VERSION "HNNBNNNYNNNNNNNNNNNNNNNNNNNNNNNNNNNNNNNNNN/4/%%%/4/'%**4NNN///"

NS_ :

BS_:

BU_: ecu_pri3_1 ecu_pri3_2 ecu_sec1_1 ecu_pri1_1 ecu_sec1_2 unused_8 unused_2 ecu_sec3_2 ecu_sec3_1 unused_1 unused_4 unused_9 unused_3 ecu_pri3_3 unused_6 unused_5 unused_7 measure

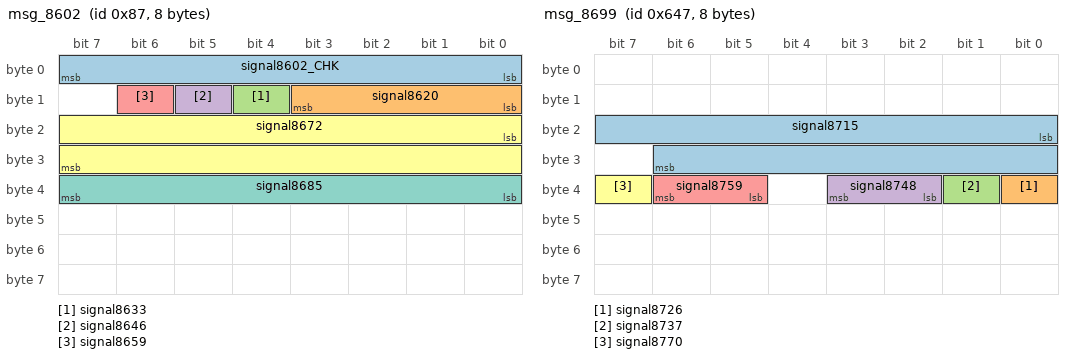
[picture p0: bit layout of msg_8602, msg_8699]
BO_ 135 msg_8602: 8 ecu_sec3_1
 SG_ signal8602_CHK : 0|8@1+ (1,0) [0|255] ""  ecu_sec1_2,unused_8,unused_2,measure
 SG_ signal8620 : 8|4@1+ (1,0) [0|15] ""  ecu_sec1_2,unused_8,unused_2,measure
 SG_ signal8633 : 12|1@1+ (1,0) [0|1] ""  ecu_sec1_2,unused_8,unused_2,measure
 SG_ signal8646 : 13|1@1+ (1,0) [0|1] ""  ecu_sec1_2,unused_8,unused_2,measure
 SG_ signal8659 : 14|1@1+ (1,0) [0|1] ""  ecu_sec1_2,unused_8,unused_2,measure
 SG_ signal8672 : 16|16@1+ (0.25,0) [0|16383] "1/min"  ecu_sec1_2,unused_8,unused_2,measure
 SG_ signal8685 : 32|8@1+ (0.4,0) [0|101.6] "%"  ecu_sec1_2,unused_8,unused_2,measure

BO_ 1607 msg_8699: 8 ecu_sec3_1
 SG_ signal8715 : 16|15@1- (1,0) [0|32766] ""  ecu_pri1_1,measure
 SG_ signal8726 : 32|1@1+ (1,0) [0|1] ""  ecu_pri1_1,measure
 SG_ signal8737 : 33|1@1+ (1,0) [0|1] ""  ecu_pri1_1,measure
 SG_ signal8748 : 34|2@1+ (1,0) [0|3] ""  ecu_pri1_1,measure
 SG_ signal8759 : 37|2@1+ (1,0) [0|3] ""  ecu_pri1_1,measure
 SG_ signal8770 : 39|1@1- (1,0) [0|1] ""  ecu_pri1_1,measure

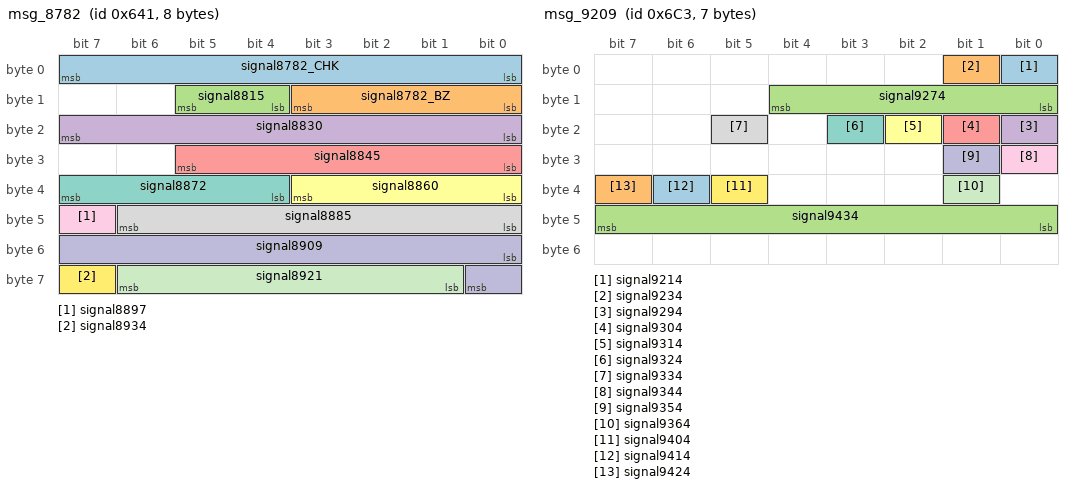
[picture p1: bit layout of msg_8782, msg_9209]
BO_ 1601 msg_8782: 8 ecu_sec3_1
 SG_ signal8782_CHK : 0|8@1+ (1,0) [0|255] ""  ecu_pri1_1,ecu_sec1_2,unused_8,unused_2,measure
 SG_ signal8782_BZ : 8|4@1+ (1,0) [0|15] ""  ecu_pri1_1,ecu_sec1_2,unused_8,unused_2,measure
 SG_ signal8815 : 12|2@1+ (1,0) [0|3] ""  ecu_pri3_2,ecu_pri1_1,ecu_sec1_2,unused_8,unused_2,measure
 SG_ signal8830 : 16|8@1+ (1,0) [0|255] ""  ecu_pri3_2,ecu_pri1_1,ecu_sec1_2,unused_8,unused_2,measure
 SG_ signal8845 : 24|6@1+ (1,0) [0|63] ""  ecu_pri3_2,ecu_pri1_1,ecu_sec1_2,unused_8,unused_2,measure
 SG_ signal8860 : 32|4@1+ (1,0) [0|15] ""  ecu_pri3_2,ecu_pri1_1,measure
 SG_ signal8872 : 36|4@1+ (1,0) [0|15] ""  ecu_pri3_2,ecu_pri1_1,unused_6,measure
 SG_ signal8885 : 40|7@1+ (0.1,0) [0|12.7] "l"  ecu_pri3_2,ecu_pri1_1,measure
 SG_ signal8897 : 47|1@1+ (1,0) [0|1] ""  ecu_pri3_2,ecu_pri1_1,measure
 SG_ signal8909 : 48|9@1+ (1,0) [0|511] "kW"  ecu_pri3_2,ecu_pri1_1,measure
 SG_ signal8921 : 57|6@1+ (1,0) [0|63] ""  ecu_pri1_1,ecu_sec1_2,unused_8,measure
 SG_ signal8934 : 63|1@1+ (1,0) [0|1] ""  ecu_pri1_1,measure

BO_ 1090 msg_8946: 1 unused_9
 SG_ signal8951 : 0|1@1+ (1,0) [0|1] ""  ecu_pri1_1,measure

BO_ 1753 msg_8963: 7 ecu_pri3_2
 SG_ signal9108 : 24|1@1+ (1,0) [0|1] ""  unused_7,measure
 SG_ signal9168 : 36|1@1+ (1,0) [0|1] ""  unused_7,measure

BO_ 1731 msg_9209: 7 ecu_sec1_1
 SG_ signal9214 : 0|1@1+ (1,0) [0|1] ""  ecu_pri3_2,ecu_sec1_1,ecu_pri1_1,ecu_sec1_2,unused_8,unused_2,ecu_sec3_1,unused_1,unused_4,unused_6,measure
 SG_ signal9234 : 1|1@1+ (1,0) [0|1] ""  unused_7,measure
 SG_ signal9274 : 8|5@1+ (1,0) [0|31] ""  unused_7,measure
 SG_ signal9294 : 16|1@1+ (1,0) [0|1] ""  unused_7,measure
 SG_ signal9304 : 17|1@1+ (1,0) [0|1] ""  unused_7,measure
 SG_ signal9314 : 18|1@1+ (1,0) [0|1] ""  unused_7,measure
 SG_ signal9324 : 19|1@1+ (1,0) [0|1] ""  unused_7,measure
 SG_ signal9334 : 21|1@1+ (1,0) [0|1] ""  unused_7,measure
 SG_ signal9344 : 24|1@1+ (1,0) [0|1] ""  unused_7,measure
 SG_ signal9354 : 25|1@1+ (1,0) [0|1] ""  unused_7,measure
 SG_ signal9364 : 33|1@1+ (1,0) [0|1] ""  unused_7,measure
 SG_ signal9404 : 37|1@1+ (1,0) [0|1] ""  unused_7,measure
 SG_ signal9414 : 38|1@1+ (1,0) [0|1] ""  unused_7,measure
 SG_ signal9424 : 39|1@1+ (1,0) [0|1] ""  unused_7,measure
 SG_ signal9434 : 40|8@1+ (1,0) [0|255] ""  unused_7,measure

BO_ 1728 msg_9445: 7 ecu_pri1_1
 SG_ signal9450 : 0|1@1+ (1,0) [0|1] ""  ecu_pri3_2,ecu_sec1_1,ecu_pri1_1,ecu_sec1_2,unused_8,unused_2,ecu_sec3_1,unused_1,unused_4,unused_6,measure
 SG_ signal9470 : 1|1@1+ (1,0) [0|1] ""  unused_7,measure
 SG_ signal9480 : 2|1@1+ (1,0) [0|1] ""  unused_7,measure
 SG_ signal9490 : 3|1@1+ (1,0) [0|1] ""  unused_7,measure
 SG_ signal9500 : 6|1@1+ (1,0) [0|1] ""  unused_7,measure
 SG_ signal9510 : 8|5@1+ (1,0) [0|31] ""  unused_7,measure
 SG_ signal9520 : 13|3@1+ (1,0) [0|7] ""  unused_7,measure
 SG_ signal9530 : 16|1@1+ (1,0) [0|1] ""  unused_7,measure
 SG_ signal9540 : 17|1@1+ (1,0) [0|1] ""  unused_7,measure
 SG_ signal9550 : 18|1@1+ (1,0) [0|1] ""  unused_7,measure
 SG_ signal9560 : 19|1@1+ (1,0) [0|1] ""  unused_7,measure
 SG_ signal9570 : 20|1@1+ (1,0) [0|1] ""  unused_7,measure
 SG_ signal9580 : 21|1@1+ (1,0) [0|1] ""  unused_7,measure
 SG_ signal9590 : 24|1@1+ (1,0) [0|1] ""  unused_7,measure
 SG_ signal9600 : 25|1@1+ (1,0) [0|1] ""  unused_7,measure
 SG_ signal9610 : 26|1@1+ (1,0) [0|1] ""  unused_7,measure
 SG_ signal9620 : 33|1@1+ (1,0) [0|1] ""  unused_7,measure
 SG_ signal9630 : 34|1@1+ (1,0) [0|1] ""  unused_7,measure
 SG_ signal9640 : 35|1@1+ (1,0) [0|1] ""  unused_7,measure
 SG_ signal9650 : 36|1@1+ (1,0) [0|1] ""  unused_7,measure
 SG_ signal9660 : 37|1@1+ (1,0) [0|1] ""  unused_7,measure
 SG_ signal9670 : 38|1@1+ (1,0) [0|1] ""  unused_7,measure
 SG_ signal9680 : 39|1@1+ (1,0) [0|1] ""  unused_7,measure
 SG_ signal9690 : 40|1@1+ (1,0) [0|1] ""  unused_7,measure
 SG_ signal9700 : 41|1@1+ (1,0) [0|1] ""  unused_7,measure
 SG_ signal9710 : 42|1@1+ (1,0) [0|1] ""  unused_7,measure
 SG_ signal9720 : 43|1@1+ (1,0) [0|1] ""  unused_7,measure
 SG_ signal9730 : 48|3@1+ (1,0) [0|7] ""  unused_7,measure

BO_ 1730 msg_9741: 7 ecu_sec1_2
 SG_ signal9746 : 0|1@1+ (1,0) [0|1] ""  ecu_pri3_2,ecu_sec1_1,ecu_pri1_1,ecu_sec1_2,unused_8,unused_2,ecu_sec3_1,unused_1,unused_4,unused_6,measure
 SG_ signal9766 : 1|1@1+ (1,0) [0|1] ""  unused_7,measure
 SG_ signal9776 : 2|1@1+ (1,0) [0|1] ""  unused_7,measure
 SG_ signal9786 : 3|1@1+ (1,0) [0|1] ""  unused_7,measure
 SG_ signal9796 : 6|1@1+ (1,0) [0|1] ""  unused_7,measure
 SG_ signal9806 : 8|5@1+ (1,0) [0|31] ""  unused_7,measure
 SG_ signal9816 : 13|3@1+ (1,0) [0|7] ""  unused_7,measure
 SG_ signal9826 : 16|1@1+ (1,0) [0|1] ""  unused_7,measure
 SG_ signal9836 : 17|1@1+ (1,0) [0|1] ""  unused_7,measure
 SG_ signal9846 : 18|1@1+ (1,0) [0|1] ""  unused_7,measure
 SG_ signal9856 : 24|1@1+ (1,0) [0|1] ""  unused_7,measure
 SG_ signal9866 : 25|1@1+ (1,0) [0|1] ""  unused_7,measure
 SG_ signal9876 : 26|1@1+ (1,0) [0|1] ""  unused_7,measure
 SG_ signal9886 : 27|1@1+ (1,0) [0|1] ""  unused_7,measure
 SG_ signal9896 : 28|1@1+ (1,0) [0|1] ""  unused_7,measure
 SG_ signal9906 : 29|1@1+ (1,0) [0|1] ""  unused_7,measure
 SG_ signal9916 : 33|1@1+ (1,0) [0|1] ""  unused_7,measure
 SG_ signal9926 : 34|1@1+ (1,0) [0|1] ""  unused_7,measure
 SG_ signal9936 : 35|1@1+ (1,0) [0|1] ""  unused_7,measure
 SG_ signal9946 : 36|1@1+ (1,0) [0|1] ""  unused_7,measure
 SG_ signal9956 : 37|1@1+ (1,0) [0|1] ""  unused_7,measure
 SG_ signal9966 : 38|1@1+ (1,0) [0|1] ""  unused_7,measure
 SG_ signal9976 : 39|1@1+ (1,0) [0|1] ""  unused_7,measure

BO_ 1729 msg_9987: 7 ecu_sec3_1
 SG_ signal9992 : 0|1@1+ (1,0) [0|1] ""  ecu_pri3_2,ecu_sec1_1,ecu_pri1_1,ecu_sec1_2,unused_8,unused_2,ecu_sec3_1,unused_1,unused_4,unused_6,measure
 SG_ signal10012 : 1|1@1+ (1,0) [0|1] ""  unused_7,measure
 SG_ signal10022 : 2|1@1+ (1,0) [0|1] ""  unused_7,measure
 SG_ signal10032 : 3|1@1+ (1,0) [0|1] ""  unused_7,measure
 SG_ signal10042 : 6|1@1+ (1,0) [0|1] ""  unused_7,measure
 SG_ signal10052 : 8|5@1+ (1,0) [0|31] ""  unused_7,measure
 SG_ signal10062 : 13|3@1+ (1,0) [0|7] ""  unused_7,measure
 SG_ signal10072 : 16|1@1+ (1,0) [0|1] ""  unused_7,measure
 SG_ signal10082 : 17|1@1+ (1,0) [0|1] ""  unused_7,measure
 SG_ signal10092 : 18|1@1+ (1,0) [0|1] ""  unused_7,measure
 SG_ signal10102 : 19|1@1+ (1,0) [0|1] ""  unused_7,measure
 SG_ signal10112 : 20|1@1+ (1,0) [0|1] ""  unused_7,measure
 SG_ signal10122 : 24|1@1+ (1,0) [0|1] ""  unused_7,measure
 SG_ signal10132 : 25|1@1+ (1,0) [0|1] ""  unused_7,measure
 SG_ signal10142 : 26|1@1+ (1,0) [0|1] ""  unused_7,measure
 SG_ signal10152 : 27|1@1+ (1,0) [0|1] ""  unused_7,measure
 SG_ signal10172 : 29|1@1+ (1,0) [0|1] ""  unused_7,measure
 SG_ signal10182 : 33|1@1+ (1,0) [0|1] ""  unused_7,measure
 SG_ signal10192 : 34|1@1+ (1,0) [0|1] ""  unused_7,measure
 SG_ signal10202 : 35|1@1+ (1,0) [0|1] ""  unused_7,measure
 SG_ signal10212 : 36|1@1+ (1,0) [0|1] ""  unused_7,measure
 SG_ signal10222 : 37|1@1+ (1,0) [0|1] ""  unused_7,measure
 SG_ signal10232 : 38|1@1+ (1,0) [0|1] ""  unused_7,measure
 SG_ signal10242 : 39|1@1+ (1,0) [0|1] ""  unused_7,measure

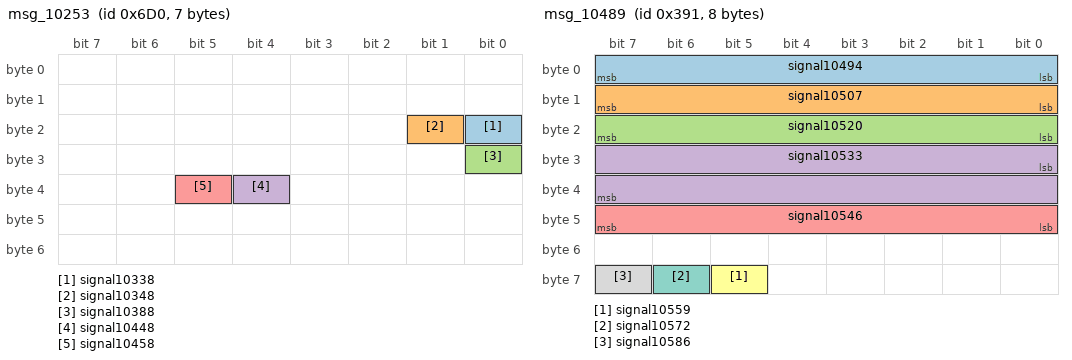
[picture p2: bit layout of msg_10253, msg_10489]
BO_ 1744 msg_10253: 7 unused_6
 SG_ signal10338 : 16|1@1+ (1,0) [0|1] ""  unused_7,measure
 SG_ signal10348 : 17|1@1+ (1,0) [0|1] ""  unused_7,measure
 SG_ signal10388 : 24|1@1+ (1,0) [0|1] ""  unused_7,measure
 SG_ signal10448 : 36|1@1+ (1,0) [0|1] ""  unused_7,measure
 SG_ signal10458 : 37|1@1+ (1,0) [0|1] ""  unused_7,measure

BO_ 913 msg_10489: 8 ecu_sec3_1
 SG_ signal10494 : 0|8@1+ (0.39215686275,0) [0|99.99825] "%"  ecu_sec1_2,unused_8,unused_2,measure
 SG_ signal10507 : 8|8@1+ (1,-40) [-40|215] "Celsius"  ecu_sec1_2,unused_8,unused_2,measure
 SG_ signal10520 : 16|8@1+ (0.39215686275,0) [0|99.99825] "%"  ecu_sec1_2,unused_8,unused_2,measure
 SG_ signal10533 : 24|16@1+ (0.39215686275,0) [0|25699.55025] "%"  ecu_sec1_2,unused_8,unused_2,measure
 SG_ signal10546 : 40|8@1+ (0.39215686275,0) [0|99.99825] "%"  ecu_sec1_2,unused_8,unused_2,measure
 SG_ signal10559 : 61|1@1+ (1,0) [0|1] ""  ecu_sec1_2,unused_8,unused_2,measure
 SG_ signal10572 : 62|1@1+ (1,0) [0|1] ""  ecu_pri1_1,ecu_sec1_2,unused_8,unused_2,measure
 SG_ signal10586 : 63|1@1+ (1,0) [0|1] ""  ecu_sec1_2,unused_8,unused_2,measure

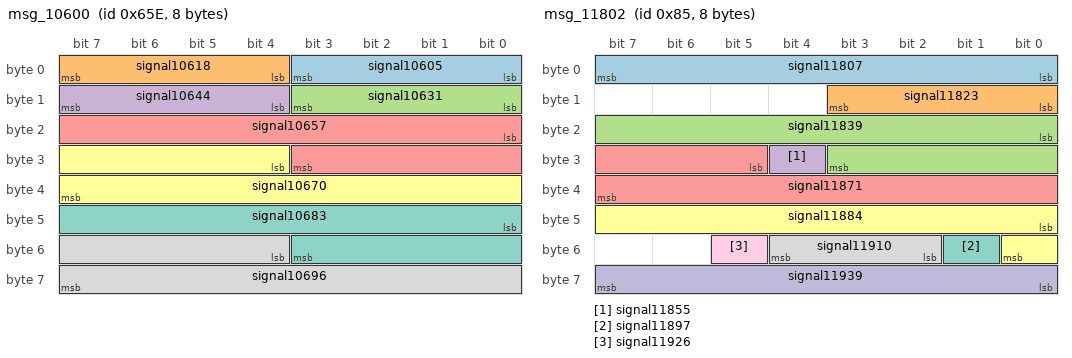
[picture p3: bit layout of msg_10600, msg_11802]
BO_ 1630 msg_10600: 8 ecu_pri1_1
 SG_ signal10605 : 0|4@1+ (1,0) [0|15] ""  ecu_sec3_1,unused_1,unused_4,measure
 SG_ signal10618 : 4|4@1+ (1,0) [0|15] ""  ecu_sec3_1,unused_1,unused_4,measure
 SG_ signal10631 : 8|4@1+ (1,0) [0|15] ""  ecu_sec3_1,unused_1,unused_4,measure
 SG_ signal10644 : 12|4@1+ (1,0) [0|15] ""  ecu_sec3_1,unused_1,unused_4,measure
 SG_ signal10657 : 16|12@1+ (0.5,0) [0|2047.5] "Ohm"  ecu_sec3_1,unused_1,unused_4,measure
 SG_ signal10670 : 28|12@1+ (0.5,0) [0|2047.5] "Ohm"  ecu_sec3_1,unused_1,unused_4,measure
 SG_ signal10683 : 40|12@1+ (0.5,0) [0|2047.5] "Ohm"  ecu_sec3_1,unused_1,unused_4,measure
 SG_ signal10696 : 52|12@1+ (0.5,0) [0|2047.5] "Ohm"  ecu_sec3_1,unused_1,unused_4,measure

BO_ 929 msg_10710: 8 ecu_pri1_1
 SG_ signal10715 : 0|6@1+ (1,0) [0|63] ""  ecu_sec1_2,unused_8,unused_2,measure
 SG_ signal10728 : 6|7@1+ (1,0) [0|127] ""  ecu_sec1_2,unused_8,unused_2,measure
 SG_ signal10741 : 13|5@1+ (1,0) [0|31] ""  ecu_sec1_2,unused_8,unused_2,measure
 SG_ signal10754 : 18|1@1+ (1,0) [0|1] ""  ecu_sec1_2,unused_8,unused_2,measure
 SG_ signal10767 : 19|3@1+ (1,0) [0|7] ""  ecu_sec1_2,unused_8,unused_2,measure
 SG_ signal10780 : 22|6@1+ (1,0) [0|63] ""  ecu_sec1_2,unused_8,unused_2,measure
 SG_ signal10793 : 28|6@1+ (1,0) [0|63] ""  ecu_sec1_2,unused_8,unused_2,measure
 SG_ signal10806 : 34|2@1+ (1,0) [0|3] ""  ecu_sec1_2,unused_8,unused_2,measure
 SG_ signal10819 : 36|7@1+ (1,0) [0|127] ""  ecu_sec1_2,unused_8,unused_2,measure
 SG_ signal10832 : 43|2@1+ (1,0) [0|3] ""  ecu_sec1_2,unused_8,unused_2,measure
 SG_ signal10845 : 45|8@1+ (1,0) [0|255] ""  ecu_sec1_2,unused_8,unused_2,measure
 SG_ signal10858 : 53|1@1+ (1,0) [0|1] ""  ecu_sec1_2,unused_8,unused_2,measure
 SG_ signal10871 : 54|5@1+ (1,0) [0|31] ""  ecu_sec1_2,unused_8,unused_2,measure
 SG_ signal10884 : 59|1@1+ (1,0) [0|1] ""  ecu_sec1_2,unused_8,unused_2,measure
 SG_ signal10897 : 60|1@1+ (1,0) [0|1] ""  ecu_sec1_2,unused_8,unused_2,measure
 SG_ signal10910 : 61|2@1+ (1,0) [0|3] ""  ecu_sec1_2,unused_8,unused_2,measure
 SG_ signal10923 : 63|1@1+ (1,0) [0|1] ""  ecu_sec1_2,unused_8,unused_2,measure

BO_ 930 msg_10937: 8 ecu_pri1_1
 SG_ signal10942 M : 0|2@1+ (1,0) [0|3] ""  ecu_sec1_2,unused_8,unused_2,measure
 SG_ signal10956 m0 : 2|6@1+ (1,0) [0|63] ""  ecu_sec1_2,unused_8,unused_2,measure
 SG_ signal10970 m1 : 2|6@1+ (1,0) [0|63] ""  ecu_sec1_2,unused_8,unused_2,measure
 SG_ signal10984 m2 : 2|6@1+ (1,0) [0|63] ""  ecu_sec1_2,unused_8,unused_2,measure
 SG_ signal10998 m3 : 2|6@1+ (1,0) [0|63] ""  ecu_sec1_2,unused_8,unused_2,measure
 SG_ signal11012 m0 : 8|8@1+ (1,0) [0|255] ""  ecu_sec1_2,unused_8,unused_2,measure
 SG_ signal11026 m1 : 8|7@1+ (1,0) [0|127] ""  ecu_sec1_2,unused_8,unused_2,measure
 SG_ signal11040 m2 : 8|5@1+ (1,0) [0|31] ""  ecu_sec1_2,unused_8,unused_2,measure
 SG_ signal11054 m3 : 8|2@1+ (1,0) [0|3] ""  ecu_sec1_2,unused_8,unused_2,measure
 SG_ signal11068 m3 : 10|10@1+ (1,0) [0|1023] ""  ecu_sec1_2,unused_8,unused_2,measure
 SG_ signal11110 m1 : 15|6@1+ (1,0) [0|63] ""  ecu_sec1_2,unused_8,unused_2,measure
 SG_ signal11138 m0 : 16|1@1+ (1,0) [0|1] ""  ecu_sec1_2,unused_8,unused_2,measure
 SG_ signal11152 m0 : 17|1@1+ (1,0) [0|1] ""  ecu_sec1_2,unused_8,unused_2,measure
 SG_ signal11180 m0 : 18|4@1+ (1,0) [0|15] ""  ecu_sec1_2,unused_8,unused_2,measure
 SG_ signal11208 m3 : 20|1@1+ (1,0) [0|1] ""  ecu_sec1_2,unused_8,unused_2,measure
 SG_ signal11222 m1 : 21|5@1+ (1,0) [0|31] ""  ecu_sec1_2,unused_8,unused_2,measure
 SG_ signal11236 m3 : 21|2@1+ (1,0) [0|3] ""  ecu_sec1_2,unused_8,unused_2,measure
 SG_ signal11250 m0 : 22|5@1+ (1,0) [0|31] ""  ecu_sec1_2,unused_8,unused_2,measure
 SG_ signal11278 m3 : 23|5@1+ (1,0) [0|31] ""  ecu_sec1_2,unused_8,unused_2,measure
 SG_ signal11292 m1 : 26|1@1+ (1,0) [0|1] ""  ecu_sec1_2,unused_8,unused_2,measure
 SG_ signal11306 m0 : 27|19@1+ (1,0) [0|524287] ""  ecu_sec1_2,unused_8,unused_2,measure
 SG_ signal11320 m1 : 27|2@1+ (1,0) [0|3] ""  ecu_sec1_2,unused_8,unused_2,measure
 SG_ signal11278_Typ m3 : 28|1@1+ (1,0) [0|1] ""  ecu_sec1_2,unused_8,unused_2,measure
 SG_ signal11362 m1 : 29|1@1+ (1,0) [0|1] ""  ecu_sec1_2,unused_8,unused_2,measure
 SG_ signal11376 m3 : 29|5@1+ (1,0) [0|31] ""  ecu_sec1_2,unused_8,unused_2,measure
 SG_ signal11390 m1 : 30|1@1+ (1,0) [0|1] ""  ecu_sec1_2,unused_8,unused_2,measure
 SG_ signal11404 m1 : 31|4@1+ (1,0) [0|15] ""  ecu_sec1_2,unused_8,unused_2,measure
 SG_ signal11418 m2 : 33|5@1+ (1,0) [0|31] ""  ecu_sec1_2,unused_8,unused_2,measure
 SG_ signal11432 m1 : 35|2@1+ (1,0) [0|3] ""  ecu_sec1_2,unused_8,unused_2,measure
 SG_ signal11446 m1 : 37|8@1+ (1,0) [0|255] ""  ecu_sec1_2,unused_8,unused_2,measure
 SG_ signal11460 m2 : 38|1@1+ (1,0) [0|1] ""  ecu_sec1_2,unused_8,unused_2,measure
 SG_ signal11516 m1 : 45|1@1+ (1,0) [0|1] ""  ecu_sec1_2,unused_8,unused_2,measure
 SG_ signal11530 m0 : 46|8@1+ (1,0) [0|255] ""  ecu_sec1_2,unused_8,unused_2,measure
 SG_ signal11544 m1 : 46|8@1+ (1,0) [0|255] ""  ecu_sec1_2,unused_8,unused_2,measure
 SG_ signal11586 m0 : 54|1@1+ (1,0) [0|1] ""  ecu_sec1_2,unused_8,unused_2,measure
 SG_ signal11544_Vorz m1 : 54|1@1+ (1,0) [0|1] ""  ecu_sec1_2,unused_8,unused_2,measure
 SG_ signal11614 m0 : 55|5@1+ (1,0) [0|31] ""  ecu_sec1_2,unused_8,unused_2,measure
 SG_ signal11628 m1 : 55|5@1+ (1,0) [0|31] ""  ecu_sec1_2,unused_8,unused_2,measure
 SG_ signal11642 m2 : 57|2@1+ (1,0) [0|3] ""  ecu_sec1_2,unused_8,unused_2,measure
 SG_ signal11656 m2 : 59|3@1+ (1,0) [0|7] ""  ecu_sec1_2,unused_8,unused_2,measure
 SG_ signal11614_Vorz m0 : 60|1@1+ (1,0) [0|1] ""  ecu_sec1_2,unused_8,unused_2,measure
 SG_ signal11684 m1 : 60|1@1+ (1,0) [0|1] ""  ecu_sec1_2,unused_8,unused_2,measure
 SG_ signal11698 m0 : 61|1@1+ (1,0) [0|1] ""  ecu_sec1_2,unused_8,unused_2,measure
 SG_ signal11712 m1 : 61|2@1+ (1,0) [0|3] ""  ecu_sec1_2,unused_8,unused_2,measure
 SG_ signal11726 m0 : 62|1@1+ (1,0) [0|1] ""  ecu_sec1_2,unused_8,unused_2,measure
 SG_ signal11740 m0 : 63|1@1+ (1,0) [0|1] ""  ecu_sec1_2,unused_8,unused_2,measure
 SG_ signal11754 m1 : 63|1@1+ (1,0) [0|1] ""  ecu_sec1_2,unused_8,unused_2,measure

BO_ 2033 msg_11769: 8 unused_7
 SG_ signal11769 : 0|64@1+ (1,0) [0|4294967295] ""  ecu_pri3_1,measure

BO_ 2041 msg_11786: 8 ecu_pri3_1
 SG_ signal11786 : 0|64@1+ (1,0) [0|1] ""  unused_7,measure

BO_ 133 msg_11802: 8 ecu_pri3_3
 SG_ signal11807 : 0|8@1+ (1,0) [0|255] ""  ecu_sec1_1,ecu_pri1_1,ecu_sec3_1,unused_1,unused_4,unused_3,measure
 SG_ signal11823 : 8|4@1+ (1,0) [0|15] ""  ecu_sec1_1,ecu_pri1_1,ecu_sec3_1,unused_1,unused_4,unused_3,measure
 SG_ signal11839 : 16|12@1+ (0.1,0) [0|409.3] "Degr"  ecu_sec1_1,ecu_pri1_1,ecu_sec3_1,unused_1,unused_4,unused_3,measure
 SG_ signal11855 : 28|1@1+ (1,0) [0|1] ""  ecu_sec1_1,ecu_pri1_1,ecu_sec3_1,unused_1,unused_4,unused_3,measure
 SG_ signal11871 : 29|11@1+ (0.1,0) [0|204.5] "Degr"  ecu_sec1_1,ecu_pri1_1,unused_3,measure
 SG_ signal11884 : 40|9@1+ (1,0) [0|510] ""  ecu_sec1_1,ecu_pri1_1,unused_3,measure
 SG_ signal11897 : 49|1@1+ (1,0) [0|1] ""  ecu_sec1_1,ecu_pri1_1,unused_3,measure
 SG_ signal11910 : 50|3@1+ (1,0) [0|7] ""  ecu_sec1_1,ecu_pri1_1,ecu_sec3_1,unused_1,unused_4,unused_3,measure
 SG_ signal11926 : 53|1@1+ (1,0) [0|1] ""  ecu_sec1_1,ecu_pri1_1,unused_3,measure
 SG_ signal11939 : 56|8@1+ (1,0) [0|255] ""  ecu_sec1_1,ecu_pri1_1,unused_3,measure

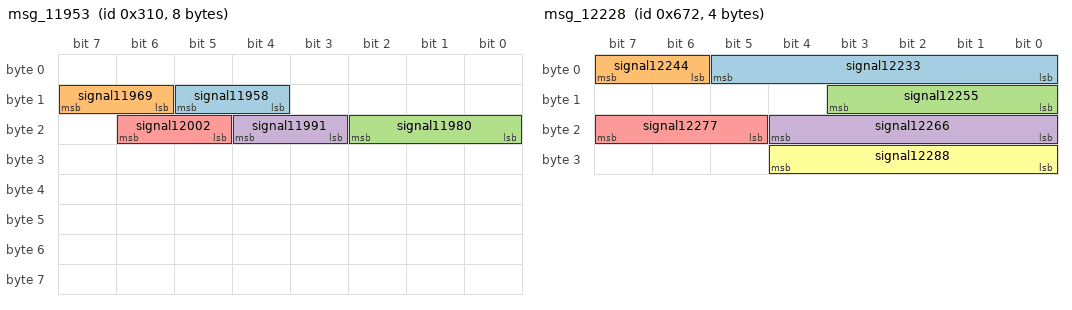
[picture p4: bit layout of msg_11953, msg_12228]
BO_ 784 msg_11953: 8 ecu_pri3_3
 SG_ signal11958 : 12|2@1+ (1,0) [0|3] ""  ecu_pri1_1,measure
 SG_ signal11969 : 14|2@1+ (1,0) [0|3] ""  ecu_pri1_1,measure
 SG_ signal11980 : 16|3@1+ (1,0) [0|7] ""  ecu_pri1_1,measure
 SG_ signal11991 : 19|2@1+ (1,0) [0|3] ""  ecu_pri1_1,measure
 SG_ signal12002 : 21|2@1+ (1,0) [0|3] ""  ecu_pri1_1,measure

BO_ 1313 msg_12014: 8 unused_6
 SG_ signal12019 : 0|1@1+ (1,0) [0|1] ""  ecu_pri1_1,measure
 SG_ signal12030 : 1|1@1+ (1,0) [0|1] ""  ecu_pri1_1,measure
 SG_ signal12041 : 2|1@1+ (1,0) [0|1] ""  ecu_pri1_1,measure
 SG_ signal12052 : 3|1@1+ (1,0) [0|1] ""  ecu_pri1_1,measure
 SG_ signal12063 : 4|1@1+ (1,0) [0|1] ""  ecu_pri1_1,measure
 SG_ signal12074 : 5|1@1+ (1,0) [0|1] ""  ecu_pri1_1,measure
 SG_ signal12085 : 6|1@1+ (1,0) [0|1] ""  ecu_pri1_1,ecu_sec3_1,unused_4,measure
 SG_ signal12098 : 8|6@1+ (1,0) [0|63] "min"  ecu_pri1_1,ecu_sec3_1,unused_4,measure
 SG_ signal12111 : 16|6@1+ (1,0) [0|63] ""  ecu_pri1_1,ecu_sec3_1,unused_4,measure
 SG_ signal12124 : 24|13@1+ (1,0) [0|8191] "ml"  ecu_pri1_1,measure
 SG_ signal12135 : 37|3@1+ (1,0) [0|7] ""  ecu_pri1_1,measure
 SG_ signal12146 : 40|8@1+ (1,0) [0|255] ""  ecu_pri1_1,measure
 SG_ signal12157 : 48|8@1+ (0.75,-40) [-40|142.25] "Celsius"  ecu_pri1_1,measure
 SG_ signal12168 : 59|1@1+ (1,0) [0|1] ""  ecu_pri1_1,ecu_sec3_1,unused_4,measure
 SG_ signal12181 : 60|1@1+ (1,0) [0|1] ""  ecu_pri1_1,measure
 SG_ signal12192 : 61|1@1+ (1,0) [0|1] ""  ecu_pri1_1,ecu_sec3_1,unused_4,measure
 SG_ signal12205 : 62|1@1+ (1,0) [0|1] ""  ecu_pri1_1,measure
 SG_ signal12216 : 63|1@1+ (1,0) [0|1] ""  ecu_pri1_1,measure

BO_ 1650 msg_12228: 4 unused_6
 SG_ signal12233 : 0|6@1+ (1,0) [0|63] ""  ecu_pri1_1,measure
 SG_ signal12244 : 6|2@1+ (1,0) [0|3] ""  ecu_pri1_1,measure
 SG_ signal12255 : 8|4@1+ (1,0) [0|15] ""  ecu_pri1_1,measure
 SG_ signal12266 : 16|5@1+ (1,0) [0|31] ""  ecu_pri1_1,measure
 SG_ signal12277 : 21|3@1+ (1,0) [0|7] ""  ecu_pri1_1,measure
 SG_ signal12288 : 24|5@1+ (1,0) [0|31] "Tag"  ecu_pri1_1,measure

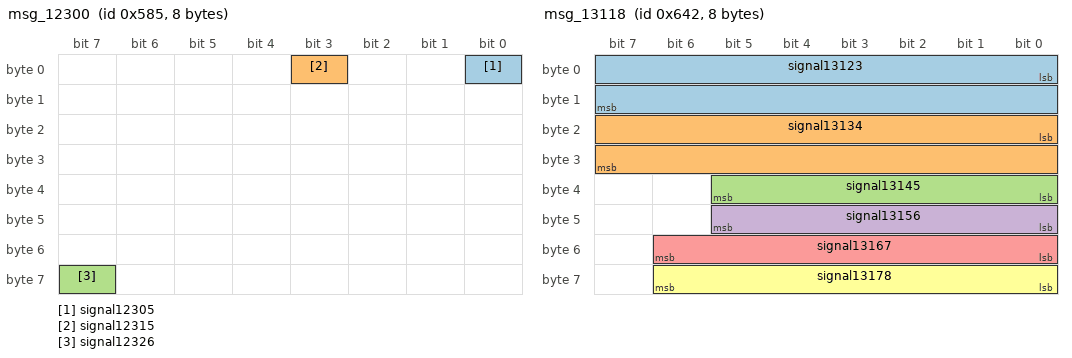
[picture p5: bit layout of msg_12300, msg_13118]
BO_ 1413 msg_12300: 8 ecu_pri1_1
 SG_ signal12305 : 0|1@1+ (1,0) [0|1] ""  unused_7,measure
 SG_ signal12315 : 3|1@1+ (1,0) [0|1] ""  unused_6,measure
 SG_ signal12326 : 63|1@1+ (1,0) [0|1] ""  unused_7,measure

BO_ 1209 msg_12337: 8 ecu_pri1_1
 SG_ signal12342 : 0|64@1+ (1,0) [0|1] ""  ecu_pri3_2,measure

BO_ 1215 msg_12371: 8 unused_6
 SG_ signal12376 : 0|64@1+ (1,0) [0|1] ""  ecu_pri1_1,measure

BO_ 1303 msg_12388: 8 unused_6
 SG_ signal12393 : 0|64@1+ (1,0) [0|1] ""  ecu_pri1_1,measure

BO_ 1214 msg_12405: 8 ecu_pri1_1
 SG_ signal12410 : 0|64@1+ (1,0) [0|1] ""  ecu_pri3_3,measure

BO_ 1231 msg_12422: 8 ecu_pri1_1
 SG_ signal12427 : 0|64@1+ (1,0) [0|1] ""  unused_6,measure

BO_ 768 msg_12456: 8 ecu_pri3_2
 SG_ signal12461 : 0|64@1+ (1,0) [0|1] ""  ecu_pri1_1,measure

BO_ 769 msg_12473: 8 ecu_pri3_2
 SG_ signal12478 : 0|64@1+ (1,0) [0|1] ""  ecu_pri1_1,measure

BO_ 770 msg_12490: 8 ecu_pri3_2
 SG_ signal12495 : 0|64@1+ (1,0) [0|1] ""  ecu_pri1_1,measure

BO_ 771 msg_12507: 8 ecu_pri3_2
 SG_ signal12512 : 0|64@1+ (1,0) [0|1] ""  ecu_pri1_1,measure

BO_ 772 msg_12524: 8 ecu_pri3_2
 SG_ signal12529 : 0|64@1+ (1,0) [0|1] ""  ecu_pri1_1,measure

BO_ 773 msg_12541: 8 ecu_pri3_2
 SG_ signal12546 : 0|64@1+ (1,0) [0|1] ""  ecu_pri1_1,measure

BO_ 774 msg_12558: 8 ecu_pri3_2
 SG_ signal12563 : 0|64@1+ (1,0) [0|1] ""  ecu_pri1_1,measure

BO_ 775 msg_12575: 8 ecu_pri3_2
 SG_ signal12580 : 0|64@1+ (1,0) [0|1] ""  ecu_pri1_1,measure

BO_ 537 msg_12592: 7 ecu_pri3_2
 SG_ signal12597 : 0|56@1+ (1,0) [0|1] ""  ecu_pri1_1,measure

BO_ 543 msg_12609: 7 ecu_pri1_1
 SG_ signal12614 : 0|56@1+ (1,0) [0|1] ""  unused_6,measure

BO_ 542 msg_12626: 7 ecu_pri3_3
 SG_ signal12631 : 0|56@1+ (1,0) [0|1] ""  ecu_pri1_1,measure

BO_ 559 msg_12643: 7 unused_6
 SG_ signal12643_Data : 0|56@1+ (1,0) [0|1] ""  ecu_pri1_1,measure

BO_ 512 msg_12660: 7 ecu_pri1_1
 SG_ signal12665 : 0|56@1+ (1,0) [0|1] ""  ecu_pri3_2,ecu_pri3_3,unused_6,measure

BO_ 1716 msg_12679: 8 ecu_pri1_1
 SG_ signal12684 M : 0|2@1+ (1,0) [0|3] ""  ecu_pri3_1,ecu_sec3_2,ecu_pri3_3,unused_6,measure
 SG_ signal12699 m0 : 8|8@1+ (1,0) [0|255] ""  ecu_pri3_1,unused_6,measure
 SG_ signal12712 m1 : 8|8@1+ (1,0) [0|255] ""  ecu_pri3_1,ecu_sec3_2,unused_6,measure
 SG_ signal128641 m2 : 8|8@1+ (1,0) [0|255] ""  ecu_pri3_1,ecu_sec3_2,unused_6,measure
 SG_ signal12740 m0 : 16|8@1+ (1,0) [0|255] ""  ecu_pri3_1,unused_6,measure
 SG_ signal12753 m1 : 16|8@1+ (1,0) [0|255] ""  ecu_pri3_1,ecu_sec3_2,unused_6,measure
 SG_ signal12767 m2 : 16|8@1+ (1,0) [0|255] ""  ecu_pri3_1,ecu_sec3_2,unused_6,measure
 SG_ signal12781 m0 : 24|8@1+ (1,0) [0|255] ""  ecu_pri3_1,unused_6,measure
 SG_ signal12794 m1 : 24|8@1+ (1,0) [0|255] ""  ecu_pri3_1,ecu_sec3_2,unused_6,measure
 SG_ signal128643 m2 : 24|8@1+ (1,0) [0|255] ""  ecu_pri3_1,ecu_sec3_2,unused_6,measure
 SG_ signal12822 m0 : 32|8@1+ (1,0) [0|255] ""  ecu_pri3_1,unused_6,measure
 SG_ signal12835 m1 : 32|8@1+ (1,0) [0|255] ""  ecu_pri3_1,ecu_sec3_2,unused_6,measure
 SG_ signal12849 m2 : 32|8@1+ (1,0) [0|255] ""  ecu_pri3_1,ecu_sec3_2,ecu_pri3_3,unused_6,measure
 SG_ signal12864 m0 : 40|8@1+ (1,0) [0|255] ""  ecu_pri3_1,ecu_sec3_2,unused_6,measure
 SG_ signal12878 m1 : 40|8@1+ (1,0) [0|255] ""  ecu_pri3_1,ecu_sec3_2,unused_6,measure
 SG_ signal128645 m2 : 40|8@1+ (1,0) [0|255] ""  ecu_pri3_1,ecu_sec3_2,ecu_pri3_3,unused_6,measure
 SG_ signal12907 m0 : 48|8@1+ (1,0) [0|255] ""  ecu_pri3_1,ecu_sec3_2,unused_6,measure
 SG_ signal12921 m1 : 48|8@1+ (1,0) [0|255] ""  ecu_pri3_1,ecu_sec3_2,unused_6,measure
 SG_ signal128646 m2 : 48|8@1+ (1,0) [0|255] ""  ecu_pri3_1,ecu_sec3_2,ecu_pri3_3,unused_6,measure
 SG_ signal12950 m0 : 56|8@1+ (1,0) [0|255] ""  ecu_pri3_1,ecu_sec3_2,unused_6,measure
 SG_ signal128640 m1 : 56|8@1+ (1,0) [0|255] ""  ecu_pri3_1,ecu_sec3_2,unused_6,measure
 SG_ signal128647 m2 : 56|8@1+ (1,0) [0|255] ""  ecu_pri3_1,ecu_sec3_2,ecu_pri3_3,unused_6,measure

BO_ 912 msg_12994: 4 ecu_sec1_2
 SG_ signal12999 M : 0|1@1+ (1,0) [0|1] ""  ecu_pri1_1,measure
 SG_ signal13011 m0 : 1|4@1+ (1,0) [0|15] ""  ecu_pri1_1,measure
 SG_ signal13023 m0 : 8|4@1+ (1,0) [0|15] ""  ecu_pri1_1,measure
 SG_ signal13035 m1 : 8|4@1+ (1,0) [0|15] ""  ecu_pri1_1,measure
 SG_ signal13047 m0 : 12|4@1+ (1,0) [0|15] ""  ecu_pri1_1,measure
 SG_ signal13059 m1 : 12|4@1+ (1,0) [0|15] ""  ecu_pri1_1,measure
 SG_ signal13071 : 16|1@1+ (1,0) [0|1] ""  ecu_pri1_1,measure
 SG_ signal13082 m0 : 17|1@1+ (1,0) [0|1] ""  ecu_pri1_1,measure
 SG_ signal13094 m1 : 18|1@1+ (1,0) [0|1] ""  ecu_pri1_1,measure
 SG_ signal13106 : 21|3@1+ (1,0) [0|7] ""  ecu_pri1_1,measure

BO_ 1602 msg_13118: 8 ecu_sec3_1
 SG_ signal13123 : 0|16@1+ (2E-008,0) [0|0] ""  ecu_pri1_1,measure
 SG_ signal13134 : 16|16@1+ (2E-008,0) [0|0] ""  ecu_pri1_1,measure
 SG_ signal13145 : 32|6@1+ (1,0) [0|63] "month"  ecu_pri1_1,measure
 SG_ signal13156 : 40|6@1+ (1,0) [0|63] "month"  ecu_pri1_1,measure
 SG_ signal13167 : 48|7@1+ (1000,0) [0|127000] "km"  ecu_pri1_1,measure
 SG_ signal13178 : 56|7@1+ (1000,0) [0|127000] "km"  ecu_pri1_1,measure

BO_TX_BU_ 135 : ecu_sec3_1,unused_1,unused_4;
BO_TX_BU_ 1601 : ecu_sec3_1,unused_1,unused_4;
BO_TX_BU_ 1730 : ecu_sec1_2,unused_8,unused_2;
BO_TX_BU_ 1729 : ecu_sec3_1,unused_1,unused_4;
BO_TX_BU_ 913 : ecu_sec3_1,unused_1,unused_4;
BO_TX_BU_ 768 : ecu_pri3_2,ecu_pri3_3,unused_6;
BO_TX_BU_ 769 : ecu_pri3_2,ecu_pri3_3,unused_6;
BO_TX_BU_ 770 : ecu_pri3_2,ecu_pri3_3,unused_6;
BO_TX_BU_ 771 : ecu_pri3_2,ecu_pri3_3,unused_6;
BO_TX_BU_ 772 : ecu_pri3_2,ecu_pri3_3,unused_6;
BO_TX_BU_ 773 : ecu_pri3_2,ecu_pri3_3,unused_6;
BO_TX_BU_ 774 : ecu_pri3_2,ecu_pri3_3,unused_6;
BO_TX_BU_ 775 : ecu_pri3_2,ecu_pri3_3,unused_6;
BO_TX_BU_ 912 : ecu_sec1_2,unused_8,unused_2,ecu_sec3_1,unused_1,unused_4;
BO_TX_BU_ 1602 : ecu_sec3_1,unused_1,unused_4;
BA_DEF_ BO_  "GenMsgAutoGenDsp" ENUM  "No","Yes";
BA_DEF_ BO_  "GenMsgAutoGenSnd" ENUM  "No","Yes";
BA_DEF_ BO_  "GenMsgCycleTime" INT 0 65535;
BA_DEF_ BO_  "GenMsgCycleTimeFast" INT 0 65535;
BA_DEF_ BO_  "GenMsgDelayTime" INT 0 100000;
BA_DEF_ BO_  "GenMsgILSupport" ENUM  "No","Yes";
BA_DEF_ BO_  "GenMsgNrOfRepetition" INT 0 100;
BA_DEF_ BO_  "GenMsgSendType" ENUM  "cyclicX","spontanX","cyclicIfActiveX","spontanWithDelay","cyclicAndSpontanX","cyclicAndSpontanWithDelay","spontanWithRepetition","cyclicIfActiveAndSpontanWD","cyclicIfActiveFast","cyclicWithRepeatOnDemand";
BA_DEF_ BO_  "GenMsgStartDelayTime" INT 0 100000;
BA_DEF_ BO_  "NmMessage" ENUM  "No","Yes";
BA_DEF_ BO_  "NmhMessage" ENUM  "No","Yes";
BA_DEF_ BO_  "NWM-Botschaft" ENUM  "No","Yes";
BA_DEF_ BO_  "signal24915" HEX 0 255;
BA_DEF_ BO_  "signal24909" ENUM  "No","Yes";
BA_DEF_ BO_  "signal24903" ENUM  "No","Yes";
BA_DEF_ BO_  "signal24897" ENUM  "No","Yes";
BA_DEF_ BO_  "Timeoutzeit" INT 0 1000000;
BA_DEF_ BO_  "signal24891" ENUM  "No","Yes";
BA_DEF_ SG_  "GenSigAltSetting" STRING ;
BA_DEF_ SG_  "GenSigAssignSetting" STRING ;
BA_DEF_ SG_  "GenSigAutoGenDsp" ENUM  "No","Yes";
BA_DEF_ SG_  "GenSigAutoGenSnd" ENUM  "No","Yes";
BA_DEF_ SG_  "GenSigConditionalSend" STRING ;
BA_DEF_ SG_  "GenSigEnvVarType" ENUM  "int","float","undef";
BA_DEF_ SG_  "GenSigEVName" STRING ;
BA_DEF_ SG_  "GenSigInactiveValue" INT -2147483648 2147483647;
BA_DEF_ SG_  "GenSigPostIfSetting" STRING ;
BA_DEF_ SG_  "GenSigPostSetting" STRING ;
BA_DEF_ SG_  "GenSigPreIfSetting" STRING ;
BA_DEF_ SG_  "GenSigPreSetting" STRING ;
BA_DEF_ SG_  "GenSigSendType" ENUM  "Cyclic","OnWrite","OnWriteWithRepetition","OnChange","OnChangeWithRepetition","IfActive","IfActiveWithRepetition","NoSigSendType";
BA_DEF_ SG_  "GenSigStartValue" INT -2147483648 2147483647;
BA_DEF_ SG_  "NWM-WakeupAllowed" ENUM  "No","Yes";
BA_DEF_ SG_  "NMH-WakeupAllowed" ENUM  "No","Yes";
BA_DEF_ SG_  "GenSigTimeoutMsg_ecu12594" HEX 0 2047;
BA_DEF_ SG_  "GenSigTimeoutMsg_ecu13120" HEX 0 2047;
BA_DEF_ SG_  "signal133356" HEX 0 2047;
BA_DEF_ SG_  "signal136198" HEX 0 2047;
BA_DEF_ SG_  "signal131977" HEX 0 2047;
BA_DEF_ SG_  "signal131970" HEX 0 2047;
BA_DEF_ SG_  "GenSigTimeoutMsg_ecu11765" HEX 0 2047;
BA_DEF_ SG_  "GenSigTimeoutMsg_ecu13186" HEX 0 2047;
BA_DEF_ SG_  "GenSigTimeoutMsg_ecu12990" HEX 0 2047;
BA_DEF_ SG_  "GenSigTimeoutMsg_ecu8948" HEX 0 2047;
BA_DEF_ SG_  "signal142820" HEX 0 2047;
BA_DEF_ SG_  "signal142834" HEX 0 2047;
BA_DEF_ SG_  "signal142827" HEX 0 2047;
BA_DEF_ SG_  "GenSigTimeoutMsg_ecu5385" HEX 0 2047;
BA_DEF_ SG_  "GenSigTimeoutMsg_ecu9211" HEX 0 2047;
BA_DEF_ SG_  "GenSigTimeoutMsg_ecu11949" HEX 0 2047;
BA_DEF_DEF_  "GenMsgAutoGenDsp" "Yes";
BA_DEF_DEF_  "GenMsgAutoGenSnd" "Yes";
BA_DEF_DEF_  "GenMsgCycleTime" 0;
BA_DEF_DEF_  "GenMsgCycleTimeFast" 0;
BA_DEF_DEF_  "GenMsgDelayTime" 0;
BA_DEF_DEF_  "GenMsgILSupport" "";
BA_DEF_DEF_  "GenMsgNrOfRepetition" 0;
BA_DEF_DEF_  "GenMsgSendType" "cyclicX";
BA_DEF_DEF_  "GenMsgStartDelayTime" 0;
BA_DEF_DEF_  "NmMessage" "No";
BA_DEF_DEF_  "NmhMessage" "No";
BA_DEF_DEF_  "NWM-Botschaft" "No";
BA_DEF_DEF_  "signal24915" 0;
BA_DEF_DEF_  "signal24909" "No";
BA_DEF_DEF_  "signal24903" "No";
BA_DEF_DEF_  "signal24897" "No";
BA_DEF_DEF_  "Timeoutzeit" 0;
BA_DEF_DEF_  "signal24891" "";
BA_DEF_DEF_  "GenSigAltSetting" "";
BA_DEF_DEF_  "GenSigAssignSetting" "";
BA_DEF_DEF_  "GenSigAutoGenDsp" "";
BA_DEF_DEF_  "GenSigAutoGenSnd" "";
BA_DEF_DEF_  "GenSigConditionalSend" "";
BA_DEF_DEF_  "GenSigEnvVarType" "undef";
BA_DEF_DEF_  "GenSigEVName" "";
BA_DEF_DEF_  "GenSigInactiveValue" 0;
BA_DEF_DEF_  "GenSigPostIfSetting" "";
BA_DEF_DEF_  "GenSigPostSetting" "";
BA_DEF_DEF_  "GenSigPreIfSetting" "";
BA_DEF_DEF_  "GenSigPreSetting" "";
BA_DEF_DEF_  "GenSigSendType" "Cyclic";
BA_DEF_DEF_  "GenSigStartValue" 0;
BA_DEF_DEF_  "NWM-WakeupAllowed" "";
BA_DEF_DEF_  "NMH-WakeupAllowed" "";
BA_DEF_DEF_  "GenSigTimeoutMsg_ecu12594" 0;
BA_DEF_DEF_  "GenSigTimeoutMsg_ecu13120" 0;
BA_DEF_DEF_  "signal133356" 0;
BA_DEF_DEF_  "signal136198" 0;
BA_DEF_DEF_  "signal131977" 0;
BA_DEF_DEF_  "signal131970" 0;
BA_DEF_DEF_  "GenSigTimeoutMsg_ecu11765" 0;
BA_DEF_DEF_  "GenSigTimeoutMsg_ecu13186" 0;
BA_DEF_DEF_  "GenSigTimeoutMsg_ecu12990" 0;
BA_DEF_DEF_  "GenSigTimeoutMsg_ecu8948" 0;
BA_DEF_DEF_  "signal142820" 0;
BA_DEF_DEF_  "signal142834" 0;
BA_DEF_DEF_  "signal142827" 0;
BA_DEF_DEF_  "GenSigTimeoutMsg_ecu5385" 0;
BA_DEF_DEF_  "GenSigTimeoutMsg_ecu9211" 0;
BA_DEF_DEF_  "GenSigTimeoutMsg_ecu11949" 0;
BA_ "signal24891" BO_ 135 1;
BA_ "GenMsgILSupport" BO_ 135 1;
BA_ "GenMsgCycleTime" BO_ 135 10;
BA_ "signal24891" BO_ 1607 1;
BA_ "GenMsgILSupport" BO_ 1607 1;
BA_ "GenMsgCycleTime" BO_ 1607 500;
BA_ "signal24891" BO_ 1601 1;
BA_ "GenMsgILSupport" BO_ 1601 1;
BA_ "GenMsgCycleTime" BO_ 1601 1000;
BA_ "signal24891" BO_ 1090 1;
BA_ "GenMsgILSupport" BO_ 1090 1;
BA_ "GenMsgCycleTime" BO_ 1090 100;
BA_ "signal24891" BO_ 1753 1;
BA_ "NmhMessage" BO_ 1753 1;
BA_ "GenMsgILSupport" BO_ 1753 0;
BA_ "GenMsgCycleTime" BO_ 1753 100;
BA_ "signal24891" BO_ 1731 1;
BA_ "NmhMessage" BO_ 1731 1;
BA_ "GenMsgILSupport" BO_ 1731 0;
BA_ "GenMsgCycleTime" BO_ 1731 100;
BA_ "signal24891" BO_ 1728 1;
BA_ "NmhMessage" BO_ 1728 1;
BA_ "GenMsgILSupport" BO_ 1728 0;
BA_ "GenMsgCycleTime" BO_ 1728 100;
BA_ "signal24891" BO_ 1730 1;
BA_ "NmhMessage" BO_ 1730 1;
BA_ "GenMsgILSupport" BO_ 1730 0;
BA_ "GenMsgCycleTime" BO_ 1730 100;
BA_ "signal24891" BO_ 1729 1;
BA_ "NmhMessage" BO_ 1729 1;
BA_ "GenMsgILSupport" BO_ 1729 0;
BA_ "GenMsgCycleTime" BO_ 1729 100;
BA_ "signal24891" BO_ 1744 1;
BA_ "NmhMessage" BO_ 1744 1;
BA_ "GenMsgILSupport" BO_ 1744 0;
BA_ "GenMsgCycleTime" BO_ 1744 100;
BA_ "signal24891" BO_ 913 1;
BA_ "GenMsgILSupport" BO_ 913 1;
BA_ "GenMsgCycleTime" BO_ 913 100;
BA_ "signal24891" BO_ 1630 1;
BA_ "GenMsgILSupport" BO_ 1630 1;
BA_ "GenMsgCycleTime" BO_ 1630 500;
BA_ "signal24891" BO_ 929 1;
BA_ "GenMsgSendType" BO_ 929 5;
BA_ "GenMsgILSupport" BO_ 929 1;
BA_ "GenMsgDelayTime" BO_ 929 100;
BA_ "GenMsgCycleTime" BO_ 929 150;
BA_ "signal24891" BO_ 930 1;
BA_ "GenMsgSendType" BO_ 930 5;
BA_ "GenMsgILSupport" BO_ 930 1;
BA_ "GenMsgDelayTime" BO_ 930 100;
BA_ "GenMsgCycleTime" BO_ 930 150;
BA_ "signal24891" BO_ 2033 1;
BA_ "GenMsgSendType" BO_ 2033 1;
BA_ "GenMsgILSupport" BO_ 2033 0;
BA_ "GenMsgAutoGenSnd" BO_ 2033 0;
BA_ "GenMsgAutoGenDsp" BO_ 2033 0;
BA_ "signal24891" BO_ 2041 1;
BA_ "GenMsgSendType" BO_ 2041 1;
BA_ "GenMsgILSupport" BO_ 2041 0;
BA_ "GenMsgAutoGenSnd" BO_ 2041 0;
BA_ "GenMsgAutoGenDsp" BO_ 2041 0;
BA_ "signal24891" BO_ 133 0;
BA_ "Timeoutzeit" BO_ 133 500;
BA_ "GenMsgILSupport" BO_ 133 1;
BA_ "GenMsgCycleTime" BO_ 133 10;
BA_ "signal24891" BO_ 784 0;
BA_ "GenMsgILSupport" BO_ 784 1;
BA_ "GenMsgCycleTime" BO_ 784 50;
BA_ "signal24891" BO_ 1313 1;
BA_ "GenMsgILSupport" BO_ 1313 1;
BA_ "GenMsgDelayTime" BO_ 1313 50;
BA_ "GenMsgCycleTime" BO_ 1313 200;
BA_ "signal24891" BO_ 1650 1;
BA_ "GenMsgILSupport" BO_ 1650 1;
BA_ "GenMsgCycleTime" BO_ 1650 500;
BA_ "signal24891" BO_ 1413 1;
BA_ "GenMsgSendType" BO_ 1413 5;
BA_ "GenMsgILSupport" BO_ 1413 1;
BA_ "GenMsgCycleTime" BO_ 1413 1000;
BA_ "signal24891" BO_ 1209 1;
BA_ "signal24909" BO_ 1209 1;
BA_ "GenMsgSendType" BO_ 1209 1;
BA_ "GenMsgILSupport" BO_ 1209 0;
BA_ "GenMsgCycleTime" BO_ 1209 1;
BA_ "GenMsgAutoGenSnd" BO_ 1209 0;
BA_ "GenMsgAutoGenDsp" BO_ 1209 0;
BA_ "signal24891" BO_ 1215 1;
BA_ "signal24909" BO_ 1215 1;
BA_ "GenMsgSendType" BO_ 1215 1;
BA_ "GenMsgILSupport" BO_ 1215 0;
BA_ "GenMsgCycleTime" BO_ 1215 1;
BA_ "GenMsgAutoGenSnd" BO_ 1215 0;
BA_ "GenMsgAutoGenDsp" BO_ 1215 0;
BA_ "signal24891" BO_ 1303 1;
BA_ "signal24909" BO_ 1303 1;
BA_ "GenMsgSendType" BO_ 1303 1;
BA_ "GenMsgILSupport" BO_ 1303 0;
BA_ "GenMsgCycleTime" BO_ 1303 1;
BA_ "GenMsgAutoGenSnd" BO_ 1303 0;
BA_ "GenMsgAutoGenDsp" BO_ 1303 0;
BA_ "signal24891" BO_ 1214 1;
BA_ "signal24909" BO_ 1214 1;
BA_ "GenMsgSendType" BO_ 1214 1;
BA_ "GenMsgILSupport" BO_ 1214 0;
BA_ "GenMsgCycleTime" BO_ 1214 1;
BA_ "GenMsgAutoGenSnd" BO_ 1214 0;
BA_ "GenMsgAutoGenDsp" BO_ 1214 0;
BA_ "signal24891" BO_ 1231 1;
BA_ "signal24909" BO_ 1231 1;
BA_ "GenMsgSendType" BO_ 1231 1;
BA_ "GenMsgILSupport" BO_ 1231 0;
BA_ "GenMsgCycleTime" BO_ 1231 1;
BA_ "GenMsgAutoGenSnd" BO_ 1231 0;
BA_ "GenMsgAutoGenDsp" BO_ 1231 0;
BA_ "signal24891" BO_ 768 1;
BA_ "signal24909" BO_ 768 1;
BA_ "GenMsgSendType" BO_ 768 1;
BA_ "GenMsgILSupport" BO_ 768 0;
BA_ "GenMsgCycleTime" BO_ 768 1;
BA_ "GenMsgAutoGenSnd" BO_ 768 0;
BA_ "GenMsgAutoGenDsp" BO_ 768 0;
BA_ "signal24891" BO_ 769 1;
BA_ "signal24909" BO_ 769 1;
BA_ "GenMsgSendType" BO_ 769 1;
BA_ "GenMsgILSupport" BO_ 769 0;
BA_ "GenMsgCycleTime" BO_ 769 1;
BA_ "GenMsgAutoGenSnd" BO_ 769 0;
BA_ "GenMsgAutoGenDsp" BO_ 769 0;
BA_ "signal24891" BO_ 770 1;
BA_ "signal24909" BO_ 770 1;
BA_ "GenMsgSendType" BO_ 770 1;
BA_ "GenMsgILSupport" BO_ 770 0;
BA_ "GenMsgCycleTime" BO_ 770 1;
BA_ "GenMsgAutoGenSnd" BO_ 770 0;
BA_ "GenMsgAutoGenDsp" BO_ 770 0;
BA_ "signal24891" BO_ 771 1;
BA_ "signal24909" BO_ 771 1;
BA_ "GenMsgSendType" BO_ 771 1;
BA_ "GenMsgILSupport" BO_ 771 0;
BA_ "GenMsgCycleTime" BO_ 771 1;
BA_ "GenMsgAutoGenSnd" BO_ 771 0;
BA_ "GenMsgAutoGenDsp" BO_ 771 0;
BA_ "signal24891" BO_ 772 1;
BA_ "signal24909" BO_ 772 1;
BA_ "GenMsgSendType" BO_ 772 1;
BA_ "GenMsgILSupport" BO_ 772 0;
BA_ "GenMsgCycleTime" BO_ 772 1;
BA_ "GenMsgAutoGenSnd" BO_ 772 0;
BA_ "GenMsgAutoGenDsp" BO_ 772 0;
BA_ "signal24891" BO_ 773 1;
BA_ "signal24909" BO_ 773 1;
BA_ "GenMsgSendType" BO_ 773 1;
BA_ "GenMsgILSupport" BO_ 773 0;
BA_ "GenMsgCycleTime" BO_ 773 1;
BA_ "GenMsgAutoGenSnd" BO_ 773 0;
BA_ "GenMsgAutoGenDsp" BO_ 773 0;
BA_ "signal24891" BO_ 774 1;
BA_ "signal24909" BO_ 774 1;
BA_ "GenMsgSendType" BO_ 774 1;
BA_ "GenMsgILSupport" BO_ 774 0;
BA_ "GenMsgCycleTime" BO_ 774 1;
BA_ "GenMsgAutoGenSnd" BO_ 774 0;
BA_ "GenMsgAutoGenDsp" BO_ 774 0;
BA_ "signal24891" BO_ 775 1;
BA_ "signal24909" BO_ 775 1;
BA_ "GenMsgSendType" BO_ 775 1;
BA_ "GenMsgILSupport" BO_ 775 0;
BA_ "GenMsgCycleTime" BO_ 775 1;
BA_ "GenMsgAutoGenSnd" BO_ 775 0;
BA_ "GenMsgAutoGenDsp" BO_ 775 0;
BA_ "signal24891" BO_ 537 1;
BA_ "signal24903" BO_ 537 1;
BA_ "GenMsgSendType" BO_ 537 1;
BA_ "GenMsgILSupport" BO_ 537 0;
BA_ "GenMsgAutoGenSnd" BO_ 537 0;
BA_ "GenMsgAutoGenDsp" BO_ 537 0;
BA_ "signal24891" BO_ 543 1;
BA_ "signal24903" BO_ 543 1;
BA_ "GenMsgSendType" BO_ 543 1;
BA_ "GenMsgILSupport" BO_ 543 0;
BA_ "GenMsgAutoGenSnd" BO_ 543 0;
BA_ "GenMsgAutoGenDsp" BO_ 543 0;
BA_ "signal24891" BO_ 542 1;
BA_ "signal24903" BO_ 542 1;
BA_ "GenMsgSendType" BO_ 542 1;
BA_ "GenMsgILSupport" BO_ 542 0;
BA_ "GenMsgAutoGenSnd" BO_ 542 0;
BA_ "GenMsgAutoGenDsp" BO_ 542 0;
BA_ "signal24891" BO_ 559 1;
BA_ "signal24903" BO_ 559 1;
BA_ "GenMsgSendType" BO_ 559 1;
BA_ "GenMsgILSupport" BO_ 559 0;
BA_ "GenMsgAutoGenSnd" BO_ 559 0;
BA_ "GenMsgAutoGenDsp" BO_ 559 0;
BA_ "signal24891" BO_ 512 1;
BA_ "signal24903" BO_ 512 1;
BA_ "GenMsgSendType" BO_ 512 1;
BA_ "GenMsgILSupport" BO_ 512 0;
BA_ "GenMsgAutoGenSnd" BO_ 512 0;
BA_ "GenMsgAutoGenDsp" BO_ 512 0;
BA_ "signal24891" BO_ 1716 1;
BA_ "GenMsgILSupport" BO_ 1716 1;
BA_ "GenMsgCycleTime" BO_ 1716 1000;
BA_ "signal24891" BO_ 912 1;
BA_ "GenMsgSendType" BO_ 912 5;
BA_ "GenMsgILSupport" BO_ 912 1;
BA_ "GenMsgDelayTime" BO_ 912 10;
BA_ "GenMsgCycleTime" BO_ 912 100;
BA_ "signal24891" BO_ 1602 1;
BA_ "GenMsgSendType" BO_ 1602 5;
BA_ "GenMsgILSupport" BO_ 1602 1;
BA_ "GenMsgCycleTime" BO_ 1602 2000;
BA_ "GenSigTimeoutMsg_ecu11765" SG_ 135 signal8602_CHK 135;
BA_ "signal131970" SG_ 135 signal8602_CHK 135;
BA_ "signal131977" SG_ 135 signal8602_CHK 135;
BA_ "NMH-WakeupAllowed" SG_ 135 signal8602_CHK 0;
BA_ "NWM-WakeupAllowed" SG_ 135 signal8602_CHK 0;
BA_ "GenSigSendType" SG_ 135 signal8602_CHK 7;
BA_ "GenSigEnvVarType" SG_ 135 signal8602_CHK 0;
BA_ "GenSigAutoGenSnd" SG_ 135 signal8602_CHK 1;
BA_ "GenSigAutoGenDsp" SG_ 135 signal8602_CHK 1;
BA_ "GenSigTimeoutMsg_ecu11765" SG_ 135 signal8620 135;
BA_ "signal131970" SG_ 135 signal8620 135;
BA_ "signal131977" SG_ 135 signal8620 135;
BA_ "NMH-WakeupAllowed" SG_ 135 signal8620 0;
BA_ "NWM-WakeupAllowed" SG_ 135 signal8620 0;
BA_ "GenSigSendType" SG_ 135 signal8620 7;
BA_ "GenSigEnvVarType" SG_ 135 signal8620 0;
BA_ "GenSigAutoGenSnd" SG_ 135 signal8620 1;
BA_ "GenSigAutoGenDsp" SG_ 135 signal8620 1;
BA_ "GenSigTimeoutMsg_ecu11765" SG_ 135 signal8633 135;
BA_ "signal131970" SG_ 135 signal8633 135;
BA_ "signal131977" SG_ 135 signal8633 135;
BA_ "NMH-WakeupAllowed" SG_ 135 signal8633 0;
BA_ "NWM-WakeupAllowed" SG_ 135 signal8633 0;
BA_ "GenSigStartValue" SG_ 135 signal8633 1;
BA_ "GenSigSendType" SG_ 135 signal8633 7;
BA_ "GenSigEnvVarType" SG_ 135 signal8633 0;
BA_ "GenSigAutoGenSnd" SG_ 135 signal8633 1;
BA_ "GenSigAutoGenDsp" SG_ 135 signal8633 1;
BA_ "GenSigTimeoutMsg_ecu11765" SG_ 135 signal8646 135;
BA_ "signal131970" SG_ 135 signal8646 135;
BA_ "signal131977" SG_ 135 signal8646 135;
BA_ "NMH-WakeupAllowed" SG_ 135 signal8646 0;
BA_ "NWM-WakeupAllowed" SG_ 135 signal8646 0;
BA_ "GenSigStartValue" SG_ 135 signal8646 1;
BA_ "GenSigSendType" SG_ 135 signal8646 7;
BA_ "GenSigEnvVarType" SG_ 135 signal8646 0;
BA_ "GenSigAutoGenSnd" SG_ 135 signal8646 1;
BA_ "GenSigAutoGenDsp" SG_ 135 signal8646 1;
BA_ "GenSigTimeoutMsg_ecu11765" SG_ 135 signal8659 135;
BA_ "signal131970" SG_ 135 signal8659 135;
BA_ "signal131977" SG_ 135 signal8659 135;
BA_ "NMH-WakeupAllowed" SG_ 135 signal8659 0;
BA_ "NWM-WakeupAllowed" SG_ 135 signal8659 0;
BA_ "GenSigSendType" SG_ 135 signal8659 7;
BA_ "GenSigEnvVarType" SG_ 135 signal8659 0;
BA_ "GenSigAutoGenSnd" SG_ 135 signal8659 1;
BA_ "GenSigAutoGenDsp" SG_ 135 signal8659 1;
BA_ "GenSigTimeoutMsg_ecu11765" SG_ 135 signal8672 135;
BA_ "signal131970" SG_ 135 signal8672 135;
BA_ "signal131977" SG_ 135 signal8672 135;
BA_ "NMH-WakeupAllowed" SG_ 135 signal8672 0;
BA_ "NWM-WakeupAllowed" SG_ 135 signal8672 0;
BA_ "GenSigSendType" SG_ 135 signal8672 7;
BA_ "GenSigEnvVarType" SG_ 135 signal8672 1;
BA_ "GenSigAutoGenSnd" SG_ 135 signal8672 1;
BA_ "GenSigAutoGenDsp" SG_ 135 signal8672 1;
BA_ "GenSigTimeoutMsg_ecu11765" SG_ 135 signal8685 135;
BA_ "signal131970" SG_ 135 signal8685 135;
BA_ "signal131977" SG_ 135 signal8685 135;
BA_ "NMH-WakeupAllowed" SG_ 135 signal8685 0;
BA_ "NWM-WakeupAllowed" SG_ 135 signal8685 0;
BA_ "GenSigSendType" SG_ 135 signal8685 7;
BA_ "GenSigEnvVarType" SG_ 135 signal8685 1;
BA_ "GenSigAutoGenSnd" SG_ 135 signal8685 1;
BA_ "GenSigAutoGenDsp" SG_ 135 signal8685 1;
BA_ "GenSigTimeoutMsg_ecu13186" SG_ 1607 signal8715 1607;
BA_ "NMH-WakeupAllowed" SG_ 1607 signal8715 0;
BA_ "NWM-WakeupAllowed" SG_ 1607 signal8715 0;
BA_ "GenSigStartValue" SG_ 1607 signal8715 32767;
BA_ "GenSigSendType" SG_ 1607 signal8715 7;
BA_ "GenSigEVName" SG_ 1607 signal8715 "@signame";
BA_ "GenSigAutoGenSnd" SG_ 1607 signal8715 1;
BA_ "GenSigAutoGenDsp" SG_ 1607 signal8715 1;
BA_ "GenSigTimeoutMsg_ecu13186" SG_ 1607 signal8726 1607;
BA_ "NMH-WakeupAllowed" SG_ 1607 signal8726 0;
BA_ "NWM-WakeupAllowed" SG_ 1607 signal8726 0;
BA_ "GenSigSendType" SG_ 1607 signal8726 7;
BA_ "GenSigEVName" SG_ 1607 signal8726 "@signame";
BA_ "GenSigAutoGenSnd" SG_ 1607 signal8726 1;
BA_ "GenSigAutoGenDsp" SG_ 1607 signal8726 1;
BA_ "GenSigTimeoutMsg_ecu13186" SG_ 1607 signal8737 1607;
BA_ "NMH-WakeupAllowed" SG_ 1607 signal8737 0;
BA_ "NWM-WakeupAllowed" SG_ 1607 signal8737 0;
BA_ "GenSigSendType" SG_ 1607 signal8737 7;
BA_ "GenSigEVName" SG_ 1607 signal8737 "@signame";
BA_ "GenSigAutoGenSnd" SG_ 1607 signal8737 1;
BA_ "GenSigAutoGenDsp" SG_ 1607 signal8737 1;
BA_ "GenSigTimeoutMsg_ecu13186" SG_ 1607 signal8748 1607;
BA_ "NMH-WakeupAllowed" SG_ 1607 signal8748 0;
BA_ "NWM-WakeupAllowed" SG_ 1607 signal8748 0;
BA_ "GenSigSendType" SG_ 1607 signal8748 7;
BA_ "GenSigEVName" SG_ 1607 signal8748 "@signame";
BA_ "GenSigAutoGenSnd" SG_ 1607 signal8748 1;
BA_ "GenSigAutoGenDsp" SG_ 1607 signal8748 1;
BA_ "GenSigTimeoutMsg_ecu13186" SG_ 1607 signal8759 1607;
BA_ "NMH-WakeupAllowed" SG_ 1607 signal8759 0;
BA_ "NWM-WakeupAllowed" SG_ 1607 signal8759 0;
BA_ "GenSigSendType" SG_ 1607 signal8759 7;
BA_ "GenSigEVName" SG_ 1607 signal8759 "@signame";
BA_ "GenSigAutoGenSnd" SG_ 1607 signal8759 1;
BA_ "GenSigAutoGenDsp" SG_ 1607 signal8759 1;
BA_ "GenSigTimeoutMsg_ecu13186" SG_ 1607 signal8770 1607;
BA_ "NMH-WakeupAllowed" SG_ 1607 signal8770 0;
BA_ "NWM-WakeupAllowed" SG_ 1607 signal8770 0;
BA_ "GenSigSendType" SG_ 1607 signal8770 7;
BA_ "GenSigEVName" SG_ 1607 signal8770 "@signame";
BA_ "GenSigAutoGenSnd" SG_ 1607 signal8770 1;
BA_ "GenSigAutoGenDsp" SG_ 1607 signal8770 1;
BA_ "GenSigTimeoutMsg_ecu11765" SG_ 1601 signal8782_CHK 1601;
BA_ "signal131970" SG_ 1601 signal8782_CHK 1601;
BA_ "signal131977" SG_ 1601 signal8782_CHK 1601;
BA_ "GenSigTimeoutMsg_ecu13186" SG_ 1601 signal8782_CHK 1601;
BA_ "NMH-WakeupAllowed" SG_ 1601 signal8782_CHK 0;
BA_ "NWM-WakeupAllowed" SG_ 1601 signal8782_CHK 0;
BA_ "GenSigSendType" SG_ 1601 signal8782_CHK 7;
BA_ "GenSigEnvVarType" SG_ 1601 signal8782_CHK 0;
BA_ "GenSigAutoGenSnd" SG_ 1601 signal8782_CHK 1;
BA_ "GenSigAutoGenDsp" SG_ 1601 signal8782_CHK 1;
BA_ "GenSigTimeoutMsg_ecu11765" SG_ 1601 signal8782_BZ 1601;
BA_ "signal131970" SG_ 1601 signal8782_BZ 1601;
BA_ "signal131977" SG_ 1601 signal8782_BZ 1601;
BA_ "GenSigTimeoutMsg_ecu13186" SG_ 1601 signal8782_BZ 1601;
BA_ "NMH-WakeupAllowed" SG_ 1601 signal8782_BZ 0;
BA_ "NWM-WakeupAllowed" SG_ 1601 signal8782_BZ 0;
BA_ "GenSigSendType" SG_ 1601 signal8782_BZ 7;
BA_ "GenSigEnvVarType" SG_ 1601 signal8782_BZ 0;
BA_ "GenSigAutoGenSnd" SG_ 1601 signal8782_BZ 1;
BA_ "GenSigAutoGenDsp" SG_ 1601 signal8782_BZ 1;
BA_ "GenSigTimeoutMsg_ecu11765" SG_ 1601 signal8815 1601;
BA_ "signal131970" SG_ 1601 signal8815 1601;
BA_ "signal131977" SG_ 1601 signal8815 1601;
BA_ "GenSigTimeoutMsg_ecu13186" SG_ 1601 signal8815 1601;
BA_ "GenSigTimeoutMsg_ecu12594" SG_ 1601 signal8815 1601;
BA_ "NMH-WakeupAllowed" SG_ 1601 signal8815 0;
BA_ "NWM-WakeupAllowed" SG_ 1601 signal8815 0;
BA_ "GenSigSendType" SG_ 1601 signal8815 7;
BA_ "GenSigEnvVarType" SG_ 1601 signal8815 0;
BA_ "GenSigAutoGenSnd" SG_ 1601 signal8815 1;
BA_ "GenSigAutoGenDsp" SG_ 1601 signal8815 1;
BA_ "GenSigTimeoutMsg_ecu11765" SG_ 1601 signal8830 1601;
BA_ "signal131970" SG_ 1601 signal8830 1601;
BA_ "signal131977" SG_ 1601 signal8830 1601;
BA_ "GenSigTimeoutMsg_ecu13186" SG_ 1601 signal8830 1601;
BA_ "GenSigTimeoutMsg_ecu12594" SG_ 1601 signal8830 1601;
BA_ "NMH-WakeupAllowed" SG_ 1601 signal8830 0;
BA_ "NWM-WakeupAllowed" SG_ 1601 signal8830 0;
BA_ "GenSigSendType" SG_ 1601 signal8830 7;
BA_ "GenSigEnvVarType" SG_ 1601 signal8830 0;
BA_ "GenSigAutoGenSnd" SG_ 1601 signal8830 1;
BA_ "GenSigAutoGenDsp" SG_ 1601 signal8830 1;
BA_ "GenSigTimeoutMsg_ecu11765" SG_ 1601 signal8845 1601;
BA_ "signal131970" SG_ 1601 signal8845 1601;
BA_ "signal131977" SG_ 1601 signal8845 1601;
BA_ "GenSigTimeoutMsg_ecu13186" SG_ 1601 signal8845 1601;
BA_ "GenSigTimeoutMsg_ecu12594" SG_ 1601 signal8845 1601;
BA_ "NMH-WakeupAllowed" SG_ 1601 signal8845 0;
BA_ "NWM-WakeupAllowed" SG_ 1601 signal8845 0;
BA_ "GenSigSendType" SG_ 1601 signal8845 7;
BA_ "GenSigEnvVarType" SG_ 1601 signal8845 0;
BA_ "GenSigAutoGenSnd" SG_ 1601 signal8845 1;
BA_ "GenSigAutoGenDsp" SG_ 1601 signal8845 1;
BA_ "GenSigTimeoutMsg_ecu13186" SG_ 1601 signal8860 1601;
BA_ "GenSigTimeoutMsg_ecu12594" SG_ 1601 signal8860 1601;
BA_ "NMH-WakeupAllowed" SG_ 1601 signal8860 0;
BA_ "NWM-WakeupAllowed" SG_ 1601 signal8860 0;
BA_ "GenSigSendType" SG_ 1601 signal8860 7;
BA_ "GenSigEnvVarType" SG_ 1601 signal8860 0;
BA_ "GenSigAutoGenSnd" SG_ 1601 signal8860 1;
BA_ "GenSigAutoGenDsp" SG_ 1601 signal8860 1;
BA_ "GenSigTimeoutMsg_ecu12990" SG_ 1601 signal8872 1601;
BA_ "GenSigTimeoutMsg_ecu13186" SG_ 1601 signal8872 1601;
BA_ "GenSigTimeoutMsg_ecu12594" SG_ 1601 signal8872 1601;
BA_ "NMH-WakeupAllowed" SG_ 1601 signal8872 0;
BA_ "NWM-WakeupAllowed" SG_ 1601 signal8872 0;
BA_ "GenSigSendType" SG_ 1601 signal8872 7;
BA_ "GenSigEnvVarType" SG_ 1601 signal8872 0;
BA_ "GenSigAutoGenSnd" SG_ 1601 signal8872 1;
BA_ "GenSigAutoGenDsp" SG_ 1601 signal8872 1;
BA_ "GenSigTimeoutMsg_ecu13186" SG_ 1601 signal8885 1601;
BA_ "GenSigTimeoutMsg_ecu12594" SG_ 1601 signal8885 1601;
BA_ "NMH-WakeupAllowed" SG_ 1601 signal8885 0;
BA_ "NWM-WakeupAllowed" SG_ 1601 signal8885 0;
BA_ "GenSigSendType" SG_ 1601 signal8885 7;
BA_ "GenSigEnvVarType" SG_ 1601 signal8885 1;
BA_ "GenSigAutoGenSnd" SG_ 1601 signal8885 1;
BA_ "GenSigAutoGenDsp" SG_ 1601 signal8885 1;
BA_ "GenSigTimeoutMsg_ecu13186" SG_ 1601 signal8897 1601;
BA_ "GenSigTimeoutMsg_ecu12594" SG_ 1601 signal8897 1601;
BA_ "NMH-WakeupAllowed" SG_ 1601 signal8897 0;
BA_ "NWM-WakeupAllowed" SG_ 1601 signal8897 0;
BA_ "GenSigSendType" SG_ 1601 signal8897 7;
BA_ "GenSigEnvVarType" SG_ 1601 signal8897 0;
BA_ "GenSigAutoGenSnd" SG_ 1601 signal8897 1;
BA_ "GenSigAutoGenDsp" SG_ 1601 signal8897 1;
BA_ "GenSigTimeoutMsg_ecu13186" SG_ 1601 signal8909 1601;
BA_ "GenSigTimeoutMsg_ecu12594" SG_ 1601 signal8909 1601;
BA_ "NMH-WakeupAllowed" SG_ 1601 signal8909 0;
BA_ "NWM-WakeupAllowed" SG_ 1601 signal8909 0;
BA_ "GenSigSendType" SG_ 1601 signal8909 7;
BA_ "GenSigEnvVarType" SG_ 1601 signal8909 0;
BA_ "GenSigAutoGenSnd" SG_ 1601 signal8909 1;
BA_ "GenSigAutoGenDsp" SG_ 1601 signal8909 1;
BA_ "signal131970" SG_ 1601 signal8921 1601;
BA_ "signal131977" SG_ 1601 signal8921 1601;
BA_ "GenSigTimeoutMsg_ecu13186" SG_ 1601 signal8921 1601;
BA_ "NMH-WakeupAllowed" SG_ 1601 signal8921 0;
BA_ "NWM-WakeupAllowed" SG_ 1601 signal8921 0;
BA_ "GenSigSendType" SG_ 1601 signal8921 7;
BA_ "GenSigEnvVarType" SG_ 1601 signal8921 0;
BA_ "GenSigAutoGenSnd" SG_ 1601 signal8921 1;
BA_ "GenSigAutoGenDsp" SG_ 1601 signal8921 1;
BA_ "GenSigTimeoutMsg_ecu13186" SG_ 1601 signal8934 1601;
BA_ "NMH-WakeupAllowed" SG_ 1601 signal8934 0;
BA_ "NWM-WakeupAllowed" SG_ 1601 signal8934 0;
BA_ "GenSigSendType" SG_ 1601 signal8934 7;
BA_ "GenSigEnvVarType" SG_ 1601 signal8934 0;
BA_ "GenSigAutoGenSnd" SG_ 1601 signal8934 1;
BA_ "GenSigAutoGenDsp" SG_ 1601 signal8934 1;
BA_ "GenSigTimeoutMsg_ecu13186" SG_ 1090 signal8951 1090;
BA_ "NMH-WakeupAllowed" SG_ 1090 signal8951 0;
BA_ "NWM-WakeupAllowed" SG_ 1090 signal8951 0;
BA_ "GenSigSendType" SG_ 1090 signal8951 7;
BA_ "GenSigEnvVarType" SG_ 1090 signal8951 0;
BA_ "GenSigAutoGenSnd" SG_ 1090 signal8951 1;
BA_ "GenSigAutoGenDsp" SG_ 1090 signal8951 1;
BA_ "NMH-WakeupAllowed" SG_ 1753 signal9108 0;
BA_ "NWM-WakeupAllowed" SG_ 1753 signal9108 0;
BA_ "GenSigSendType" SG_ 1753 signal9108 7;
BA_ "GenSigEnvVarType" SG_ 1753 signal9108 0;
BA_ "GenSigAutoGenSnd" SG_ 1753 signal9108 0;
BA_ "GenSigAutoGenDsp" SG_ 1753 signal9108 0;
BA_ "NMH-WakeupAllowed" SG_ 1753 signal9168 0;
BA_ "NWM-WakeupAllowed" SG_ 1753 signal9168 0;
BA_ "GenSigSendType" SG_ 1753 signal9168 7;
BA_ "GenSigEnvVarType" SG_ 1753 signal9168 0;
BA_ "GenSigAutoGenSnd" SG_ 1753 signal9168 0;
BA_ "GenSigAutoGenDsp" SG_ 1753 signal9168 0;
BA_ "GenSigTimeoutMsg_ecu12990" SG_ 1731 signal9214 1731;
BA_ "signal136198" SG_ 1731 signal9214 1731;
BA_ "signal133356" SG_ 1731 signal9214 1731;
BA_ "GenSigTimeoutMsg_ecu13120" SG_ 1731 signal9214 1731;
BA_ "GenSigTimeoutMsg_ecu11765" SG_ 1731 signal9214 1731;
BA_ "signal131970" SG_ 1731 signal9214 1731;
BA_ "signal131977" SG_ 1731 signal9214 1731;
BA_ "GenSigTimeoutMsg_ecu13186" SG_ 1731 signal9214 1731;
BA_ "GenSigTimeoutMsg_ecu9211" SG_ 1731 signal9214 1731;
BA_ "GenSigTimeoutMsg_ecu12594" SG_ 1731 signal9214 1731;
BA_ "NMH-WakeupAllowed" SG_ 1731 signal9214 0;
BA_ "NWM-WakeupAllowed" SG_ 1731 signal9214 0;
BA_ "GenSigStartValue" SG_ 1731 signal9214 1;
BA_ "GenSigSendType" SG_ 1731 signal9214 7;
BA_ "GenSigEnvVarType" SG_ 1731 signal9214 0;
BA_ "GenSigAutoGenSnd" SG_ 1731 signal9214 0;
BA_ "GenSigAutoGenDsp" SG_ 1731 signal9214 0;
BA_ "NMH-WakeupAllowed" SG_ 1731 signal9234 0;
BA_ "NWM-WakeupAllowed" SG_ 1731 signal9234 0;
BA_ "GenSigSendType" SG_ 1731 signal9234 7;
BA_ "GenSigEnvVarType" SG_ 1731 signal9234 0;
BA_ "GenSigAutoGenSnd" SG_ 1731 signal9234 0;
BA_ "GenSigAutoGenDsp" SG_ 1731 signal9234 0;
BA_ "NMH-WakeupAllowed" SG_ 1731 signal9274 0;
BA_ "NWM-WakeupAllowed" SG_ 1731 signal9274 1;
BA_ "GenSigSendType" SG_ 1731 signal9274 7;
BA_ "GenSigEnvVarType" SG_ 1731 signal9274 0;
BA_ "GenSigAutoGenSnd" SG_ 1731 signal9274 0;
BA_ "GenSigAutoGenDsp" SG_ 1731 signal9274 0;
BA_ "NMH-WakeupAllowed" SG_ 1731 signal9294 0;
BA_ "NWM-WakeupAllowed" SG_ 1731 signal9294 0;
BA_ "GenSigSendType" SG_ 1731 signal9294 7;
BA_ "GenSigEnvVarType" SG_ 1731 signal9294 0;
BA_ "GenSigAutoGenSnd" SG_ 1731 signal9294 0;
BA_ "GenSigAutoGenDsp" SG_ 1731 signal9294 0;
BA_ "NMH-WakeupAllowed" SG_ 1731 signal9304 0;
BA_ "NWM-WakeupAllowed" SG_ 1731 signal9304 0;
BA_ "GenSigSendType" SG_ 1731 signal9304 7;
BA_ "GenSigEnvVarType" SG_ 1731 signal9304 0;
BA_ "GenSigAutoGenSnd" SG_ 1731 signal9304 0;
BA_ "GenSigAutoGenDsp" SG_ 1731 signal9304 0;
BA_ "NMH-WakeupAllowed" SG_ 1731 signal9314 0;
BA_ "NWM-WakeupAllowed" SG_ 1731 signal9314 0;
BA_ "GenSigSendType" SG_ 1731 signal9314 7;
BA_ "GenSigEnvVarType" SG_ 1731 signal9314 0;
BA_ "GenSigAutoGenSnd" SG_ 1731 signal9314 0;
BA_ "GenSigAutoGenDsp" SG_ 1731 signal9314 0;
BA_ "NMH-WakeupAllowed" SG_ 1731 signal9324 0;
BA_ "NWM-WakeupAllowed" SG_ 1731 signal9324 0;
BA_ "GenSigStartValue" SG_ 1731 signal9324 1;
BA_ "GenSigSendType" SG_ 1731 signal9324 7;
BA_ "GenSigEnvVarType" SG_ 1731 signal9324 0;
BA_ "GenSigAutoGenSnd" SG_ 1731 signal9324 0;
BA_ "GenSigAutoGenDsp" SG_ 1731 signal9324 0;
BA_ "NMH-WakeupAllowed" SG_ 1731 signal9334 0;
BA_ "NWM-WakeupAllowed" SG_ 1731 signal9334 0;
BA_ "GenSigSendType" SG_ 1731 signal9334 7;
BA_ "GenSigEnvVarType" SG_ 1731 signal9334 0;
BA_ "GenSigAutoGenSnd" SG_ 1731 signal9334 0;
BA_ "GenSigAutoGenDsp" SG_ 1731 signal9334 0;
BA_ "NMH-WakeupAllowed" SG_ 1731 signal9344 0;
BA_ "NWM-WakeupAllowed" SG_ 1731 signal9344 0;
BA_ "GenSigSendType" SG_ 1731 signal9344 7;
BA_ "GenSigEnvVarType" SG_ 1731 signal9344 0;
BA_ "GenSigAutoGenSnd" SG_ 1731 signal9344 0;
BA_ "GenSigAutoGenDsp" SG_ 1731 signal9344 0;
BA_ "NMH-WakeupAllowed" SG_ 1731 signal9354 0;
BA_ "NWM-WakeupAllowed" SG_ 1731 signal9354 0;
BA_ "GenSigSendType" SG_ 1731 signal9354 7;
BA_ "GenSigEnvVarType" SG_ 1731 signal9354 0;
BA_ "GenSigAutoGenSnd" SG_ 1731 signal9354 0;
BA_ "GenSigAutoGenDsp" SG_ 1731 signal9354 0;
BA_ "NMH-WakeupAllowed" SG_ 1731 signal9364 0;
BA_ "NWM-WakeupAllowed" SG_ 1731 signal9364 0;
BA_ "GenSigSendType" SG_ 1731 signal9364 7;
BA_ "GenSigEnvVarType" SG_ 1731 signal9364 0;
BA_ "GenSigAutoGenSnd" SG_ 1731 signal9364 0;
BA_ "GenSigAutoGenDsp" SG_ 1731 signal9364 0;
BA_ "NMH-WakeupAllowed" SG_ 1731 signal9404 0;
BA_ "NWM-WakeupAllowed" SG_ 1731 signal9404 0;
BA_ "GenSigSendType" SG_ 1731 signal9404 7;
BA_ "GenSigEnvVarType" SG_ 1731 signal9404 0;
BA_ "GenSigAutoGenSnd" SG_ 1731 signal9404 0;
BA_ "GenSigAutoGenDsp" SG_ 1731 signal9404 0;
BA_ "NMH-WakeupAllowed" SG_ 1731 signal9414 0;
BA_ "NWM-WakeupAllowed" SG_ 1731 signal9414 0;
BA_ "GenSigSendType" SG_ 1731 signal9414 7;
BA_ "GenSigEnvVarType" SG_ 1731 signal9414 0;
BA_ "GenSigAutoGenSnd" SG_ 1731 signal9414 0;
BA_ "GenSigAutoGenDsp" SG_ 1731 signal9414 0;
BA_ "NMH-WakeupAllowed" SG_ 1731 signal9424 0;
BA_ "NWM-WakeupAllowed" SG_ 1731 signal9424 0;
BA_ "GenSigSendType" SG_ 1731 signal9424 7;
BA_ "GenSigEnvVarType" SG_ 1731 signal9424 0;
BA_ "GenSigAutoGenSnd" SG_ 1731 signal9424 0;
BA_ "GenSigAutoGenDsp" SG_ 1731 signal9424 0;
BA_ "NMH-WakeupAllowed" SG_ 1731 signal9434 0;
BA_ "NWM-WakeupAllowed" SG_ 1731 signal9434 0;
BA_ "GenSigSendType" SG_ 1731 signal9434 7;
BA_ "GenSigEnvVarType" SG_ 1731 signal9434 0;
BA_ "GenSigAutoGenSnd" SG_ 1731 signal9434 0;
BA_ "GenSigAutoGenDsp" SG_ 1731 signal9434 0;
BA_ "GenSigTimeoutMsg_ecu12990" SG_ 1728 signal9450 1728;
BA_ "signal136198" SG_ 1728 signal9450 1728;
BA_ "signal133356" SG_ 1728 signal9450 1728;
BA_ "GenSigTimeoutMsg_ecu13120" SG_ 1728 signal9450 1728;
BA_ "GenSigTimeoutMsg_ecu11765" SG_ 1728 signal9450 1728;
BA_ "signal131970" SG_ 1728 signal9450 1728;
BA_ "signal131977" SG_ 1728 signal9450 1728;
BA_ "GenSigTimeoutMsg_ecu13186" SG_ 1728 signal9450 1728;
BA_ "GenSigTimeoutMsg_ecu9211" SG_ 1728 signal9450 1728;
BA_ "GenSigTimeoutMsg_ecu12594" SG_ 1728 signal9450 1728;
BA_ "NMH-WakeupAllowed" SG_ 1728 signal9450 0;
BA_ "NWM-WakeupAllowed" SG_ 1728 signal9450 0;
BA_ "GenSigStartValue" SG_ 1728 signal9450 1;
BA_ "GenSigSendType" SG_ 1728 signal9450 7;
BA_ "GenSigEnvVarType" SG_ 1728 signal9450 0;
BA_ "GenSigAutoGenSnd" SG_ 1728 signal9450 0;
BA_ "GenSigAutoGenDsp" SG_ 1728 signal9450 0;
BA_ "NMH-WakeupAllowed" SG_ 1728 signal9470 0;
BA_ "NWM-WakeupAllowed" SG_ 1728 signal9470 0;
BA_ "GenSigSendType" SG_ 1728 signal9470 7;
BA_ "GenSigEnvVarType" SG_ 1728 signal9470 0;
BA_ "GenSigAutoGenSnd" SG_ 1728 signal9470 0;
BA_ "GenSigAutoGenDsp" SG_ 1728 signal9470 0;
BA_ "NMH-WakeupAllowed" SG_ 1728 signal9480 0;
BA_ "NWM-WakeupAllowed" SG_ 1728 signal9480 0;
BA_ "GenSigSendType" SG_ 1728 signal9480 7;
BA_ "GenSigEnvVarType" SG_ 1728 signal9480 0;
BA_ "GenSigAutoGenSnd" SG_ 1728 signal9480 0;
BA_ "GenSigAutoGenDsp" SG_ 1728 signal9480 0;
BA_ "NMH-WakeupAllowed" SG_ 1728 signal9490 0;
BA_ "NWM-WakeupAllowed" SG_ 1728 signal9490 0;
BA_ "GenSigSendType" SG_ 1728 signal9490 7;
BA_ "GenSigEnvVarType" SG_ 1728 signal9490 0;
BA_ "GenSigAutoGenSnd" SG_ 1728 signal9490 0;
BA_ "GenSigAutoGenDsp" SG_ 1728 signal9490 0;
BA_ "NMH-WakeupAllowed" SG_ 1728 signal9500 0;
BA_ "NWM-WakeupAllowed" SG_ 1728 signal9500 0;
BA_ "GenSigSendType" SG_ 1728 signal9500 7;
BA_ "GenSigEnvVarType" SG_ 1728 signal9500 0;
BA_ "GenSigAutoGenSnd" SG_ 1728 signal9500 0;
BA_ "GenSigAutoGenDsp" SG_ 1728 signal9500 0;
BA_ "NMH-WakeupAllowed" SG_ 1728 signal9510 0;
BA_ "NWM-WakeupAllowed" SG_ 1728 signal9510 1;
BA_ "GenSigSendType" SG_ 1728 signal9510 7;
BA_ "GenSigEnvVarType" SG_ 1728 signal9510 0;
BA_ "GenSigAutoGenSnd" SG_ 1728 signal9510 0;
BA_ "GenSigAutoGenDsp" SG_ 1728 signal9510 0;
BA_ "NMH-WakeupAllowed" SG_ 1728 signal9520 0;
BA_ "NWM-WakeupAllowed" SG_ 1728 signal9520 1;
BA_ "GenSigSendType" SG_ 1728 signal9520 7;
BA_ "GenSigEnvVarType" SG_ 1728 signal9520 0;
BA_ "GenSigAutoGenSnd" SG_ 1728 signal9520 0;
BA_ "GenSigAutoGenDsp" SG_ 1728 signal9520 0;
BA_ "NMH-WakeupAllowed" SG_ 1728 signal9530 0;
BA_ "NWM-WakeupAllowed" SG_ 1728 signal9530 0;
BA_ "GenSigSendType" SG_ 1728 signal9530 7;
BA_ "GenSigEnvVarType" SG_ 1728 signal9530 0;
BA_ "GenSigAutoGenSnd" SG_ 1728 signal9530 0;
BA_ "GenSigAutoGenDsp" SG_ 1728 signal9530 0;
BA_ "NMH-WakeupAllowed" SG_ 1728 signal9540 0;
BA_ "NWM-WakeupAllowed" SG_ 1728 signal9540 0;
BA_ "GenSigSendType" SG_ 1728 signal9540 7;
BA_ "GenSigEnvVarType" SG_ 1728 signal9540 0;
BA_ "GenSigAutoGenSnd" SG_ 1728 signal9540 0;
BA_ "GenSigAutoGenDsp" SG_ 1728 signal9540 0;
BA_ "NMH-WakeupAllowed" SG_ 1728 signal9550 0;
BA_ "NWM-WakeupAllowed" SG_ 1728 signal9550 0;
BA_ "GenSigSendType" SG_ 1728 signal9550 7;
BA_ "GenSigEnvVarType" SG_ 1728 signal9550 0;
BA_ "GenSigAutoGenSnd" SG_ 1728 signal9550 0;
BA_ "GenSigAutoGenDsp" SG_ 1728 signal9550 0;
BA_ "NMH-WakeupAllowed" SG_ 1728 signal9560 0;
BA_ "NWM-WakeupAllowed" SG_ 1728 signal9560 0;
BA_ "GenSigSendType" SG_ 1728 signal9560 7;
BA_ "GenSigEnvVarType" SG_ 1728 signal9560 0;
BA_ "GenSigAutoGenSnd" SG_ 1728 signal9560 0;
BA_ "GenSigAutoGenDsp" SG_ 1728 signal9560 0;
BA_ "NMH-WakeupAllowed" SG_ 1728 signal9570 0;
BA_ "NWM-WakeupAllowed" SG_ 1728 signal9570 0;
BA_ "GenSigSendType" SG_ 1728 signal9570 7;
BA_ "GenSigEnvVarType" SG_ 1728 signal9570 0;
BA_ "GenSigAutoGenSnd" SG_ 1728 signal9570 0;
BA_ "GenSigAutoGenDsp" SG_ 1728 signal9570 0;
BA_ "NMH-WakeupAllowed" SG_ 1728 signal9580 0;
BA_ "NWM-WakeupAllowed" SG_ 1728 signal9580 0;
BA_ "GenSigSendType" SG_ 1728 signal9580 7;
BA_ "GenSigEnvVarType" SG_ 1728 signal9580 0;
BA_ "GenSigAutoGenSnd" SG_ 1728 signal9580 0;
BA_ "GenSigAutoGenDsp" SG_ 1728 signal9580 0;
BA_ "NMH-WakeupAllowed" SG_ 1728 signal9590 0;
BA_ "NWM-WakeupAllowed" SG_ 1728 signal9590 0;
BA_ "GenSigSendType" SG_ 1728 signal9590 7;
BA_ "GenSigEnvVarType" SG_ 1728 signal9590 0;
BA_ "GenSigAutoGenSnd" SG_ 1728 signal9590 0;
BA_ "GenSigAutoGenDsp" SG_ 1728 signal9590 0;
BA_ "NMH-WakeupAllowed" SG_ 1728 signal9600 0;
BA_ "NWM-WakeupAllowed" SG_ 1728 signal9600 0;
BA_ "GenSigSendType" SG_ 1728 signal9600 7;
BA_ "GenSigEnvVarType" SG_ 1728 signal9600 0;
BA_ "GenSigAutoGenSnd" SG_ 1728 signal9600 0;
BA_ "GenSigAutoGenDsp" SG_ 1728 signal9600 0;
BA_ "NMH-WakeupAllowed" SG_ 1728 signal9610 0;
BA_ "NWM-WakeupAllowed" SG_ 1728 signal9610 0;
BA_ "GenSigSendType" SG_ 1728 signal9610 7;
BA_ "GenSigEnvVarType" SG_ 1728 signal9610 0;
BA_ "GenSigAutoGenSnd" SG_ 1728 signal9610 0;
BA_ "GenSigAutoGenDsp" SG_ 1728 signal9610 0;
BA_ "NMH-WakeupAllowed" SG_ 1728 signal9620 0;
BA_ "NWM-WakeupAllowed" SG_ 1728 signal9620 0;
BA_ "GenSigSendType" SG_ 1728 signal9620 7;
BA_ "GenSigEnvVarType" SG_ 1728 signal9620 0;
BA_ "GenSigAutoGenSnd" SG_ 1728 signal9620 0;
BA_ "GenSigAutoGenDsp" SG_ 1728 signal9620 0;
BA_ "NMH-WakeupAllowed" SG_ 1728 signal9630 0;
BA_ "NWM-WakeupAllowed" SG_ 1728 signal9630 0;
BA_ "GenSigSendType" SG_ 1728 signal9630 7;
BA_ "GenSigEnvVarType" SG_ 1728 signal9630 0;
BA_ "GenSigAutoGenSnd" SG_ 1728 signal9630 0;
BA_ "GenSigAutoGenDsp" SG_ 1728 signal9630 0;
BA_ "NMH-WakeupAllowed" SG_ 1728 signal9640 0;
BA_ "NWM-WakeupAllowed" SG_ 1728 signal9640 0;
BA_ "GenSigSendType" SG_ 1728 signal9640 7;
BA_ "GenSigEnvVarType" SG_ 1728 signal9640 0;
BA_ "GenSigAutoGenSnd" SG_ 1728 signal9640 0;
BA_ "GenSigAutoGenDsp" SG_ 1728 signal9640 0;
BA_ "NMH-WakeupAllowed" SG_ 1728 signal9650 0;
BA_ "NWM-WakeupAllowed" SG_ 1728 signal9650 0;
BA_ "GenSigSendType" SG_ 1728 signal9650 7;
BA_ "GenSigEnvVarType" SG_ 1728 signal9650 0;
BA_ "GenSigAutoGenSnd" SG_ 1728 signal9650 0;
BA_ "GenSigAutoGenDsp" SG_ 1728 signal9650 0;
BA_ "NMH-WakeupAllowed" SG_ 1728 signal9660 0;
BA_ "NWM-WakeupAllowed" SG_ 1728 signal9660 0;
BA_ "GenSigSendType" SG_ 1728 signal9660 7;
BA_ "GenSigEnvVarType" SG_ 1728 signal9660 0;
BA_ "GenSigAutoGenSnd" SG_ 1728 signal9660 0;
BA_ "GenSigAutoGenDsp" SG_ 1728 signal9660 0;
BA_ "NMH-WakeupAllowed" SG_ 1728 signal9670 0;
BA_ "NWM-WakeupAllowed" SG_ 1728 signal9670 0;
BA_ "GenSigSendType" SG_ 1728 signal9670 7;
BA_ "GenSigEnvVarType" SG_ 1728 signal9670 0;
BA_ "GenSigAutoGenSnd" SG_ 1728 signal9670 0;
BA_ "GenSigAutoGenDsp" SG_ 1728 signal9670 0;
BA_ "NMH-WakeupAllowed" SG_ 1728 signal9680 0;
BA_ "NWM-WakeupAllowed" SG_ 1728 signal9680 0;
BA_ "GenSigSendType" SG_ 1728 signal9680 7;
BA_ "GenSigEnvVarType" SG_ 1728 signal9680 0;
BA_ "GenSigAutoGenSnd" SG_ 1728 signal9680 0;
BA_ "GenSigAutoGenDsp" SG_ 1728 signal9680 0;
BA_ "NMH-WakeupAllowed" SG_ 1728 signal9690 0;
BA_ "NWM-WakeupAllowed" SG_ 1728 signal9690 0;
BA_ "GenSigSendType" SG_ 1728 signal9690 7;
BA_ "GenSigEnvVarType" SG_ 1728 signal9690 0;
BA_ "GenSigAutoGenSnd" SG_ 1728 signal9690 0;
BA_ "GenSigAutoGenDsp" SG_ 1728 signal9690 0;
BA_ "NMH-WakeupAllowed" SG_ 1728 signal9700 0;
BA_ "NWM-WakeupAllowed" SG_ 1728 signal9700 0;
BA_ "GenSigSendType" SG_ 1728 signal9700 7;
BA_ "GenSigEnvVarType" SG_ 1728 signal9700 0;
BA_ "GenSigAutoGenSnd" SG_ 1728 signal9700 0;
BA_ "GenSigAutoGenDsp" SG_ 1728 signal9700 0;
BA_ "NMH-WakeupAllowed" SG_ 1728 signal9710 0;
BA_ "NWM-WakeupAllowed" SG_ 1728 signal9710 0;
BA_ "GenSigSendType" SG_ 1728 signal9710 7;
BA_ "GenSigEnvVarType" SG_ 1728 signal9710 0;
BA_ "GenSigAutoGenSnd" SG_ 1728 signal9710 0;
BA_ "GenSigAutoGenDsp" SG_ 1728 signal9710 0;
BA_ "NMH-WakeupAllowed" SG_ 1728 signal9720 0;
BA_ "NWM-WakeupAllowed" SG_ 1728 signal9720 0;
BA_ "GenSigSendType" SG_ 1728 signal9720 7;
BA_ "GenSigEnvVarType" SG_ 1728 signal9720 0;
BA_ "GenSigAutoGenSnd" SG_ 1728 signal9720 0;
BA_ "GenSigAutoGenDsp" SG_ 1728 signal9720 0;
BA_ "NMH-WakeupAllowed" SG_ 1728 signal9730 0;
BA_ "NWM-WakeupAllowed" SG_ 1728 signal9730 0;
BA_ "GenSigSendType" SG_ 1728 signal9730 7;
BA_ "GenSigEnvVarType" SG_ 1728 signal9730 0;
BA_ "GenSigAutoGenSnd" SG_ 1728 signal9730 0;
BA_ "GenSigAutoGenDsp" SG_ 1728 signal9730 0;
BA_ "GenSigTimeoutMsg_ecu12990" SG_ 1730 signal9746 1730;
BA_ "signal136198" SG_ 1730 signal9746 1730;
BA_ "signal133356" SG_ 1730 signal9746 1730;
BA_ "GenSigTimeoutMsg_ecu13120" SG_ 1730 signal9746 1730;
BA_ "GenSigTimeoutMsg_ecu11765" SG_ 1730 signal9746 1730;
BA_ "signal131970" SG_ 1730 signal9746 1730;
BA_ "signal131977" SG_ 1730 signal9746 1730;
BA_ "GenSigTimeoutMsg_ecu13186" SG_ 1730 signal9746 1730;
BA_ "GenSigTimeoutMsg_ecu9211" SG_ 1730 signal9746 1730;
BA_ "GenSigTimeoutMsg_ecu12594" SG_ 1730 signal9746 1730;
BA_ "NMH-WakeupAllowed" SG_ 1730 signal9746 0;
BA_ "NWM-WakeupAllowed" SG_ 1730 signal9746 0;
BA_ "GenSigStartValue" SG_ 1730 signal9746 1;
BA_ "GenSigSendType" SG_ 1730 signal9746 7;
BA_ "GenSigEnvVarType" SG_ 1730 signal9746 0;
BA_ "GenSigAutoGenSnd" SG_ 1730 signal9746 0;
BA_ "GenSigAutoGenDsp" SG_ 1730 signal9746 0;
BA_ "NMH-WakeupAllowed" SG_ 1730 signal9766 0;
BA_ "NWM-WakeupAllowed" SG_ 1730 signal9766 0;
BA_ "GenSigSendType" SG_ 1730 signal9766 7;
BA_ "GenSigEnvVarType" SG_ 1730 signal9766 0;
BA_ "GenSigAutoGenSnd" SG_ 1730 signal9766 0;
BA_ "GenSigAutoGenDsp" SG_ 1730 signal9766 0;
BA_ "NMH-WakeupAllowed" SG_ 1730 signal9776 0;
BA_ "NWM-WakeupAllowed" SG_ 1730 signal9776 0;
BA_ "GenSigSendType" SG_ 1730 signal9776 7;
BA_ "GenSigEnvVarType" SG_ 1730 signal9776 0;
BA_ "GenSigAutoGenSnd" SG_ 1730 signal9776 0;
BA_ "GenSigAutoGenDsp" SG_ 1730 signal9776 0;
BA_ "NMH-WakeupAllowed" SG_ 1730 signal9786 0;
BA_ "NWM-WakeupAllowed" SG_ 1730 signal9786 0;
BA_ "GenSigSendType" SG_ 1730 signal9786 7;
BA_ "GenSigEnvVarType" SG_ 1730 signal9786 0;
BA_ "GenSigAutoGenSnd" SG_ 1730 signal9786 0;
BA_ "GenSigAutoGenDsp" SG_ 1730 signal9786 0;
BA_ "NMH-WakeupAllowed" SG_ 1730 signal9796 0;
BA_ "NWM-WakeupAllowed" SG_ 1730 signal9796 0;
BA_ "GenSigSendType" SG_ 1730 signal9796 7;
BA_ "GenSigEnvVarType" SG_ 1730 signal9796 0;
BA_ "GenSigAutoGenSnd" SG_ 1730 signal9796 0;
BA_ "GenSigAutoGenDsp" SG_ 1730 signal9796 0;
BA_ "NMH-WakeupAllowed" SG_ 1730 signal9806 0;
BA_ "NWM-WakeupAllowed" SG_ 1730 signal9806 1;
BA_ "GenSigSendType" SG_ 1730 signal9806 7;
BA_ "GenSigEnvVarType" SG_ 1730 signal9806 0;
BA_ "GenSigAutoGenSnd" SG_ 1730 signal9806 0;
BA_ "GenSigAutoGenDsp" SG_ 1730 signal9806 0;
BA_ "NMH-WakeupAllowed" SG_ 1730 signal9816 0;
BA_ "NWM-WakeupAllowed" SG_ 1730 signal9816 1;
BA_ "GenSigSendType" SG_ 1730 signal9816 7;
BA_ "GenSigEnvVarType" SG_ 1730 signal9816 0;
BA_ "GenSigAutoGenSnd" SG_ 1730 signal9816 0;
BA_ "GenSigAutoGenDsp" SG_ 1730 signal9816 0;
BA_ "NMH-WakeupAllowed" SG_ 1730 signal9826 0;
BA_ "NWM-WakeupAllowed" SG_ 1730 signal9826 0;
BA_ "GenSigSendType" SG_ 1730 signal9826 7;
BA_ "GenSigEnvVarType" SG_ 1730 signal9826 0;
BA_ "GenSigAutoGenSnd" SG_ 1730 signal9826 0;
BA_ "GenSigAutoGenDsp" SG_ 1730 signal9826 0;
BA_ "NMH-WakeupAllowed" SG_ 1730 signal9836 0;
BA_ "NWM-WakeupAllowed" SG_ 1730 signal9836 0;
BA_ "GenSigSendType" SG_ 1730 signal9836 7;
BA_ "GenSigEnvVarType" SG_ 1730 signal9836 0;
BA_ "GenSigAutoGenSnd" SG_ 1730 signal9836 0;
BA_ "GenSigAutoGenDsp" SG_ 1730 signal9836 0;
BA_ "NMH-WakeupAllowed" SG_ 1730 signal9846 0;
BA_ "NWM-WakeupAllowed" SG_ 1730 signal9846 0;
BA_ "GenSigSendType" SG_ 1730 signal9846 7;
BA_ "GenSigEnvVarType" SG_ 1730 signal9846 0;
BA_ "GenSigAutoGenSnd" SG_ 1730 signal9846 0;
BA_ "GenSigAutoGenDsp" SG_ 1730 signal9846 0;
BA_ "NMH-WakeupAllowed" SG_ 1730 signal9856 0;
BA_ "NWM-WakeupAllowed" SG_ 1730 signal9856 0;
BA_ "GenSigSendType" SG_ 1730 signal9856 7;
BA_ "GenSigEnvVarType" SG_ 1730 signal9856 0;
BA_ "GenSigAutoGenSnd" SG_ 1730 signal9856 0;
BA_ "GenSigAutoGenDsp" SG_ 1730 signal9856 0;
BA_ "NMH-WakeupAllowed" SG_ 1730 signal9866 0;
BA_ "NWM-WakeupAllowed" SG_ 1730 signal9866 0;
BA_ "GenSigSendType" SG_ 1730 signal9866 7;
BA_ "GenSigEnvVarType" SG_ 1730 signal9866 0;
BA_ "GenSigAutoGenSnd" SG_ 1730 signal9866 0;
BA_ "GenSigAutoGenDsp" SG_ 1730 signal9866 0;
BA_ "NMH-WakeupAllowed" SG_ 1730 signal9876 0;
BA_ "NWM-WakeupAllowed" SG_ 1730 signal9876 0;
BA_ "GenSigSendType" SG_ 1730 signal9876 7;
BA_ "GenSigEnvVarType" SG_ 1730 signal9876 0;
BA_ "GenSigAutoGenSnd" SG_ 1730 signal9876 0;
BA_ "GenSigAutoGenDsp" SG_ 1730 signal9876 0;
BA_ "NMH-WakeupAllowed" SG_ 1730 signal9886 0;
BA_ "NWM-WakeupAllowed" SG_ 1730 signal9886 0;
BA_ "GenSigSendType" SG_ 1730 signal9886 7;
BA_ "GenSigEnvVarType" SG_ 1730 signal9886 0;
BA_ "GenSigAutoGenSnd" SG_ 1730 signal9886 0;
BA_ "GenSigAutoGenDsp" SG_ 1730 signal9886 0;
BA_ "NMH-WakeupAllowed" SG_ 1730 signal9896 0;
BA_ "NWM-WakeupAllowed" SG_ 1730 signal9896 0;
BA_ "GenSigSendType" SG_ 1730 signal9896 7;
BA_ "GenSigEnvVarType" SG_ 1730 signal9896 0;
BA_ "GenSigAutoGenSnd" SG_ 1730 signal9896 0;
BA_ "GenSigAutoGenDsp" SG_ 1730 signal9896 0;
BA_ "NMH-WakeupAllowed" SG_ 1730 signal9906 0;
BA_ "NWM-WakeupAllowed" SG_ 1730 signal9906 0;
BA_ "GenSigSendType" SG_ 1730 signal9906 7;
BA_ "GenSigEnvVarType" SG_ 1730 signal9906 0;
BA_ "GenSigAutoGenSnd" SG_ 1730 signal9906 0;
BA_ "GenSigAutoGenDsp" SG_ 1730 signal9906 0;
BA_ "NMH-WakeupAllowed" SG_ 1730 signal9916 0;
BA_ "NWM-WakeupAllowed" SG_ 1730 signal9916 0;
BA_ "GenSigSendType" SG_ 1730 signal9916 7;
BA_ "GenSigEnvVarType" SG_ 1730 signal9916 0;
BA_ "GenSigAutoGenSnd" SG_ 1730 signal9916 0;
BA_ "GenSigAutoGenDsp" SG_ 1730 signal9916 0;
BA_ "NMH-WakeupAllowed" SG_ 1730 signal9926 0;
BA_ "NWM-WakeupAllowed" SG_ 1730 signal9926 0;
BA_ "GenSigSendType" SG_ 1730 signal9926 7;
BA_ "GenSigEnvVarType" SG_ 1730 signal9926 0;
BA_ "GenSigAutoGenSnd" SG_ 1730 signal9926 0;
BA_ "GenSigAutoGenDsp" SG_ 1730 signal9926 0;
BA_ "NMH-WakeupAllowed" SG_ 1730 signal9936 0;
BA_ "NWM-WakeupAllowed" SG_ 1730 signal9936 0;
BA_ "GenSigSendType" SG_ 1730 signal9936 7;
BA_ "GenSigEnvVarType" SG_ 1730 signal9936 0;
BA_ "GenSigAutoGenSnd" SG_ 1730 signal9936 0;
BA_ "GenSigAutoGenDsp" SG_ 1730 signal9936 0;
BA_ "NMH-WakeupAllowed" SG_ 1730 signal9946 0;
BA_ "NWM-WakeupAllowed" SG_ 1730 signal9946 0;
BA_ "GenSigSendType" SG_ 1730 signal9946 7;
BA_ "GenSigEnvVarType" SG_ 1730 signal9946 0;
BA_ "GenSigAutoGenSnd" SG_ 1730 signal9946 0;
BA_ "GenSigAutoGenDsp" SG_ 1730 signal9946 0;
BA_ "NMH-WakeupAllowed" SG_ 1730 signal9956 0;
BA_ "NWM-WakeupAllowed" SG_ 1730 signal9956 0;
BA_ "GenSigSendType" SG_ 1730 signal9956 7;
BA_ "GenSigEnvVarType" SG_ 1730 signal9956 0;
BA_ "GenSigAutoGenSnd" SG_ 1730 signal9956 0;
BA_ "GenSigAutoGenDsp" SG_ 1730 signal9956 0;
BA_ "NMH-WakeupAllowed" SG_ 1730 signal9966 0;
BA_ "NWM-WakeupAllowed" SG_ 1730 signal9966 0;
BA_ "GenSigSendType" SG_ 1730 signal9966 7;
BA_ "GenSigEnvVarType" SG_ 1730 signal9966 0;
BA_ "GenSigAutoGenSnd" SG_ 1730 signal9966 0;
BA_ "GenSigAutoGenDsp" SG_ 1730 signal9966 0;
BA_ "NMH-WakeupAllowed" SG_ 1730 signal9976 0;
BA_ "NWM-WakeupAllowed" SG_ 1730 signal9976 0;
BA_ "GenSigSendType" SG_ 1730 signal9976 7;
BA_ "GenSigEnvVarType" SG_ 1730 signal9976 0;
BA_ "GenSigAutoGenSnd" SG_ 1730 signal9976 0;
BA_ "GenSigAutoGenDsp" SG_ 1730 signal9976 0;
BA_ "GenSigTimeoutMsg_ecu12990" SG_ 1729 signal9992 1729;
BA_ "signal136198" SG_ 1729 signal9992 1729;
BA_ "signal133356" SG_ 1729 signal9992 1729;
BA_ "GenSigTimeoutMsg_ecu13120" SG_ 1729 signal9992 1729;
BA_ "GenSigTimeoutMsg_ecu11765" SG_ 1729 signal9992 1729;
BA_ "signal131970" SG_ 1729 signal9992 1729;
BA_ "signal131977" SG_ 1729 signal9992 1729;
BA_ "GenSigTimeoutMsg_ecu13186" SG_ 1729 signal9992 1729;
BA_ "GenSigTimeoutMsg_ecu9211" SG_ 1729 signal9992 1729;
BA_ "GenSigTimeoutMsg_ecu12594" SG_ 1729 signal9992 1729;
BA_ "NMH-WakeupAllowed" SG_ 1729 signal9992 0;
BA_ "NWM-WakeupAllowed" SG_ 1729 signal9992 0;
BA_ "GenSigStartValue" SG_ 1729 signal9992 1;
BA_ "GenSigSendType" SG_ 1729 signal9992 7;
BA_ "GenSigEnvVarType" SG_ 1729 signal9992 0;
BA_ "GenSigAutoGenSnd" SG_ 1729 signal9992 0;
BA_ "GenSigAutoGenDsp" SG_ 1729 signal9992 0;
BA_ "NMH-WakeupAllowed" SG_ 1729 signal10012 0;
BA_ "NWM-WakeupAllowed" SG_ 1729 signal10012 0;
BA_ "GenSigSendType" SG_ 1729 signal10012 7;
BA_ "GenSigEnvVarType" SG_ 1729 signal10012 0;
BA_ "GenSigAutoGenSnd" SG_ 1729 signal10012 0;
BA_ "GenSigAutoGenDsp" SG_ 1729 signal10012 0;
BA_ "NMH-WakeupAllowed" SG_ 1729 signal10022 0;
BA_ "NWM-WakeupAllowed" SG_ 1729 signal10022 0;
BA_ "GenSigSendType" SG_ 1729 signal10022 7;
BA_ "GenSigEnvVarType" SG_ 1729 signal10022 0;
BA_ "GenSigAutoGenSnd" SG_ 1729 signal10022 0;
BA_ "GenSigAutoGenDsp" SG_ 1729 signal10022 0;
BA_ "NMH-WakeupAllowed" SG_ 1729 signal10032 0;
BA_ "NWM-WakeupAllowed" SG_ 1729 signal10032 0;
BA_ "GenSigSendType" SG_ 1729 signal10032 7;
BA_ "GenSigEnvVarType" SG_ 1729 signal10032 0;
BA_ "GenSigAutoGenSnd" SG_ 1729 signal10032 0;
BA_ "GenSigAutoGenDsp" SG_ 1729 signal10032 0;
BA_ "NMH-WakeupAllowed" SG_ 1729 signal10042 0;
BA_ "NWM-WakeupAllowed" SG_ 1729 signal10042 0;
BA_ "GenSigSendType" SG_ 1729 signal10042 7;
BA_ "GenSigEnvVarType" SG_ 1729 signal10042 0;
BA_ "GenSigAutoGenSnd" SG_ 1729 signal10042 0;
BA_ "GenSigAutoGenDsp" SG_ 1729 signal10042 0;
BA_ "NMH-WakeupAllowed" SG_ 1729 signal10052 0;
BA_ "NWM-WakeupAllowed" SG_ 1729 signal10052 1;
BA_ "GenSigSendType" SG_ 1729 signal10052 7;
BA_ "GenSigEnvVarType" SG_ 1729 signal10052 0;
BA_ "GenSigAutoGenSnd" SG_ 1729 signal10052 0;
BA_ "GenSigAutoGenDsp" SG_ 1729 signal10052 0;
BA_ "NMH-WakeupAllowed" SG_ 1729 signal10062 0;
BA_ "NWM-WakeupAllowed" SG_ 1729 signal10062 1;
BA_ "GenSigSendType" SG_ 1729 signal10062 7;
BA_ "GenSigEnvVarType" SG_ 1729 signal10062 0;
BA_ "GenSigAutoGenSnd" SG_ 1729 signal10062 0;
BA_ "GenSigAutoGenDsp" SG_ 1729 signal10062 0;
BA_ "NMH-WakeupAllowed" SG_ 1729 signal10072 0;
BA_ "NWM-WakeupAllowed" SG_ 1729 signal10072 0;
BA_ "GenSigSendType" SG_ 1729 signal10072 7;
BA_ "GenSigEnvVarType" SG_ 1729 signal10072 0;
BA_ "GenSigAutoGenSnd" SG_ 1729 signal10072 0;
BA_ "GenSigAutoGenDsp" SG_ 1729 signal10072 0;
BA_ "NMH-WakeupAllowed" SG_ 1729 signal10082 0;
BA_ "NWM-WakeupAllowed" SG_ 1729 signal10082 0;
BA_ "GenSigSendType" SG_ 1729 signal10082 7;
BA_ "GenSigEnvVarType" SG_ 1729 signal10082 0;
BA_ "GenSigAutoGenSnd" SG_ 1729 signal10082 0;
BA_ "GenSigAutoGenDsp" SG_ 1729 signal10082 0;
BA_ "NMH-WakeupAllowed" SG_ 1729 signal10092 0;
BA_ "NWM-WakeupAllowed" SG_ 1729 signal10092 0;
BA_ "GenSigSendType" SG_ 1729 signal10092 7;
BA_ "GenSigEnvVarType" SG_ 1729 signal10092 0;
BA_ "GenSigAutoGenSnd" SG_ 1729 signal10092 0;
BA_ "GenSigAutoGenDsp" SG_ 1729 signal10092 0;
BA_ "NMH-WakeupAllowed" SG_ 1729 signal10102 0;
BA_ "NWM-WakeupAllowed" SG_ 1729 signal10102 0;
BA_ "GenSigSendType" SG_ 1729 signal10102 7;
BA_ "GenSigEnvVarType" SG_ 1729 signal10102 0;
BA_ "GenSigAutoGenSnd" SG_ 1729 signal10102 0;
BA_ "GenSigAutoGenDsp" SG_ 1729 signal10102 0;
BA_ "NMH-WakeupAllowed" SG_ 1729 signal10112 0;
BA_ "NWM-WakeupAllowed" SG_ 1729 signal10112 0;
BA_ "GenSigSendType" SG_ 1729 signal10112 7;
BA_ "GenSigEnvVarType" SG_ 1729 signal10112 0;
BA_ "GenSigAutoGenSnd" SG_ 1729 signal10112 0;
BA_ "GenSigAutoGenDsp" SG_ 1729 signal10112 0;
BA_ "NMH-WakeupAllowed" SG_ 1729 signal10122 0;
BA_ "NWM-WakeupAllowed" SG_ 1729 signal10122 0;
BA_ "GenSigSendType" SG_ 1729 signal10122 7;
BA_ "GenSigEnvVarType" SG_ 1729 signal10122 0;
BA_ "GenSigAutoGenSnd" SG_ 1729 signal10122 0;
BA_ "GenSigAutoGenDsp" SG_ 1729 signal10122 0;
BA_ "NMH-WakeupAllowed" SG_ 1729 signal10132 0;
BA_ "NWM-WakeupAllowed" SG_ 1729 signal10132 0;
BA_ "GenSigSendType" SG_ 1729 signal10132 7;
BA_ "GenSigEnvVarType" SG_ 1729 signal10132 0;
BA_ "GenSigAutoGenSnd" SG_ 1729 signal10132 0;
BA_ "GenSigAutoGenDsp" SG_ 1729 signal10132 0;
BA_ "NMH-WakeupAllowed" SG_ 1729 signal10142 0;
BA_ "NWM-WakeupAllowed" SG_ 1729 signal10142 0;
BA_ "GenSigSendType" SG_ 1729 signal10142 7;
BA_ "GenSigEnvVarType" SG_ 1729 signal10142 0;
BA_ "GenSigAutoGenSnd" SG_ 1729 signal10142 0;
BA_ "GenSigAutoGenDsp" SG_ 1729 signal10142 0;
BA_ "NMH-WakeupAllowed" SG_ 1729 signal10152 0;
BA_ "NWM-WakeupAllowed" SG_ 1729 signal10152 0;
BA_ "GenSigSendType" SG_ 1729 signal10152 7;
BA_ "GenSigEnvVarType" SG_ 1729 signal10152 0;
BA_ "GenSigAutoGenSnd" SG_ 1729 signal10152 0;
BA_ "GenSigAutoGenDsp" SG_ 1729 signal10152 0;
BA_ "NMH-WakeupAllowed" SG_ 1729 signal10172 0;
BA_ "NWM-WakeupAllowed" SG_ 1729 signal10172 0;
BA_ "GenSigSendType" SG_ 1729 signal10172 7;
BA_ "GenSigEnvVarType" SG_ 1729 signal10172 0;
BA_ "GenSigAutoGenSnd" SG_ 1729 signal10172 0;
BA_ "GenSigAutoGenDsp" SG_ 1729 signal10172 0;
BA_ "NMH-WakeupAllowed" SG_ 1729 signal10182 0;
BA_ "NWM-WakeupAllowed" SG_ 1729 signal10182 0;
BA_ "GenSigSendType" SG_ 1729 signal10182 7;
BA_ "GenSigEnvVarType" SG_ 1729 signal10182 0;
BA_ "GenSigAutoGenSnd" SG_ 1729 signal10182 0;
BA_ "GenSigAutoGenDsp" SG_ 1729 signal10182 0;
BA_ "NMH-WakeupAllowed" SG_ 1729 signal10192 0;
BA_ "NWM-WakeupAllowed" SG_ 1729 signal10192 0;
BA_ "GenSigSendType" SG_ 1729 signal10192 7;
BA_ "GenSigEnvVarType" SG_ 1729 signal10192 0;
BA_ "GenSigAutoGenSnd" SG_ 1729 signal10192 0;
BA_ "GenSigAutoGenDsp" SG_ 1729 signal10192 0;
BA_ "NMH-WakeupAllowed" SG_ 1729 signal10202 0;
BA_ "NWM-WakeupAllowed" SG_ 1729 signal10202 0;
BA_ "GenSigSendType" SG_ 1729 signal10202 7;
BA_ "GenSigEnvVarType" SG_ 1729 signal10202 0;
BA_ "GenSigAutoGenSnd" SG_ 1729 signal10202 0;
BA_ "GenSigAutoGenDsp" SG_ 1729 signal10202 0;
BA_ "NMH-WakeupAllowed" SG_ 1729 signal10212 0;
BA_ "NWM-WakeupAllowed" SG_ 1729 signal10212 0;
BA_ "GenSigSendType" SG_ 1729 signal10212 7;
BA_ "GenSigEnvVarType" SG_ 1729 signal10212 0;
BA_ "GenSigAutoGenSnd" SG_ 1729 signal10212 0;
BA_ "GenSigAutoGenDsp" SG_ 1729 signal10212 0;
BA_ "NMH-WakeupAllowed" SG_ 1729 signal10222 0;
BA_ "NWM-WakeupAllowed" SG_ 1729 signal10222 0;
BA_ "GenSigSendType" SG_ 1729 signal10222 7;
BA_ "GenSigEnvVarType" SG_ 1729 signal10222 0;
BA_ "GenSigAutoGenSnd" SG_ 1729 signal10222 0;
BA_ "GenSigAutoGenDsp" SG_ 1729 signal10222 0;
BA_ "NMH-WakeupAllowed" SG_ 1729 signal10232 0;
BA_ "NWM-WakeupAllowed" SG_ 1729 signal10232 0;
BA_ "GenSigSendType" SG_ 1729 signal10232 7;
BA_ "GenSigEnvVarType" SG_ 1729 signal10232 0;
BA_ "GenSigAutoGenSnd" SG_ 1729 signal10232 0;
BA_ "GenSigAutoGenDsp" SG_ 1729 signal10232 0;
BA_ "NMH-WakeupAllowed" SG_ 1729 signal10242 0;
BA_ "NWM-WakeupAllowed" SG_ 1729 signal10242 0;
BA_ "GenSigSendType" SG_ 1729 signal10242 7;
BA_ "GenSigEnvVarType" SG_ 1729 signal10242 0;
BA_ "GenSigAutoGenSnd" SG_ 1729 signal10242 0;
BA_ "GenSigAutoGenDsp" SG_ 1729 signal10242 0;
BA_ "NMH-WakeupAllowed" SG_ 1744 signal10338 0;
BA_ "NWM-WakeupAllowed" SG_ 1744 signal10338 0;
BA_ "GenSigSendType" SG_ 1744 signal10338 7;
BA_ "GenSigEnvVarType" SG_ 1744 signal10338 0;
BA_ "GenSigAutoGenSnd" SG_ 1744 signal10338 0;
BA_ "GenSigAutoGenDsp" SG_ 1744 signal10338 0;
BA_ "NMH-WakeupAllowed" SG_ 1744 signal10348 0;
BA_ "NWM-WakeupAllowed" SG_ 1744 signal10348 0;
BA_ "GenSigSendType" SG_ 1744 signal10348 7;
BA_ "GenSigEnvVarType" SG_ 1744 signal10348 0;
BA_ "GenSigAutoGenSnd" SG_ 1744 signal10348 0;
BA_ "GenSigAutoGenDsp" SG_ 1744 signal10348 0;
BA_ "NMH-WakeupAllowed" SG_ 1744 signal10388 0;
BA_ "NWM-WakeupAllowed" SG_ 1744 signal10388 0;
BA_ "GenSigSendType" SG_ 1744 signal10388 7;
BA_ "GenSigEnvVarType" SG_ 1744 signal10388 0;
BA_ "GenSigAutoGenSnd" SG_ 1744 signal10388 0;
BA_ "GenSigAutoGenDsp" SG_ 1744 signal10388 0;
BA_ "NMH-WakeupAllowed" SG_ 1744 signal10448 0;
BA_ "NWM-WakeupAllowed" SG_ 1744 signal10448 0;
BA_ "GenSigSendType" SG_ 1744 signal10448 7;
BA_ "GenSigEnvVarType" SG_ 1744 signal10448 0;
BA_ "GenSigAutoGenSnd" SG_ 1744 signal10448 0;
BA_ "GenSigAutoGenDsp" SG_ 1744 signal10448 0;
BA_ "NMH-WakeupAllowed" SG_ 1744 signal10458 0;
BA_ "NWM-WakeupAllowed" SG_ 1744 signal10458 0;
BA_ "GenSigSendType" SG_ 1744 signal10458 7;
BA_ "GenSigEnvVarType" SG_ 1744 signal10458 0;
BA_ "GenSigAutoGenSnd" SG_ 1744 signal10458 0;
BA_ "GenSigAutoGenDsp" SG_ 1744 signal10458 0;
BA_ "GenSigTimeoutMsg_ecu11765" SG_ 913 signal10494 913;
BA_ "signal131970" SG_ 913 signal10494 913;
BA_ "signal131977" SG_ 913 signal10494 913;
BA_ "NMH-WakeupAllowed" SG_ 913 signal10494 0;
BA_ "NWM-WakeupAllowed" SG_ 913 signal10494 0;
BA_ "GenSigStartValue" SG_ 913 signal10494 255;
BA_ "GenSigSendType" SG_ 913 signal10494 7;
BA_ "GenSigEnvVarType" SG_ 913 signal10494 1;
BA_ "GenSigAutoGenSnd" SG_ 913 signal10494 1;
BA_ "GenSigAutoGenDsp" SG_ 913 signal10494 1;
BA_ "GenSigTimeoutMsg_ecu11765" SG_ 913 signal10507 913;
BA_ "signal131970" SG_ 913 signal10507 913;
BA_ "signal131977" SG_ 913 signal10507 913;
BA_ "NMH-WakeupAllowed" SG_ 913 signal10507 0;
BA_ "NWM-WakeupAllowed" SG_ 913 signal10507 0;
BA_ "GenSigStartValue" SG_ 913 signal10507 255;
BA_ "GenSigSendType" SG_ 913 signal10507 7;
BA_ "GenSigEnvVarType" SG_ 913 signal10507 0;
BA_ "GenSigAutoGenSnd" SG_ 913 signal10507 1;
BA_ "GenSigAutoGenDsp" SG_ 913 signal10507 1;
BA_ "GenSigTimeoutMsg_ecu11765" SG_ 913 signal10520 913;
BA_ "signal131970" SG_ 913 signal10520 913;
BA_ "signal131977" SG_ 913 signal10520 913;
BA_ "NMH-WakeupAllowed" SG_ 913 signal10520 0;
BA_ "NWM-WakeupAllowed" SG_ 913 signal10520 0;
BA_ "GenSigStartValue" SG_ 913 signal10520 255;
BA_ "GenSigSendType" SG_ 913 signal10520 7;
BA_ "GenSigEnvVarType" SG_ 913 signal10520 1;
BA_ "GenSigAutoGenSnd" SG_ 913 signal10520 1;
BA_ "GenSigAutoGenDsp" SG_ 913 signal10520 1;
BA_ "GenSigTimeoutMsg_ecu11765" SG_ 913 signal10533 913;
BA_ "signal131970" SG_ 913 signal10533 913;
BA_ "signal131977" SG_ 913 signal10533 913;
BA_ "NMH-WakeupAllowed" SG_ 913 signal10533 0;
BA_ "NWM-WakeupAllowed" SG_ 913 signal10533 0;
BA_ "GenSigStartValue" SG_ 913 signal10533 65535;
BA_ "GenSigSendType" SG_ 913 signal10533 7;
BA_ "GenSigEnvVarType" SG_ 913 signal10533 1;
BA_ "GenSigAutoGenSnd" SG_ 913 signal10533 1;
BA_ "GenSigAutoGenDsp" SG_ 913 signal10533 1;
BA_ "GenSigTimeoutMsg_ecu11765" SG_ 913 signal10546 913;
BA_ "signal131970" SG_ 913 signal10546 913;
BA_ "signal131977" SG_ 913 signal10546 913;
BA_ "NMH-WakeupAllowed" SG_ 913 signal10546 0;
BA_ "NWM-WakeupAllowed" SG_ 913 signal10546 0;
BA_ "GenSigStartValue" SG_ 913 signal10546 255;
BA_ "GenSigSendType" SG_ 913 signal10546 7;
BA_ "GenSigEnvVarType" SG_ 913 signal10546 1;
BA_ "GenSigAutoGenSnd" SG_ 913 signal10546 1;
BA_ "GenSigAutoGenDsp" SG_ 913 signal10546 1;
BA_ "GenSigTimeoutMsg_ecu11765" SG_ 913 signal10559 913;
BA_ "signal131970" SG_ 913 signal10559 913;
BA_ "signal131977" SG_ 913 signal10559 913;
BA_ "NMH-WakeupAllowed" SG_ 913 signal10559 0;
BA_ "NWM-WakeupAllowed" SG_ 913 signal10559 0;
BA_ "GenSigSendType" SG_ 913 signal10559 7;
BA_ "GenSigEnvVarType" SG_ 913 signal10559 0;
BA_ "GenSigAutoGenSnd" SG_ 913 signal10559 1;
BA_ "GenSigAutoGenDsp" SG_ 913 signal10559 1;
BA_ "GenSigTimeoutMsg_ecu11765" SG_ 913 signal10572 913;
BA_ "signal131970" SG_ 913 signal10572 913;
BA_ "signal131977" SG_ 913 signal10572 913;
BA_ "GenSigTimeoutMsg_ecu13186" SG_ 913 signal10572 913;
BA_ "NMH-WakeupAllowed" SG_ 913 signal10572 0;
BA_ "NWM-WakeupAllowed" SG_ 913 signal10572 0;
BA_ "GenSigSendType" SG_ 913 signal10572 7;
BA_ "GenSigEnvVarType" SG_ 913 signal10572 0;
BA_ "GenSigAutoGenSnd" SG_ 913 signal10572 1;
BA_ "GenSigAutoGenDsp" SG_ 913 signal10572 1;
BA_ "GenSigTimeoutMsg_ecu11765" SG_ 913 signal10586 913;
BA_ "signal131970" SG_ 913 signal10586 913;
BA_ "signal131977" SG_ 913 signal10586 913;
BA_ "NMH-WakeupAllowed" SG_ 913 signal10586 0;
BA_ "NWM-WakeupAllowed" SG_ 913 signal10586 0;
BA_ "GenSigSendType" SG_ 913 signal10586 7;
BA_ "GenSigEnvVarType" SG_ 913 signal10586 0;
BA_ "GenSigAutoGenSnd" SG_ 913 signal10586 1;
BA_ "GenSigAutoGenDsp" SG_ 913 signal10586 1;
BA_ "signal136198" SG_ 1630 signal10605 1630;
BA_ "signal133356" SG_ 1630 signal10605 1630;
BA_ "GenSigTimeoutMsg_ecu13120" SG_ 1630 signal10605 1630;
BA_ "NMH-WakeupAllowed" SG_ 1630 signal10605 0;
BA_ "NWM-WakeupAllowed" SG_ 1630 signal10605 0;
BA_ "GenSigSendType" SG_ 1630 signal10605 7;
BA_ "GenSigEnvVarType" SG_ 1630 signal10605 0;
BA_ "GenSigAutoGenSnd" SG_ 1630 signal10605 1;
BA_ "GenSigAutoGenDsp" SG_ 1630 signal10605 1;
BA_ "signal136198" SG_ 1630 signal10618 1630;
BA_ "signal133356" SG_ 1630 signal10618 1630;
BA_ "GenSigTimeoutMsg_ecu13120" SG_ 1630 signal10618 1630;
BA_ "NMH-WakeupAllowed" SG_ 1630 signal10618 0;
BA_ "NWM-WakeupAllowed" SG_ 1630 signal10618 0;
BA_ "GenSigSendType" SG_ 1630 signal10618 7;
BA_ "GenSigEnvVarType" SG_ 1630 signal10618 0;
BA_ "GenSigAutoGenSnd" SG_ 1630 signal10618 1;
BA_ "GenSigAutoGenDsp" SG_ 1630 signal10618 1;
BA_ "signal136198" SG_ 1630 signal10631 1630;
BA_ "signal133356" SG_ 1630 signal10631 1630;
BA_ "GenSigTimeoutMsg_ecu13120" SG_ 1630 signal10631 1630;
BA_ "NMH-WakeupAllowed" SG_ 1630 signal10631 0;
BA_ "NWM-WakeupAllowed" SG_ 1630 signal10631 0;
BA_ "GenSigSendType" SG_ 1630 signal10631 7;
BA_ "GenSigEnvVarType" SG_ 1630 signal10631 0;
BA_ "GenSigAutoGenSnd" SG_ 1630 signal10631 1;
BA_ "GenSigAutoGenDsp" SG_ 1630 signal10631 1;
BA_ "signal136198" SG_ 1630 signal10644 1630;
BA_ "signal133356" SG_ 1630 signal10644 1630;
BA_ "GenSigTimeoutMsg_ecu13120" SG_ 1630 signal10644 1630;
BA_ "NMH-WakeupAllowed" SG_ 1630 signal10644 0;
BA_ "NWM-WakeupAllowed" SG_ 1630 signal10644 0;
BA_ "GenSigSendType" SG_ 1630 signal10644 7;
BA_ "GenSigEnvVarType" SG_ 1630 signal10644 0;
BA_ "GenSigAutoGenSnd" SG_ 1630 signal10644 1;
BA_ "GenSigAutoGenDsp" SG_ 1630 signal10644 1;
BA_ "signal136198" SG_ 1630 signal10657 1630;
BA_ "signal133356" SG_ 1630 signal10657 1630;
BA_ "GenSigTimeoutMsg_ecu13120" SG_ 1630 signal10657 1630;
BA_ "NMH-WakeupAllowed" SG_ 1630 signal10657 0;
BA_ "NWM-WakeupAllowed" SG_ 1630 signal10657 0;
BA_ "GenSigSendType" SG_ 1630 signal10657 7;
BA_ "GenSigEnvVarType" SG_ 1630 signal10657 1;
BA_ "GenSigAutoGenSnd" SG_ 1630 signal10657 1;
BA_ "GenSigAutoGenDsp" SG_ 1630 signal10657 1;
BA_ "signal136198" SG_ 1630 signal10670 1630;
BA_ "signal133356" SG_ 1630 signal10670 1630;
BA_ "GenSigTimeoutMsg_ecu13120" SG_ 1630 signal10670 1630;
BA_ "NMH-WakeupAllowed" SG_ 1630 signal10670 0;
BA_ "NWM-WakeupAllowed" SG_ 1630 signal10670 0;
BA_ "GenSigSendType" SG_ 1630 signal10670 7;
BA_ "GenSigEnvVarType" SG_ 1630 signal10670 1;
BA_ "GenSigAutoGenSnd" SG_ 1630 signal10670 1;
BA_ "GenSigAutoGenDsp" SG_ 1630 signal10670 1;
BA_ "signal136198" SG_ 1630 signal10683 1630;
BA_ "signal133356" SG_ 1630 signal10683 1630;
BA_ "GenSigTimeoutMsg_ecu13120" SG_ 1630 signal10683 1630;
BA_ "NMH-WakeupAllowed" SG_ 1630 signal10683 0;
BA_ "NWM-WakeupAllowed" SG_ 1630 signal10683 0;
BA_ "GenSigSendType" SG_ 1630 signal10683 7;
BA_ "GenSigEnvVarType" SG_ 1630 signal10683 1;
BA_ "GenSigAutoGenSnd" SG_ 1630 signal10683 1;
BA_ "GenSigAutoGenDsp" SG_ 1630 signal10683 1;
BA_ "signal136198" SG_ 1630 signal10696 1630;
BA_ "signal133356" SG_ 1630 signal10696 1630;
BA_ "GenSigTimeoutMsg_ecu13120" SG_ 1630 signal10696 1630;
BA_ "NMH-WakeupAllowed" SG_ 1630 signal10696 0;
BA_ "NWM-WakeupAllowed" SG_ 1630 signal10696 0;
BA_ "GenSigSendType" SG_ 1630 signal10696 7;
BA_ "GenSigEnvVarType" SG_ 1630 signal10696 1;
BA_ "GenSigAutoGenSnd" SG_ 1630 signal10696 1;
BA_ "GenSigAutoGenDsp" SG_ 1630 signal10696 1;
BA_ "GenSigTimeoutMsg_ecu11765" SG_ 929 signal10715 929;
BA_ "signal131970" SG_ 929 signal10715 929;
BA_ "signal131977" SG_ 929 signal10715 929;
BA_ "NMH-WakeupAllowed" SG_ 929 signal10715 0;
BA_ "NWM-WakeupAllowed" SG_ 929 signal10715 0;
BA_ "GenSigSendType" SG_ 929 signal10715 7;
BA_ "GenSigEVName" SG_ 929 signal10715 "@signame";
BA_ "GenSigAutoGenSnd" SG_ 929 signal10715 1;
BA_ "GenSigAutoGenDsp" SG_ 929 signal10715 1;
BA_ "GenSigTimeoutMsg_ecu11765" SG_ 929 signal10728 929;
BA_ "signal131970" SG_ 929 signal10728 929;
BA_ "signal131977" SG_ 929 signal10728 929;
BA_ "NMH-WakeupAllowed" SG_ 929 signal10728 0;
BA_ "NWM-WakeupAllowed" SG_ 929 signal10728 0;
BA_ "GenSigSendType" SG_ 929 signal10728 7;
BA_ "GenSigEVName" SG_ 929 signal10728 "@signame";
BA_ "GenSigAutoGenSnd" SG_ 929 signal10728 1;
BA_ "GenSigAutoGenDsp" SG_ 929 signal10728 1;
BA_ "GenSigTimeoutMsg_ecu11765" SG_ 929 signal10741 929;
BA_ "signal131970" SG_ 929 signal10741 929;
BA_ "signal131977" SG_ 929 signal10741 929;
BA_ "NMH-WakeupAllowed" SG_ 929 signal10741 0;
BA_ "NWM-WakeupAllowed" SG_ 929 signal10741 0;
BA_ "GenSigSendType" SG_ 929 signal10741 7;
BA_ "GenSigEVName" SG_ 929 signal10741 "@signame";
BA_ "GenSigAutoGenSnd" SG_ 929 signal10741 1;
BA_ "GenSigAutoGenDsp" SG_ 929 signal10741 1;
BA_ "GenSigTimeoutMsg_ecu11765" SG_ 929 signal10754 929;
BA_ "signal131970" SG_ 929 signal10754 929;
BA_ "signal131977" SG_ 929 signal10754 929;
BA_ "NMH-WakeupAllowed" SG_ 929 signal10754 0;
BA_ "NWM-WakeupAllowed" SG_ 929 signal10754 0;
BA_ "GenSigSendType" SG_ 929 signal10754 7;
BA_ "GenSigEVName" SG_ 929 signal10754 "@signame";
BA_ "GenSigAutoGenSnd" SG_ 929 signal10754 1;
BA_ "GenSigAutoGenDsp" SG_ 929 signal10754 1;
BA_ "GenSigTimeoutMsg_ecu11765" SG_ 929 signal10767 929;
BA_ "signal131970" SG_ 929 signal10767 929;
BA_ "signal131977" SG_ 929 signal10767 929;
BA_ "NMH-WakeupAllowed" SG_ 929 signal10767 0;
BA_ "NWM-WakeupAllowed" SG_ 929 signal10767 0;
BA_ "GenSigSendType" SG_ 929 signal10767 7;
BA_ "GenSigEVName" SG_ 929 signal10767 "@signame";
BA_ "GenSigAutoGenSnd" SG_ 929 signal10767 1;
BA_ "GenSigAutoGenDsp" SG_ 929 signal10767 1;
BA_ "GenSigTimeoutMsg_ecu11765" SG_ 929 signal10780 929;
BA_ "signal131970" SG_ 929 signal10780 929;
BA_ "signal131977" SG_ 929 signal10780 929;
BA_ "NMH-WakeupAllowed" SG_ 929 signal10780 0;
BA_ "NWM-WakeupAllowed" SG_ 929 signal10780 0;
BA_ "GenSigSendType" SG_ 929 signal10780 7;
BA_ "GenSigEVName" SG_ 929 signal10780 "@signame";
BA_ "GenSigAutoGenSnd" SG_ 929 signal10780 1;
BA_ "GenSigAutoGenDsp" SG_ 929 signal10780 1;
BA_ "GenSigTimeoutMsg_ecu11765" SG_ 929 signal10793 929;
BA_ "signal131970" SG_ 929 signal10793 929;
BA_ "signal131977" SG_ 929 signal10793 929;
BA_ "NMH-WakeupAllowed" SG_ 929 signal10793 0;
BA_ "NWM-WakeupAllowed" SG_ 929 signal10793 0;
BA_ "GenSigSendType" SG_ 929 signal10793 7;
BA_ "GenSigEVName" SG_ 929 signal10793 "@signame";
BA_ "GenSigAutoGenSnd" SG_ 929 signal10793 1;
BA_ "GenSigAutoGenDsp" SG_ 929 signal10793 1;
BA_ "GenSigTimeoutMsg_ecu11765" SG_ 929 signal10806 929;
BA_ "signal131970" SG_ 929 signal10806 929;
BA_ "signal131977" SG_ 929 signal10806 929;
BA_ "NMH-WakeupAllowed" SG_ 929 signal10806 0;
BA_ "NWM-WakeupAllowed" SG_ 929 signal10806 0;
BA_ "GenSigSendType" SG_ 929 signal10806 7;
BA_ "GenSigEVName" SG_ 929 signal10806 "@signame";
BA_ "GenSigAutoGenSnd" SG_ 929 signal10806 1;
BA_ "GenSigAutoGenDsp" SG_ 929 signal10806 1;
BA_ "GenSigTimeoutMsg_ecu11765" SG_ 929 signal10819 929;
BA_ "signal131970" SG_ 929 signal10819 929;
BA_ "signal131977" SG_ 929 signal10819 929;
BA_ "NMH-WakeupAllowed" SG_ 929 signal10819 0;
BA_ "NWM-WakeupAllowed" SG_ 929 signal10819 0;
BA_ "GenSigSendType" SG_ 929 signal10819 7;
BA_ "GenSigEVName" SG_ 929 signal10819 "@signame";
BA_ "GenSigAutoGenSnd" SG_ 929 signal10819 1;
BA_ "GenSigAutoGenDsp" SG_ 929 signal10819 1;
BA_ "GenSigTimeoutMsg_ecu11765" SG_ 929 signal10832 929;
BA_ "signal131970" SG_ 929 signal10832 929;
BA_ "signal131977" SG_ 929 signal10832 929;
BA_ "NMH-WakeupAllowed" SG_ 929 signal10832 0;
BA_ "NWM-WakeupAllowed" SG_ 929 signal10832 0;
BA_ "GenSigSendType" SG_ 929 signal10832 7;
BA_ "GenSigEVName" SG_ 929 signal10832 "@signame";
BA_ "GenSigAutoGenSnd" SG_ 929 signal10832 1;
BA_ "GenSigAutoGenDsp" SG_ 929 signal10832 1;
BA_ "GenSigTimeoutMsg_ecu11765" SG_ 929 signal10845 929;
BA_ "signal131970" SG_ 929 signal10845 929;
BA_ "signal131977" SG_ 929 signal10845 929;
BA_ "NMH-WakeupAllowed" SG_ 929 signal10845 0;
BA_ "NWM-WakeupAllowed" SG_ 929 signal10845 0;
BA_ "GenSigSendType" SG_ 929 signal10845 7;
BA_ "GenSigEVName" SG_ 929 signal10845 "@signame";
BA_ "GenSigAutoGenSnd" SG_ 929 signal10845 1;
BA_ "GenSigAutoGenDsp" SG_ 929 signal10845 1;
BA_ "GenSigTimeoutMsg_ecu11765" SG_ 929 signal10858 929;
BA_ "signal131970" SG_ 929 signal10858 929;
BA_ "signal131977" SG_ 929 signal10858 929;
BA_ "NMH-WakeupAllowed" SG_ 929 signal10858 0;
BA_ "NWM-WakeupAllowed" SG_ 929 signal10858 0;
BA_ "GenSigSendType" SG_ 929 signal10858 7;
BA_ "GenSigEVName" SG_ 929 signal10858 "@signame";
BA_ "GenSigAutoGenSnd" SG_ 929 signal10858 1;
BA_ "GenSigAutoGenDsp" SG_ 929 signal10858 1;
BA_ "GenSigTimeoutMsg_ecu11765" SG_ 929 signal10871 929;
BA_ "signal131970" SG_ 929 signal10871 929;
BA_ "signal131977" SG_ 929 signal10871 929;
BA_ "NMH-WakeupAllowed" SG_ 929 signal10871 0;
BA_ "NWM-WakeupAllowed" SG_ 929 signal10871 0;
BA_ "GenSigSendType" SG_ 929 signal10871 7;
BA_ "GenSigEVName" SG_ 929 signal10871 "@signame";
BA_ "GenSigAutoGenSnd" SG_ 929 signal10871 1;
BA_ "GenSigAutoGenDsp" SG_ 929 signal10871 1;
BA_ "GenSigTimeoutMsg_ecu11765" SG_ 929 signal10884 929;
BA_ "signal131970" SG_ 929 signal10884 929;
BA_ "signal131977" SG_ 929 signal10884 929;
BA_ "NMH-WakeupAllowed" SG_ 929 signal10884 0;
BA_ "NWM-WakeupAllowed" SG_ 929 signal10884 0;
BA_ "GenSigSendType" SG_ 929 signal10884 7;
BA_ "GenSigEVName" SG_ 929 signal10884 "@signame";
BA_ "GenSigAutoGenSnd" SG_ 929 signal10884 1;
BA_ "GenSigAutoGenDsp" SG_ 929 signal10884 1;
BA_ "GenSigTimeoutMsg_ecu11765" SG_ 929 signal10897 929;
BA_ "signal131970" SG_ 929 signal10897 929;
BA_ "signal131977" SG_ 929 signal10897 929;
BA_ "NMH-WakeupAllowed" SG_ 929 signal10897 0;
BA_ "NWM-WakeupAllowed" SG_ 929 signal10897 0;
BA_ "GenSigSendType" SG_ 929 signal10897 7;
BA_ "GenSigEVName" SG_ 929 signal10897 "@signame";
BA_ "GenSigAutoGenSnd" SG_ 929 signal10897 1;
BA_ "GenSigAutoGenDsp" SG_ 929 signal10897 1;
BA_ "GenSigTimeoutMsg_ecu11765" SG_ 929 signal10910 929;
BA_ "signal131970" SG_ 929 signal10910 929;
BA_ "signal131977" SG_ 929 signal10910 929;
BA_ "NMH-WakeupAllowed" SG_ 929 signal10910 0;
BA_ "NWM-WakeupAllowed" SG_ 929 signal10910 0;
BA_ "GenSigStartValue" SG_ 929 signal10910 1;
BA_ "GenSigSendType" SG_ 929 signal10910 7;
BA_ "GenSigEVName" SG_ 929 signal10910 "@signame";
BA_ "GenSigAutoGenSnd" SG_ 929 signal10910 1;
BA_ "GenSigAutoGenDsp" SG_ 929 signal10910 1;
BA_ "GenSigTimeoutMsg_ecu11765" SG_ 929 signal10923 929;
BA_ "signal131970" SG_ 929 signal10923 929;
BA_ "signal131977" SG_ 929 signal10923 929;
BA_ "NMH-WakeupAllowed" SG_ 929 signal10923 0;
BA_ "NWM-WakeupAllowed" SG_ 929 signal10923 0;
BA_ "GenSigSendType" SG_ 929 signal10923 7;
BA_ "GenSigEVName" SG_ 929 signal10923 "@signame";
BA_ "GenSigAutoGenSnd" SG_ 929 signal10923 1;
BA_ "GenSigAutoGenDsp" SG_ 929 signal10923 1;
BA_ "GenSigTimeoutMsg_ecu11765" SG_ 930 signal10942 930;
BA_ "signal131970" SG_ 930 signal10942 930;
BA_ "signal131977" SG_ 930 signal10942 930;
BA_ "NMH-WakeupAllowed" SG_ 930 signal10942 0;
BA_ "NWM-WakeupAllowed" SG_ 930 signal10942 0;
BA_ "GenSigSendType" SG_ 930 signal10942 7;
BA_ "GenSigEVName" SG_ 930 signal10942 "@signame";
BA_ "GenSigAutoGenSnd" SG_ 930 signal10942 1;
BA_ "GenSigAutoGenDsp" SG_ 930 signal10942 1;
BA_ "GenSigTimeoutMsg_ecu11765" SG_ 930 signal10956 930;
BA_ "signal131970" SG_ 930 signal10956 930;
BA_ "signal131977" SG_ 930 signal10956 930;
BA_ "NMH-WakeupAllowed" SG_ 930 signal10956 0;
BA_ "NWM-WakeupAllowed" SG_ 930 signal10956 0;
BA_ "GenSigSendType" SG_ 930 signal10956 7;
BA_ "GenSigEVName" SG_ 930 signal10956 "@signame";
BA_ "GenSigAutoGenSnd" SG_ 930 signal10956 1;
BA_ "GenSigAutoGenDsp" SG_ 930 signal10956 1;
BA_ "GenSigTimeoutMsg_ecu11765" SG_ 930 signal10970 930;
BA_ "signal131970" SG_ 930 signal10970 930;
BA_ "signal131977" SG_ 930 signal10970 930;
BA_ "NMH-WakeupAllowed" SG_ 930 signal10970 0;
BA_ "NWM-WakeupAllowed" SG_ 930 signal10970 0;
BA_ "GenSigSendType" SG_ 930 signal10970 7;
BA_ "GenSigEVName" SG_ 930 signal10970 "@signame";
BA_ "GenSigAutoGenSnd" SG_ 930 signal10970 1;
BA_ "GenSigAutoGenDsp" SG_ 930 signal10970 1;
BA_ "GenSigTimeoutMsg_ecu11765" SG_ 930 signal10984 930;
BA_ "signal131970" SG_ 930 signal10984 930;
BA_ "signal131977" SG_ 930 signal10984 930;
BA_ "NMH-WakeupAllowed" SG_ 930 signal10984 0;
BA_ "NWM-WakeupAllowed" SG_ 930 signal10984 0;
BA_ "GenSigSendType" SG_ 930 signal10984 7;
BA_ "GenSigEVName" SG_ 930 signal10984 "@signame";
BA_ "GenSigAutoGenSnd" SG_ 930 signal10984 1;
BA_ "GenSigAutoGenDsp" SG_ 930 signal10984 1;
BA_ "GenSigTimeoutMsg_ecu11765" SG_ 930 signal10998 930;
BA_ "signal131970" SG_ 930 signal10998 930;
BA_ "signal131977" SG_ 930 signal10998 930;
BA_ "NMH-WakeupAllowed" SG_ 930 signal10998 0;
BA_ "NWM-WakeupAllowed" SG_ 930 signal10998 0;
BA_ "GenSigSendType" SG_ 930 signal10998 7;
BA_ "GenSigEVName" SG_ 930 signal10998 "@signame";
BA_ "GenSigAutoGenSnd" SG_ 930 signal10998 1;
BA_ "GenSigAutoGenDsp" SG_ 930 signal10998 1;
BA_ "GenSigTimeoutMsg_ecu11765" SG_ 930 signal11012 930;
BA_ "signal131970" SG_ 930 signal11012 930;
BA_ "signal131977" SG_ 930 signal11012 930;
BA_ "NMH-WakeupAllowed" SG_ 930 signal11012 0;
BA_ "NWM-WakeupAllowed" SG_ 930 signal11012 0;
BA_ "GenSigSendType" SG_ 930 signal11012 7;
BA_ "GenSigEVName" SG_ 930 signal11012 "@signame";
BA_ "GenSigAutoGenSnd" SG_ 930 signal11012 1;
BA_ "GenSigAutoGenDsp" SG_ 930 signal11012 1;
BA_ "GenSigTimeoutMsg_ecu11765" SG_ 930 signal11026 930;
BA_ "signal131970" SG_ 930 signal11026 930;
BA_ "signal131977" SG_ 930 signal11026 930;
BA_ "NMH-WakeupAllowed" SG_ 930 signal11026 0;
BA_ "NWM-WakeupAllowed" SG_ 930 signal11026 0;
BA_ "GenSigSendType" SG_ 930 signal11026 7;
BA_ "GenSigEVName" SG_ 930 signal11026 "@signame";
BA_ "GenSigAutoGenSnd" SG_ 930 signal11026 1;
BA_ "GenSigAutoGenDsp" SG_ 930 signal11026 1;
BA_ "GenSigTimeoutMsg_ecu11765" SG_ 930 signal11040 930;
BA_ "signal131970" SG_ 930 signal11040 930;
BA_ "signal131977" SG_ 930 signal11040 930;
BA_ "NMH-WakeupAllowed" SG_ 930 signal11040 0;
BA_ "NWM-WakeupAllowed" SG_ 930 signal11040 0;
BA_ "GenSigSendType" SG_ 930 signal11040 7;
BA_ "GenSigEVName" SG_ 930 signal11040 "@signame";
BA_ "GenSigAutoGenSnd" SG_ 930 signal11040 1;
BA_ "GenSigAutoGenDsp" SG_ 930 signal11040 1;
BA_ "GenSigTimeoutMsg_ecu11765" SG_ 930 signal11054 930;
BA_ "signal131970" SG_ 930 signal11054 930;
BA_ "signal131977" SG_ 930 signal11054 930;
BA_ "NMH-WakeupAllowed" SG_ 930 signal11054 0;
BA_ "NWM-WakeupAllowed" SG_ 930 signal11054 0;
BA_ "GenSigSendType" SG_ 930 signal11054 7;
BA_ "GenSigEVName" SG_ 930 signal11054 "@signame";
BA_ "GenSigAutoGenSnd" SG_ 930 signal11054 1;
BA_ "GenSigAutoGenDsp" SG_ 930 signal11054 1;
BA_ "GenSigTimeoutMsg_ecu11765" SG_ 930 signal11068 930;
BA_ "signal131970" SG_ 930 signal11068 930;
BA_ "signal131977" SG_ 930 signal11068 930;
BA_ "NMH-WakeupAllowed" SG_ 930 signal11068 0;
BA_ "NWM-WakeupAllowed" SG_ 930 signal11068 0;
BA_ "GenSigSendType" SG_ 930 signal11068 7;
BA_ "GenSigEVName" SG_ 930 signal11068 "@signame";
BA_ "GenSigAutoGenSnd" SG_ 930 signal11068 1;
BA_ "GenSigAutoGenDsp" SG_ 930 signal11068 1;
BA_ "GenSigTimeoutMsg_ecu11765" SG_ 930 signal11110 930;
BA_ "signal131970" SG_ 930 signal11110 930;
BA_ "signal131977" SG_ 930 signal11110 930;
BA_ "NMH-WakeupAllowed" SG_ 930 signal11110 0;
BA_ "NWM-WakeupAllowed" SG_ 930 signal11110 0;
BA_ "GenSigSendType" SG_ 930 signal11110 7;
BA_ "GenSigEVName" SG_ 930 signal11110 "@signame";
BA_ "GenSigAutoGenSnd" SG_ 930 signal11110 1;
BA_ "GenSigAutoGenDsp" SG_ 930 signal11110 1;
BA_ "GenSigTimeoutMsg_ecu11765" SG_ 930 signal11138 930;
BA_ "signal131970" SG_ 930 signal11138 930;
BA_ "signal131977" SG_ 930 signal11138 930;
BA_ "NMH-WakeupAllowed" SG_ 930 signal11138 0;
BA_ "NWM-WakeupAllowed" SG_ 930 signal11138 0;
BA_ "GenSigSendType" SG_ 930 signal11138 7;
BA_ "GenSigEVName" SG_ 930 signal11138 "@signame";
BA_ "GenSigAutoGenSnd" SG_ 930 signal11138 1;
BA_ "GenSigAutoGenDsp" SG_ 930 signal11138 1;
BA_ "GenSigTimeoutMsg_ecu11765" SG_ 930 signal11152 930;
BA_ "signal131970" SG_ 930 signal11152 930;
BA_ "signal131977" SG_ 930 signal11152 930;
BA_ "NMH-WakeupAllowed" SG_ 930 signal11152 0;
BA_ "NWM-WakeupAllowed" SG_ 930 signal11152 0;
BA_ "GenSigSendType" SG_ 930 signal11152 7;
BA_ "GenSigEVName" SG_ 930 signal11152 "@signame";
BA_ "GenSigAutoGenSnd" SG_ 930 signal11152 1;
BA_ "GenSigAutoGenDsp" SG_ 930 signal11152 1;
BA_ "GenSigTimeoutMsg_ecu11765" SG_ 930 signal11180 930;
BA_ "signal131970" SG_ 930 signal11180 930;
BA_ "signal131977" SG_ 930 signal11180 930;
BA_ "NMH-WakeupAllowed" SG_ 930 signal11180 0;
BA_ "NWM-WakeupAllowed" SG_ 930 signal11180 0;
BA_ "GenSigSendType" SG_ 930 signal11180 7;
BA_ "GenSigEVName" SG_ 930 signal11180 "@signame";
BA_ "GenSigAutoGenSnd" SG_ 930 signal11180 1;
BA_ "GenSigAutoGenDsp" SG_ 930 signal11180 1;
BA_ "GenSigTimeoutMsg_ecu11765" SG_ 930 signal11208 930;
BA_ "signal131970" SG_ 930 signal11208 930;
BA_ "signal131977" SG_ 930 signal11208 930;
BA_ "NMH-WakeupAllowed" SG_ 930 signal11208 0;
BA_ "NWM-WakeupAllowed" SG_ 930 signal11208 0;
BA_ "GenSigSendType" SG_ 930 signal11208 7;
BA_ "GenSigEVName" SG_ 930 signal11208 "@signame";
BA_ "GenSigAutoGenSnd" SG_ 930 signal11208 1;
BA_ "GenSigAutoGenDsp" SG_ 930 signal11208 1;
BA_ "GenSigTimeoutMsg_ecu11765" SG_ 930 signal11222 930;
BA_ "signal131970" SG_ 930 signal11222 930;
BA_ "signal131977" SG_ 930 signal11222 930;
BA_ "NMH-WakeupAllowed" SG_ 930 signal11222 0;
BA_ "NWM-WakeupAllowed" SG_ 930 signal11222 0;
BA_ "GenSigSendType" SG_ 930 signal11222 7;
BA_ "GenSigEVName" SG_ 930 signal11222 "@signame";
BA_ "GenSigAutoGenSnd" SG_ 930 signal11222 1;
BA_ "GenSigAutoGenDsp" SG_ 930 signal11222 1;
BA_ "GenSigTimeoutMsg_ecu11765" SG_ 930 signal11236 930;
BA_ "signal131970" SG_ 930 signal11236 930;
BA_ "signal131977" SG_ 930 signal11236 930;
BA_ "NMH-WakeupAllowed" SG_ 930 signal11236 0;
BA_ "NWM-WakeupAllowed" SG_ 930 signal11236 0;
BA_ "GenSigSendType" SG_ 930 signal11236 7;
BA_ "GenSigEVName" SG_ 930 signal11236 "@signame";
BA_ "GenSigAutoGenSnd" SG_ 930 signal11236 1;
BA_ "GenSigAutoGenDsp" SG_ 930 signal11236 1;
BA_ "GenSigTimeoutMsg_ecu11765" SG_ 930 signal11250 930;
BA_ "signal131970" SG_ 930 signal11250 930;
BA_ "signal131977" SG_ 930 signal11250 930;
BA_ "NMH-WakeupAllowed" SG_ 930 signal11250 0;
BA_ "NWM-WakeupAllowed" SG_ 930 signal11250 0;
BA_ "GenSigSendType" SG_ 930 signal11250 7;
BA_ "GenSigEVName" SG_ 930 signal11250 "@signame";
BA_ "GenSigAutoGenSnd" SG_ 930 signal11250 1;
BA_ "GenSigAutoGenDsp" SG_ 930 signal11250 1;
BA_ "GenSigTimeoutMsg_ecu11765" SG_ 930 signal11278 930;
BA_ "signal131970" SG_ 930 signal11278 930;
BA_ "signal131977" SG_ 930 signal11278 930;
BA_ "NMH-WakeupAllowed" SG_ 930 signal11278 0;
BA_ "NWM-WakeupAllowed" SG_ 930 signal11278 0;
BA_ "GenSigSendType" SG_ 930 signal11278 7;
BA_ "GenSigEVName" SG_ 930 signal11278 "@signame";
BA_ "GenSigAutoGenSnd" SG_ 930 signal11278 1;
BA_ "GenSigAutoGenDsp" SG_ 930 signal11278 1;
BA_ "GenSigTimeoutMsg_ecu11765" SG_ 930 signal11292 930;
BA_ "signal131970" SG_ 930 signal11292 930;
BA_ "signal131977" SG_ 930 signal11292 930;
BA_ "NMH-WakeupAllowed" SG_ 930 signal11292 0;
BA_ "NWM-WakeupAllowed" SG_ 930 signal11292 0;
BA_ "GenSigSendType" SG_ 930 signal11292 7;
BA_ "GenSigEVName" SG_ 930 signal11292 "@signame";
BA_ "GenSigAutoGenSnd" SG_ 930 signal11292 1;
BA_ "GenSigAutoGenDsp" SG_ 930 signal11292 1;
BA_ "GenSigTimeoutMsg_ecu11765" SG_ 930 signal11306 930;
BA_ "signal131970" SG_ 930 signal11306 930;
BA_ "signal131977" SG_ 930 signal11306 930;
BA_ "NMH-WakeupAllowed" SG_ 930 signal11306 0;
BA_ "NWM-WakeupAllowed" SG_ 930 signal11306 0;
BA_ "GenSigSendType" SG_ 930 signal11306 7;
BA_ "GenSigEVName" SG_ 930 signal11306 "@signame";
BA_ "GenSigAutoGenSnd" SG_ 930 signal11306 1;
BA_ "GenSigAutoGenDsp" SG_ 930 signal11306 1;
BA_ "GenSigTimeoutMsg_ecu11765" SG_ 930 signal11320 930;
BA_ "signal131970" SG_ 930 signal11320 930;
BA_ "signal131977" SG_ 930 signal11320 930;
BA_ "NMH-WakeupAllowed" SG_ 930 signal11320 0;
BA_ "NWM-WakeupAllowed" SG_ 930 signal11320 0;
BA_ "GenSigSendType" SG_ 930 signal11320 7;
BA_ "GenSigEVName" SG_ 930 signal11320 "@signame";
BA_ "GenSigAutoGenSnd" SG_ 930 signal11320 1;
BA_ "GenSigAutoGenDsp" SG_ 930 signal11320 1;
BA_ "GenSigTimeoutMsg_ecu11765" SG_ 930 signal11278_Typ 930;
BA_ "signal131970" SG_ 930 signal11278_Typ 930;
BA_ "signal131977" SG_ 930 signal11278_Typ 930;
BA_ "NMH-WakeupAllowed" SG_ 930 signal11278_Typ 0;
BA_ "NWM-WakeupAllowed" SG_ 930 signal11278_Typ 0;
BA_ "GenSigSendType" SG_ 930 signal11278_Typ 7;
BA_ "GenSigEVName" SG_ 930 signal11278_Typ "@signame";
BA_ "GenSigAutoGenSnd" SG_ 930 signal11278_Typ 1;
BA_ "GenSigAutoGenDsp" SG_ 930 signal11278_Typ 1;
BA_ "GenSigTimeoutMsg_ecu11765" SG_ 930 signal11362 930;
BA_ "signal131970" SG_ 930 signal11362 930;
BA_ "signal131977" SG_ 930 signal11362 930;
BA_ "NMH-WakeupAllowed" SG_ 930 signal11362 0;
BA_ "NWM-WakeupAllowed" SG_ 930 signal11362 0;
BA_ "GenSigSendType" SG_ 930 signal11362 7;
BA_ "GenSigEVName" SG_ 930 signal11362 "@signame";
BA_ "GenSigAutoGenSnd" SG_ 930 signal11362 1;
BA_ "GenSigAutoGenDsp" SG_ 930 signal11362 1;
BA_ "GenSigTimeoutMsg_ecu11765" SG_ 930 signal11376 930;
BA_ "signal131970" SG_ 930 signal11376 930;
BA_ "signal131977" SG_ 930 signal11376 930;
BA_ "NMH-WakeupAllowed" SG_ 930 signal11376 0;
BA_ "NWM-WakeupAllowed" SG_ 930 signal11376 0;
BA_ "GenSigSendType" SG_ 930 signal11376 7;
BA_ "GenSigEVName" SG_ 930 signal11376 "@signame";
BA_ "GenSigAutoGenSnd" SG_ 930 signal11376 1;
BA_ "GenSigAutoGenDsp" SG_ 930 signal11376 1;
BA_ "GenSigTimeoutMsg_ecu11765" SG_ 930 signal11390 930;
BA_ "signal131970" SG_ 930 signal11390 930;
BA_ "signal131977" SG_ 930 signal11390 930;
BA_ "NMH-WakeupAllowed" SG_ 930 signal11390 0;
BA_ "NWM-WakeupAllowed" SG_ 930 signal11390 0;
BA_ "GenSigSendType" SG_ 930 signal11390 7;
BA_ "GenSigEVName" SG_ 930 signal11390 "@signame";
BA_ "GenSigAutoGenSnd" SG_ 930 signal11390 1;
BA_ "GenSigAutoGenDsp" SG_ 930 signal11390 1;
BA_ "GenSigTimeoutMsg_ecu11765" SG_ 930 signal11404 930;
BA_ "signal131970" SG_ 930 signal11404 930;
BA_ "signal131977" SG_ 930 signal11404 930;
BA_ "NMH-WakeupAllowed" SG_ 930 signal11404 0;
BA_ "NWM-WakeupAllowed" SG_ 930 signal11404 0;
BA_ "GenSigSendType" SG_ 930 signal11404 7;
BA_ "GenSigEVName" SG_ 930 signal11404 "@signame";
BA_ "GenSigAutoGenSnd" SG_ 930 signal11404 1;
BA_ "GenSigAutoGenDsp" SG_ 930 signal11404 1;
BA_ "GenSigTimeoutMsg_ecu11765" SG_ 930 signal11418 930;
BA_ "signal131970" SG_ 930 signal11418 930;
BA_ "signal131977" SG_ 930 signal11418 930;
BA_ "NMH-WakeupAllowed" SG_ 930 signal11418 0;
BA_ "NWM-WakeupAllowed" SG_ 930 signal11418 0;
BA_ "GenSigSendType" SG_ 930 signal11418 7;
BA_ "GenSigEVName" SG_ 930 signal11418 "@signame";
BA_ "GenSigAutoGenSnd" SG_ 930 signal11418 1;
BA_ "GenSigAutoGenDsp" SG_ 930 signal11418 1;
BA_ "GenSigTimeoutMsg_ecu11765" SG_ 930 signal11432 930;
BA_ "signal131970" SG_ 930 signal11432 930;
BA_ "signal131977" SG_ 930 signal11432 930;
BA_ "NMH-WakeupAllowed" SG_ 930 signal11432 0;
BA_ "NWM-WakeupAllowed" SG_ 930 signal11432 0;
BA_ "GenSigSendType" SG_ 930 signal11432 7;
BA_ "GenSigEVName" SG_ 930 signal11432 "@signame";
BA_ "GenSigAutoGenSnd" SG_ 930 signal11432 1;
BA_ "GenSigAutoGenDsp" SG_ 930 signal11432 1;
BA_ "GenSigTimeoutMsg_ecu11765" SG_ 930 signal11446 930;
BA_ "signal131970" SG_ 930 signal11446 930;
BA_ "signal131977" SG_ 930 signal11446 930;
BA_ "NMH-WakeupAllowed" SG_ 930 signal11446 0;
BA_ "NWM-WakeupAllowed" SG_ 930 signal11446 0;
BA_ "GenSigSendType" SG_ 930 signal11446 7;
BA_ "GenSigEVName" SG_ 930 signal11446 "@signame";
BA_ "GenSigAutoGenSnd" SG_ 930 signal11446 1;
BA_ "GenSigAutoGenDsp" SG_ 930 signal11446 1;
BA_ "GenSigTimeoutMsg_ecu11765" SG_ 930 signal11460 930;
BA_ "signal131970" SG_ 930 signal11460 930;
BA_ "signal131977" SG_ 930 signal11460 930;
BA_ "NMH-WakeupAllowed" SG_ 930 signal11460 0;
BA_ "NWM-WakeupAllowed" SG_ 930 signal11460 0;
BA_ "GenSigSendType" SG_ 930 signal11460 7;
BA_ "GenSigEVName" SG_ 930 signal11460 "@signame";
BA_ "GenSigAutoGenSnd" SG_ 930 signal11460 1;
BA_ "GenSigAutoGenDsp" SG_ 930 signal11460 1;
BA_ "GenSigTimeoutMsg_ecu11765" SG_ 930 signal11516 930;
BA_ "signal131970" SG_ 930 signal11516 930;
BA_ "signal131977" SG_ 930 signal11516 930;
BA_ "NMH-WakeupAllowed" SG_ 930 signal11516 0;
BA_ "NWM-WakeupAllowed" SG_ 930 signal11516 0;
BA_ "GenSigSendType" SG_ 930 signal11516 7;
BA_ "GenSigEVName" SG_ 930 signal11516 "@signame";
BA_ "GenSigAutoGenSnd" SG_ 930 signal11516 1;
BA_ "GenSigAutoGenDsp" SG_ 930 signal11516 1;
BA_ "GenSigTimeoutMsg_ecu11765" SG_ 930 signal11530 930;
BA_ "signal131970" SG_ 930 signal11530 930;
BA_ "signal131977" SG_ 930 signal11530 930;
BA_ "NMH-WakeupAllowed" SG_ 930 signal11530 0;
BA_ "NWM-WakeupAllowed" SG_ 930 signal11530 0;
BA_ "GenSigSendType" SG_ 930 signal11530 7;
BA_ "GenSigEVName" SG_ 930 signal11530 "@signame";
BA_ "GenSigAutoGenSnd" SG_ 930 signal11530 1;
BA_ "GenSigAutoGenDsp" SG_ 930 signal11530 1;
BA_ "GenSigTimeoutMsg_ecu11765" SG_ 930 signal11544 930;
BA_ "signal131970" SG_ 930 signal11544 930;
BA_ "signal131977" SG_ 930 signal11544 930;
BA_ "NMH-WakeupAllowed" SG_ 930 signal11544 0;
BA_ "NWM-WakeupAllowed" SG_ 930 signal11544 0;
BA_ "GenSigSendType" SG_ 930 signal11544 7;
BA_ "GenSigEVName" SG_ 930 signal11544 "@signame";
BA_ "GenSigAutoGenSnd" SG_ 930 signal11544 1;
BA_ "GenSigAutoGenDsp" SG_ 930 signal11544 1;
BA_ "GenSigTimeoutMsg_ecu11765" SG_ 930 signal11586 930;
BA_ "signal131970" SG_ 930 signal11586 930;
BA_ "signal131977" SG_ 930 signal11586 930;
BA_ "NMH-WakeupAllowed" SG_ 930 signal11586 0;
BA_ "NWM-WakeupAllowed" SG_ 930 signal11586 0;
BA_ "GenSigSendType" SG_ 930 signal11586 7;
BA_ "GenSigEVName" SG_ 930 signal11586 "@signame";
BA_ "GenSigAutoGenSnd" SG_ 930 signal11586 1;
BA_ "GenSigAutoGenDsp" SG_ 930 signal11586 1;
BA_ "GenSigTimeoutMsg_ecu11765" SG_ 930 signal11544_Vorz 930;
BA_ "signal131970" SG_ 930 signal11544_Vorz 930;
BA_ "signal131977" SG_ 930 signal11544_Vorz 930;
BA_ "NMH-WakeupAllowed" SG_ 930 signal11544_Vorz 0;
BA_ "NWM-WakeupAllowed" SG_ 930 signal11544_Vorz 0;
BA_ "GenSigSendType" SG_ 930 signal11544_Vorz 7;
BA_ "GenSigEVName" SG_ 930 signal11544_Vorz "@signame";
BA_ "GenSigAutoGenSnd" SG_ 930 signal11544_Vorz 1;
BA_ "GenSigAutoGenDsp" SG_ 930 signal11544_Vorz 1;
BA_ "GenSigTimeoutMsg_ecu11765" SG_ 930 signal11614 930;
BA_ "signal131970" SG_ 930 signal11614 930;
BA_ "signal131977" SG_ 930 signal11614 930;
BA_ "NMH-WakeupAllowed" SG_ 930 signal11614 0;
BA_ "NWM-WakeupAllowed" SG_ 930 signal11614 0;
BA_ "GenSigSendType" SG_ 930 signal11614 7;
BA_ "GenSigEVName" SG_ 930 signal11614 "@signame";
BA_ "GenSigAutoGenSnd" SG_ 930 signal11614 1;
BA_ "GenSigAutoGenDsp" SG_ 930 signal11614 1;
BA_ "GenSigTimeoutMsg_ecu11765" SG_ 930 signal11628 930;
BA_ "signal131970" SG_ 930 signal11628 930;
BA_ "signal131977" SG_ 930 signal11628 930;
BA_ "NMH-WakeupAllowed" SG_ 930 signal11628 0;
BA_ "NWM-WakeupAllowed" SG_ 930 signal11628 0;
BA_ "GenSigSendType" SG_ 930 signal11628 7;
BA_ "GenSigEVName" SG_ 930 signal11628 "@signame";
BA_ "GenSigAutoGenSnd" SG_ 930 signal11628 1;
BA_ "GenSigAutoGenDsp" SG_ 930 signal11628 1;
BA_ "GenSigTimeoutMsg_ecu11765" SG_ 930 signal11642 930;
BA_ "signal131970" SG_ 930 signal11642 930;
BA_ "signal131977" SG_ 930 signal11642 930;
BA_ "NMH-WakeupAllowed" SG_ 930 signal11642 0;
BA_ "NWM-WakeupAllowed" SG_ 930 signal11642 0;
BA_ "GenSigSendType" SG_ 930 signal11642 7;
BA_ "GenSigEVName" SG_ 930 signal11642 "@signame";
BA_ "GenSigAutoGenSnd" SG_ 930 signal11642 1;
BA_ "GenSigAutoGenDsp" SG_ 930 signal11642 1;
BA_ "GenSigTimeoutMsg_ecu11765" SG_ 930 signal11656 930;
BA_ "signal131970" SG_ 930 signal11656 930;
BA_ "signal131977" SG_ 930 signal11656 930;
BA_ "NMH-WakeupAllowed" SG_ 930 signal11656 0;
BA_ "NWM-WakeupAllowed" SG_ 930 signal11656 0;
BA_ "GenSigSendType" SG_ 930 signal11656 7;
BA_ "GenSigEVName" SG_ 930 signal11656 "@signame";
BA_ "GenSigAutoGenSnd" SG_ 930 signal11656 1;
BA_ "GenSigAutoGenDsp" SG_ 930 signal11656 1;
BA_ "GenSigTimeoutMsg_ecu11765" SG_ 930 signal11614_Vorz 930;
BA_ "signal131970" SG_ 930 signal11614_Vorz 930;
BA_ "signal131977" SG_ 930 signal11614_Vorz 930;
BA_ "NMH-WakeupAllowed" SG_ 930 signal11614_Vorz 0;
BA_ "NWM-WakeupAllowed" SG_ 930 signal11614_Vorz 0;
BA_ "GenSigSendType" SG_ 930 signal11614_Vorz 7;
BA_ "GenSigEVName" SG_ 930 signal11614_Vorz "@signame";
BA_ "GenSigAutoGenSnd" SG_ 930 signal11614_Vorz 1;
BA_ "GenSigAutoGenDsp" SG_ 930 signal11614_Vorz 1;
BA_ "GenSigTimeoutMsg_ecu11765" SG_ 930 signal11684 930;
BA_ "signal131970" SG_ 930 signal11684 930;
BA_ "signal131977" SG_ 930 signal11684 930;
BA_ "NMH-WakeupAllowed" SG_ 930 signal11684 0;
BA_ "NWM-WakeupAllowed" SG_ 930 signal11684 0;
BA_ "GenSigSendType" SG_ 930 signal11684 7;
BA_ "GenSigEVName" SG_ 930 signal11684 "@signame";
BA_ "GenSigAutoGenSnd" SG_ 930 signal11684 1;
BA_ "GenSigAutoGenDsp" SG_ 930 signal11684 1;
BA_ "GenSigTimeoutMsg_ecu11765" SG_ 930 signal11698 930;
BA_ "signal131970" SG_ 930 signal11698 930;
BA_ "signal131977" SG_ 930 signal11698 930;
BA_ "NMH-WakeupAllowed" SG_ 930 signal11698 0;
BA_ "NWM-WakeupAllowed" SG_ 930 signal11698 0;
BA_ "GenSigSendType" SG_ 930 signal11698 7;
BA_ "GenSigEVName" SG_ 930 signal11698 "@signame";
BA_ "GenSigAutoGenSnd" SG_ 930 signal11698 1;
BA_ "GenSigAutoGenDsp" SG_ 930 signal11698 1;
BA_ "GenSigTimeoutMsg_ecu11765" SG_ 930 signal11712 930;
BA_ "signal131970" SG_ 930 signal11712 930;
BA_ "signal131977" SG_ 930 signal11712 930;
BA_ "NMH-WakeupAllowed" SG_ 930 signal11712 0;
BA_ "NWM-WakeupAllowed" SG_ 930 signal11712 0;
BA_ "GenSigStartValue" SG_ 930 signal11712 1;
BA_ "GenSigSendType" SG_ 930 signal11712 7;
BA_ "GenSigEVName" SG_ 930 signal11712 "@signame";
BA_ "GenSigAutoGenSnd" SG_ 930 signal11712 1;
BA_ "GenSigAutoGenDsp" SG_ 930 signal11712 1;
BA_ "GenSigTimeoutMsg_ecu11765" SG_ 930 signal11726 930;
BA_ "signal131970" SG_ 930 signal11726 930;
BA_ "signal131977" SG_ 930 signal11726 930;
BA_ "NMH-WakeupAllowed" SG_ 930 signal11726 0;
BA_ "NWM-WakeupAllowed" SG_ 930 signal11726 0;
BA_ "GenSigSendType" SG_ 930 signal11726 7;
BA_ "GenSigEVName" SG_ 930 signal11726 "@signame";
BA_ "GenSigAutoGenSnd" SG_ 930 signal11726 1;
BA_ "GenSigAutoGenDsp" SG_ 930 signal11726 1;
BA_ "GenSigTimeoutMsg_ecu11765" SG_ 930 signal11740 930;
BA_ "signal131970" SG_ 930 signal11740 930;
BA_ "signal131977" SG_ 930 signal11740 930;
BA_ "NMH-WakeupAllowed" SG_ 930 signal11740 0;
BA_ "NWM-WakeupAllowed" SG_ 930 signal11740 0;
BA_ "GenSigSendType" SG_ 930 signal11740 7;
BA_ "GenSigEVName" SG_ 930 signal11740 "@signame";
BA_ "GenSigAutoGenSnd" SG_ 930 signal11740 1;
BA_ "GenSigAutoGenDsp" SG_ 930 signal11740 1;
BA_ "GenSigTimeoutMsg_ecu11765" SG_ 930 signal11754 930;
BA_ "signal131970" SG_ 930 signal11754 930;
BA_ "signal131977" SG_ 930 signal11754 930;
BA_ "NMH-WakeupAllowed" SG_ 930 signal11754 0;
BA_ "NWM-WakeupAllowed" SG_ 930 signal11754 0;
BA_ "GenSigSendType" SG_ 930 signal11754 7;
BA_ "GenSigEVName" SG_ 930 signal11754 "@signame";
BA_ "GenSigAutoGenSnd" SG_ 930 signal11754 1;
BA_ "GenSigAutoGenDsp" SG_ 930 signal11754 1;
BA_ "signal142834" SG_ 2033 signal11769 2033;
BA_ "NMH-WakeupAllowed" SG_ 2033 signal11769 0;
BA_ "NWM-WakeupAllowed" SG_ 2033 signal11769 0;
BA_ "GenSigSendType" SG_ 2033 signal11769 7;
BA_ "GenSigEnvVarType" SG_ 2033 signal11769 0;
BA_ "GenSigAutoGenSnd" SG_ 2033 signal11769 0;
BA_ "GenSigAutoGenDsp" SG_ 2033 signal11769 0;
BA_ "NMH-WakeupAllowed" SG_ 2041 signal11786 0;
BA_ "NWM-WakeupAllowed" SG_ 2041 signal11786 0;
BA_ "GenSigSendType" SG_ 2041 signal11786 7;
BA_ "GenSigEnvVarType" SG_ 2041 signal11786 0;
BA_ "GenSigAutoGenSnd" SG_ 2041 signal11786 0;
BA_ "GenSigAutoGenDsp" SG_ 2041 signal11786 0;
BA_ "GenSigTimeoutMsg_ecu11949" SG_ 133 signal11807 133;
BA_ "signal136198" SG_ 133 signal11807 133;
BA_ "signal133356" SG_ 133 signal11807 133;
BA_ "GenSigTimeoutMsg_ecu13120" SG_ 133 signal11807 133;
BA_ "GenSigTimeoutMsg_ecu13186" SG_ 133 signal11807 133;
BA_ "GenSigTimeoutMsg_ecu9211" SG_ 133 signal11807 133;
BA_ "NMH-WakeupAllowed" SG_ 133 signal11807 0;
BA_ "NWM-WakeupAllowed" SG_ 133 signal11807 0;
BA_ "GenSigSendType" SG_ 133 signal11807 7;
BA_ "GenSigEnvVarType" SG_ 133 signal11807 0;
BA_ "GenSigAutoGenSnd" SG_ 133 signal11807 1;
BA_ "GenSigAutoGenDsp" SG_ 133 signal11807 1;
BA_ "GenSigTimeoutMsg_ecu11949" SG_ 133 signal11823 133;
BA_ "signal136198" SG_ 133 signal11823 133;
BA_ "signal133356" SG_ 133 signal11823 133;
BA_ "GenSigTimeoutMsg_ecu13120" SG_ 133 signal11823 133;
BA_ "GenSigTimeoutMsg_ecu13186" SG_ 133 signal11823 133;
BA_ "GenSigTimeoutMsg_ecu9211" SG_ 133 signal11823 133;
BA_ "NMH-WakeupAllowed" SG_ 133 signal11823 0;
BA_ "NWM-WakeupAllowed" SG_ 133 signal11823 0;
BA_ "GenSigSendType" SG_ 133 signal11823 7;
BA_ "GenSigEnvVarType" SG_ 133 signal11823 0;
BA_ "GenSigAutoGenSnd" SG_ 133 signal11823 1;
BA_ "GenSigAutoGenDsp" SG_ 133 signal11823 1;
BA_ "GenSigTimeoutMsg_ecu11949" SG_ 133 signal11839 133;
BA_ "signal136198" SG_ 133 signal11839 133;
BA_ "signal133356" SG_ 133 signal11839 133;
BA_ "GenSigTimeoutMsg_ecu13120" SG_ 133 signal11839 133;
BA_ "GenSigTimeoutMsg_ecu13186" SG_ 133 signal11839 133;
BA_ "GenSigTimeoutMsg_ecu9211" SG_ 133 signal11839 133;
BA_ "NMH-WakeupAllowed" SG_ 133 signal11839 0;
BA_ "NWM-WakeupAllowed" SG_ 133 signal11839 0;
BA_ "GenSigStartValue" SG_ 133 signal11839 4094;
BA_ "GenSigSendType" SG_ 133 signal11839 7;
BA_ "GenSigEnvVarType" SG_ 133 signal11839 1;
BA_ "GenSigAutoGenSnd" SG_ 133 signal11839 1;
BA_ "GenSigAutoGenDsp" SG_ 133 signal11839 1;
BA_ "GenSigTimeoutMsg_ecu11949" SG_ 133 signal11855 133;
BA_ "signal136198" SG_ 133 signal11855 133;
BA_ "signal133356" SG_ 133 signal11855 133;
BA_ "GenSigTimeoutMsg_ecu13120" SG_ 133 signal11855 133;
BA_ "GenSigTimeoutMsg_ecu13186" SG_ 133 signal11855 133;
BA_ "GenSigTimeoutMsg_ecu9211" SG_ 133 signal11855 133;
BA_ "NMH-WakeupAllowed" SG_ 133 signal11855 0;
BA_ "NWM-WakeupAllowed" SG_ 133 signal11855 0;
BA_ "GenSigSendType" SG_ 133 signal11855 7;
BA_ "GenSigEnvVarType" SG_ 133 signal11855 0;
BA_ "GenSigAutoGenSnd" SG_ 133 signal11855 1;
BA_ "GenSigAutoGenDsp" SG_ 133 signal11855 1;
BA_ "GenSigTimeoutMsg_ecu11949" SG_ 133 signal11871 133;
BA_ "GenSigTimeoutMsg_ecu13186" SG_ 133 signal11871 133;
BA_ "GenSigTimeoutMsg_ecu9211" SG_ 133 signal11871 133;
BA_ "NMH-WakeupAllowed" SG_ 133 signal11871 0;
BA_ "NWM-WakeupAllowed" SG_ 133 signal11871 0;
BA_ "GenSigStartValue" SG_ 133 signal11871 2046;
BA_ "GenSigSendType" SG_ 133 signal11871 7;
BA_ "GenSigEnvVarType" SG_ 133 signal11871 1;
BA_ "GenSigAutoGenSnd" SG_ 133 signal11871 1;
BA_ "GenSigAutoGenDsp" SG_ 133 signal11871 1;
BA_ "GenSigTimeoutMsg_ecu11949" SG_ 133 signal11884 133;
BA_ "GenSigTimeoutMsg_ecu13186" SG_ 133 signal11884 133;
BA_ "GenSigTimeoutMsg_ecu9211" SG_ 133 signal11884 133;
BA_ "NMH-WakeupAllowed" SG_ 133 signal11884 0;
BA_ "NWM-WakeupAllowed" SG_ 133 signal11884 0;
BA_ "GenSigSendType" SG_ 133 signal11884 7;
BA_ "GenSigEnvVarType" SG_ 133 signal11884 0;
BA_ "GenSigAutoGenSnd" SG_ 133 signal11884 1;
BA_ "GenSigAutoGenDsp" SG_ 133 signal11884 1;
BA_ "GenSigTimeoutMsg_ecu11949" SG_ 133 signal11897 133;
BA_ "GenSigTimeoutMsg_ecu13186" SG_ 133 signal11897 133;
BA_ "GenSigTimeoutMsg_ecu9211" SG_ 133 signal11897 133;
BA_ "NMH-WakeupAllowed" SG_ 133 signal11897 0;
BA_ "NWM-WakeupAllowed" SG_ 133 signal11897 0;
BA_ "GenSigSendType" SG_ 133 signal11897 7;
BA_ "GenSigEnvVarType" SG_ 133 signal11897 0;
BA_ "GenSigAutoGenSnd" SG_ 133 signal11897 1;
BA_ "GenSigAutoGenDsp" SG_ 133 signal11897 1;
BA_ "GenSigTimeoutMsg_ecu11949" SG_ 133 signal11910 133;
BA_ "signal136198" SG_ 133 signal11910 133;
BA_ "signal133356" SG_ 133 signal11910 133;
BA_ "GenSigTimeoutMsg_ecu13120" SG_ 133 signal11910 133;
BA_ "GenSigTimeoutMsg_ecu13186" SG_ 133 signal11910 133;
BA_ "GenSigTimeoutMsg_ecu9211" SG_ 133 signal11910 133;
BA_ "NMH-WakeupAllowed" SG_ 133 signal11910 0;
BA_ "NWM-WakeupAllowed" SG_ 133 signal11910 0;
BA_ "GenSigStartValue" SG_ 133 signal11910 1;
BA_ "GenSigSendType" SG_ 133 signal11910 7;
BA_ "GenSigEnvVarType" SG_ 133 signal11910 0;
BA_ "GenSigAutoGenSnd" SG_ 133 signal11910 1;
BA_ "GenSigAutoGenDsp" SG_ 133 signal11910 1;
BA_ "GenSigTimeoutMsg_ecu11949" SG_ 133 signal11926 133;
BA_ "GenSigTimeoutMsg_ecu13186" SG_ 133 signal11926 133;
BA_ "GenSigTimeoutMsg_ecu9211" SG_ 133 signal11926 133;
BA_ "NMH-WakeupAllowed" SG_ 133 signal11926 0;
BA_ "NWM-WakeupAllowed" SG_ 133 signal11926 0;
BA_ "GenSigSendType" SG_ 133 signal11926 7;
BA_ "GenSigEnvVarType" SG_ 133 signal11926 0;
BA_ "GenSigAutoGenSnd" SG_ 133 signal11926 1;
BA_ "GenSigAutoGenDsp" SG_ 133 signal11926 1;
BA_ "GenSigTimeoutMsg_ecu11949" SG_ 133 signal11939 133;
BA_ "GenSigTimeoutMsg_ecu13186" SG_ 133 signal11939 133;
BA_ "GenSigTimeoutMsg_ecu9211" SG_ 133 signal11939 133;
BA_ "NMH-WakeupAllowed" SG_ 133 signal11939 0;
BA_ "NWM-WakeupAllowed" SG_ 133 signal11939 0;
BA_ "GenSigSendType" SG_ 133 signal11939 7;
BA_ "GenSigEnvVarType" SG_ 133 signal11939 0;
BA_ "GenSigAutoGenSnd" SG_ 133 signal11939 1;
BA_ "GenSigAutoGenDsp" SG_ 133 signal11939 1;
BA_ "GenSigTimeoutMsg_ecu13186" SG_ 784 signal11958 784;
BA_ "NMH-WakeupAllowed" SG_ 784 signal11958 0;
BA_ "NWM-WakeupAllowed" SG_ 784 signal11958 0;
BA_ "GenSigSendType" SG_ 784 signal11958 7;
BA_ "GenSigEnvVarType" SG_ 784 signal11958 0;
BA_ "GenSigAutoGenSnd" SG_ 784 signal11958 1;
BA_ "GenSigAutoGenDsp" SG_ 784 signal11958 1;
BA_ "GenSigTimeoutMsg_ecu13186" SG_ 784 signal11969 784;
BA_ "NMH-WakeupAllowed" SG_ 784 signal11969 0;
BA_ "NWM-WakeupAllowed" SG_ 784 signal11969 0;
BA_ "GenSigSendType" SG_ 784 signal11969 7;
BA_ "GenSigEnvVarType" SG_ 784 signal11969 0;
BA_ "GenSigAutoGenSnd" SG_ 784 signal11969 1;
BA_ "GenSigAutoGenDsp" SG_ 784 signal11969 1;
BA_ "GenSigTimeoutMsg_ecu13186" SG_ 784 signal11980 784;
BA_ "NMH-WakeupAllowed" SG_ 784 signal11980 0;
BA_ "NWM-WakeupAllowed" SG_ 784 signal11980 0;
BA_ "GenSigSendType" SG_ 784 signal11980 7;
BA_ "GenSigEnvVarType" SG_ 784 signal11980 0;
BA_ "GenSigAutoGenSnd" SG_ 784 signal11980 1;
BA_ "GenSigAutoGenDsp" SG_ 784 signal11980 1;
BA_ "GenSigTimeoutMsg_ecu13186" SG_ 784 signal11991 784;
BA_ "NMH-WakeupAllowed" SG_ 784 signal11991 0;
BA_ "NWM-WakeupAllowed" SG_ 784 signal11991 0;
BA_ "GenSigSendType" SG_ 784 signal11991 7;
BA_ "GenSigEnvVarType" SG_ 784 signal11991 0;
BA_ "GenSigAutoGenSnd" SG_ 784 signal11991 1;
BA_ "GenSigAutoGenDsp" SG_ 784 signal11991 1;
BA_ "GenSigTimeoutMsg_ecu13186" SG_ 784 signal12002 784;
BA_ "NMH-WakeupAllowed" SG_ 784 signal12002 0;
BA_ "NWM-WakeupAllowed" SG_ 784 signal12002 0;
BA_ "GenSigSendType" SG_ 784 signal12002 7;
BA_ "GenSigEnvVarType" SG_ 784 signal12002 0;
BA_ "GenSigAutoGenSnd" SG_ 784 signal12002 1;
BA_ "GenSigAutoGenDsp" SG_ 784 signal12002 1;
BA_ "GenSigTimeoutMsg_ecu13186" SG_ 1313 signal12019 1313;
BA_ "NMH-WakeupAllowed" SG_ 1313 signal12019 0;
BA_ "NWM-WakeupAllowed" SG_ 1313 signal12019 0;
BA_ "GenSigSendType" SG_ 1313 signal12019 7;
BA_ "GenSigEnvVarType" SG_ 1313 signal12019 0;
BA_ "GenSigAutoGenSnd" SG_ 1313 signal12019 1;
BA_ "GenSigAutoGenDsp" SG_ 1313 signal12019 1;
BA_ "GenSigTimeoutMsg_ecu13186" SG_ 1313 signal12030 1313;
BA_ "NMH-WakeupAllowed" SG_ 1313 signal12030 0;
BA_ "NWM-WakeupAllowed" SG_ 1313 signal12030 0;
BA_ "GenSigSendType" SG_ 1313 signal12030 7;
BA_ "GenSigEnvVarType" SG_ 1313 signal12030 0;
BA_ "GenSigAutoGenSnd" SG_ 1313 signal12030 1;
BA_ "GenSigAutoGenDsp" SG_ 1313 signal12030 1;
BA_ "GenSigTimeoutMsg_ecu13186" SG_ 1313 signal12041 1313;
BA_ "NMH-WakeupAllowed" SG_ 1313 signal12041 0;
BA_ "NWM-WakeupAllowed" SG_ 1313 signal12041 0;
BA_ "GenSigSendType" SG_ 1313 signal12041 7;
BA_ "GenSigEnvVarType" SG_ 1313 signal12041 0;
BA_ "GenSigAutoGenSnd" SG_ 1313 signal12041 1;
BA_ "GenSigAutoGenDsp" SG_ 1313 signal12041 1;
BA_ "GenSigTimeoutMsg_ecu13186" SG_ 1313 signal12052 1313;
BA_ "NMH-WakeupAllowed" SG_ 1313 signal12052 0;
BA_ "NWM-WakeupAllowed" SG_ 1313 signal12052 0;
BA_ "GenSigSendType" SG_ 1313 signal12052 7;
BA_ "GenSigEnvVarType" SG_ 1313 signal12052 0;
BA_ "GenSigAutoGenSnd" SG_ 1313 signal12052 1;
BA_ "GenSigAutoGenDsp" SG_ 1313 signal12052 1;
BA_ "GenSigTimeoutMsg_ecu13186" SG_ 1313 signal12063 1313;
BA_ "NMH-WakeupAllowed" SG_ 1313 signal12063 0;
BA_ "NWM-WakeupAllowed" SG_ 1313 signal12063 0;
BA_ "GenSigSendType" SG_ 1313 signal12063 7;
BA_ "GenSigEnvVarType" SG_ 1313 signal12063 0;
BA_ "GenSigAutoGenSnd" SG_ 1313 signal12063 1;
BA_ "GenSigAutoGenDsp" SG_ 1313 signal12063 1;
BA_ "GenSigTimeoutMsg_ecu13186" SG_ 1313 signal12074 1313;
BA_ "NMH-WakeupAllowed" SG_ 1313 signal12074 0;
BA_ "NWM-WakeupAllowed" SG_ 1313 signal12074 0;
BA_ "GenSigSendType" SG_ 1313 signal12074 7;
BA_ "GenSigEnvVarType" SG_ 1313 signal12074 0;
BA_ "GenSigAutoGenSnd" SG_ 1313 signal12074 1;
BA_ "GenSigAutoGenDsp" SG_ 1313 signal12074 1;
BA_ "signal136198" SG_ 1313 signal12085 1313;
BA_ "GenSigTimeoutMsg_ecu13120" SG_ 1313 signal12085 1313;
BA_ "GenSigTimeoutMsg_ecu13186" SG_ 1313 signal12085 1313;
BA_ "NMH-WakeupAllowed" SG_ 1313 signal12085 0;
BA_ "NWM-WakeupAllowed" SG_ 1313 signal12085 0;
BA_ "GenSigSendType" SG_ 1313 signal12085 7;
BA_ "GenSigEnvVarType" SG_ 1313 signal12085 0;
BA_ "GenSigAutoGenSnd" SG_ 1313 signal12085 1;
BA_ "GenSigAutoGenDsp" SG_ 1313 signal12085 1;
BA_ "signal136198" SG_ 1313 signal12098 1313;
BA_ "GenSigTimeoutMsg_ecu13120" SG_ 1313 signal12098 1313;
BA_ "GenSigTimeoutMsg_ecu13186" SG_ 1313 signal12098 1313;
BA_ "NMH-WakeupAllowed" SG_ 1313 signal12098 0;
BA_ "NWM-WakeupAllowed" SG_ 1313 signal12098 0;
BA_ "GenSigSendType" SG_ 1313 signal12098 7;
BA_ "GenSigEnvVarType" SG_ 1313 signal12098 0;
BA_ "GenSigAutoGenSnd" SG_ 1313 signal12098 1;
BA_ "GenSigAutoGenDsp" SG_ 1313 signal12098 1;
BA_ "signal136198" SG_ 1313 signal12111 1313;
BA_ "GenSigTimeoutMsg_ecu13120" SG_ 1313 signal12111 1313;
BA_ "GenSigTimeoutMsg_ecu13186" SG_ 1313 signal12111 1313;
BA_ "NMH-WakeupAllowed" SG_ 1313 signal12111 0;
BA_ "NWM-WakeupAllowed" SG_ 1313 signal12111 0;
BA_ "GenSigSendType" SG_ 1313 signal12111 7;
BA_ "GenSigEnvVarType" SG_ 1313 signal12111 0;
BA_ "GenSigAutoGenSnd" SG_ 1313 signal12111 1;
BA_ "GenSigAutoGenDsp" SG_ 1313 signal12111 1;
BA_ "GenSigTimeoutMsg_ecu13186" SG_ 1313 signal12124 1313;
BA_ "NMH-WakeupAllowed" SG_ 1313 signal12124 0;
BA_ "NWM-WakeupAllowed" SG_ 1313 signal12124 0;
BA_ "GenSigSendType" SG_ 1313 signal12124 7;
BA_ "GenSigEnvVarType" SG_ 1313 signal12124 0;
BA_ "GenSigAutoGenSnd" SG_ 1313 signal12124 1;
BA_ "GenSigAutoGenDsp" SG_ 1313 signal12124 1;
BA_ "GenSigTimeoutMsg_ecu13186" SG_ 1313 signal12135 1313;
BA_ "NMH-WakeupAllowed" SG_ 1313 signal12135 0;
BA_ "NWM-WakeupAllowed" SG_ 1313 signal12135 0;
BA_ "GenSigSendType" SG_ 1313 signal12135 7;
BA_ "GenSigEnvVarType" SG_ 1313 signal12135 0;
BA_ "GenSigAutoGenSnd" SG_ 1313 signal12135 1;
BA_ "GenSigAutoGenDsp" SG_ 1313 signal12135 1;
BA_ "GenSigTimeoutMsg_ecu13186" SG_ 1313 signal12146 1313;
BA_ "NMH-WakeupAllowed" SG_ 1313 signal12146 0;
BA_ "NWM-WakeupAllowed" SG_ 1313 signal12146 0;
BA_ "GenSigSendType" SG_ 1313 signal12146 7;
BA_ "GenSigEnvVarType" SG_ 1313 signal12146 0;
BA_ "GenSigAutoGenSnd" SG_ 1313 signal12146 1;
BA_ "GenSigAutoGenDsp" SG_ 1313 signal12146 1;
BA_ "GenSigTimeoutMsg_ecu13186" SG_ 1313 signal12157 1313;
BA_ "NMH-WakeupAllowed" SG_ 1313 signal12157 0;
BA_ "NWM-WakeupAllowed" SG_ 1313 signal12157 0;
BA_ "GenSigStartValue" SG_ 1313 signal12157 254;
BA_ "GenSigSendType" SG_ 1313 signal12157 7;
BA_ "GenSigEnvVarType" SG_ 1313 signal12157 1;
BA_ "GenSigAutoGenSnd" SG_ 1313 signal12157 1;
BA_ "GenSigAutoGenDsp" SG_ 1313 signal12157 1;
BA_ "signal136198" SG_ 1313 signal12168 1313;
BA_ "GenSigTimeoutMsg_ecu13120" SG_ 1313 signal12168 1313;
BA_ "GenSigTimeoutMsg_ecu13186" SG_ 1313 signal12168 1313;
BA_ "NMH-WakeupAllowed" SG_ 1313 signal12168 0;
BA_ "NWM-WakeupAllowed" SG_ 1313 signal12168 0;
BA_ "GenSigSendType" SG_ 1313 signal12168 7;
BA_ "GenSigEnvVarType" SG_ 1313 signal12168 0;
BA_ "GenSigAutoGenSnd" SG_ 1313 signal12168 1;
BA_ "GenSigAutoGenDsp" SG_ 1313 signal12168 1;
BA_ "GenSigTimeoutMsg_ecu13186" SG_ 1313 signal12181 1313;
BA_ "NMH-WakeupAllowed" SG_ 1313 signal12181 0;
BA_ "NWM-WakeupAllowed" SG_ 1313 signal12181 0;
BA_ "GenSigSendType" SG_ 1313 signal12181 7;
BA_ "GenSigEnvVarType" SG_ 1313 signal12181 0;
BA_ "GenSigAutoGenSnd" SG_ 1313 signal12181 1;
BA_ "GenSigAutoGenDsp" SG_ 1313 signal12181 1;
BA_ "signal136198" SG_ 1313 signal12192 1313;
BA_ "GenSigTimeoutMsg_ecu13120" SG_ 1313 signal12192 1313;
BA_ "GenSigTimeoutMsg_ecu13186" SG_ 1313 signal12192 1313;
BA_ "NMH-WakeupAllowed" SG_ 1313 signal12192 0;
BA_ "NWM-WakeupAllowed" SG_ 1313 signal12192 0;
BA_ "GenSigSendType" SG_ 1313 signal12192 7;
BA_ "GenSigEnvVarType" SG_ 1313 signal12192 0;
BA_ "GenSigAutoGenSnd" SG_ 1313 signal12192 1;
BA_ "GenSigAutoGenDsp" SG_ 1313 signal12192 1;
BA_ "GenSigTimeoutMsg_ecu13186" SG_ 1313 signal12205 1313;
BA_ "NMH-WakeupAllowed" SG_ 1313 signal12205 0;
BA_ "NWM-WakeupAllowed" SG_ 1313 signal12205 0;
BA_ "GenSigSendType" SG_ 1313 signal12205 7;
BA_ "GenSigEnvVarType" SG_ 1313 signal12205 0;
BA_ "GenSigAutoGenSnd" SG_ 1313 signal12205 1;
BA_ "GenSigAutoGenDsp" SG_ 1313 signal12205 1;
BA_ "GenSigTimeoutMsg_ecu13186" SG_ 1313 signal12216 1313;
BA_ "NMH-WakeupAllowed" SG_ 1313 signal12216 0;
BA_ "NWM-WakeupAllowed" SG_ 1313 signal12216 0;
BA_ "GenSigSendType" SG_ 1313 signal12216 7;
BA_ "GenSigEnvVarType" SG_ 1313 signal12216 0;
BA_ "GenSigAutoGenSnd" SG_ 1313 signal12216 1;
BA_ "GenSigAutoGenDsp" SG_ 1313 signal12216 1;
BA_ "GenSigTimeoutMsg_ecu13186" SG_ 1650 signal12233 1650;
BA_ "NMH-WakeupAllowed" SG_ 1650 signal12233 0;
BA_ "NWM-WakeupAllowed" SG_ 1650 signal12233 0;
BA_ "GenSigSendType" SG_ 1650 signal12233 7;
BA_ "GenSigEVName" SG_ 1650 signal12233 "@signame";
BA_ "GenSigAutoGenSnd" SG_ 1650 signal12233 1;
BA_ "GenSigAutoGenDsp" SG_ 1650 signal12233 1;
BA_ "GenSigTimeoutMsg_ecu13186" SG_ 1650 signal12244 1650;
BA_ "NMH-WakeupAllowed" SG_ 1650 signal12244 0;
BA_ "NWM-WakeupAllowed" SG_ 1650 signal12244 0;
BA_ "GenSigSendType" SG_ 1650 signal12244 7;
BA_ "GenSigEVName" SG_ 1650 signal12244 "@signame";
BA_ "GenSigAutoGenSnd" SG_ 1650 signal12244 1;
BA_ "GenSigAutoGenDsp" SG_ 1650 signal12244 1;
BA_ "GenSigTimeoutMsg_ecu13186" SG_ 1650 signal12255 1650;
BA_ "NMH-WakeupAllowed" SG_ 1650 signal12255 0;
BA_ "NWM-WakeupAllowed" SG_ 1650 signal12255 0;
BA_ "GenSigSendType" SG_ 1650 signal12255 7;
BA_ "GenSigEVName" SG_ 1650 signal12255 "@signame";
BA_ "GenSigAutoGenSnd" SG_ 1650 signal12255 1;
BA_ "GenSigAutoGenDsp" SG_ 1650 signal12255 1;
BA_ "GenSigTimeoutMsg_ecu13186" SG_ 1650 signal12266 1650;
BA_ "NMH-WakeupAllowed" SG_ 1650 signal12266 0;
BA_ "NWM-WakeupAllowed" SG_ 1650 signal12266 0;
BA_ "GenSigSendType" SG_ 1650 signal12266 7;
BA_ "GenSigEVName" SG_ 1650 signal12266 "@signame";
BA_ "GenSigAutoGenSnd" SG_ 1650 signal12266 1;
BA_ "GenSigAutoGenDsp" SG_ 1650 signal12266 1;
BA_ "GenSigTimeoutMsg_ecu13186" SG_ 1650 signal12277 1650;
BA_ "NMH-WakeupAllowed" SG_ 1650 signal12277 0;
BA_ "NWM-WakeupAllowed" SG_ 1650 signal12277 0;
BA_ "GenSigSendType" SG_ 1650 signal12277 7;
BA_ "GenSigEVName" SG_ 1650 signal12277 "@signame";
BA_ "GenSigAutoGenSnd" SG_ 1650 signal12277 1;
BA_ "GenSigAutoGenDsp" SG_ 1650 signal12277 1;
BA_ "GenSigTimeoutMsg_ecu13186" SG_ 1650 signal12288 1650;
BA_ "NMH-WakeupAllowed" SG_ 1650 signal12288 0;
BA_ "NWM-WakeupAllowed" SG_ 1650 signal12288 0;
BA_ "GenSigSendType" SG_ 1650 signal12288 7;
BA_ "GenSigEVName" SG_ 1650 signal12288 "@signame";
BA_ "GenSigAutoGenSnd" SG_ 1650 signal12288 1;
BA_ "GenSigAutoGenDsp" SG_ 1650 signal12288 1;
BA_ "NMH-WakeupAllowed" SG_ 1413 signal12305 0;
BA_ "NWM-WakeupAllowed" SG_ 1413 signal12305 0;
BA_ "GenSigSendType" SG_ 1413 signal12305 7;
BA_ "GenSigEnvVarType" SG_ 1413 signal12305 0;
BA_ "GenSigAutoGenSnd" SG_ 1413 signal12305 1;
BA_ "GenSigAutoGenDsp" SG_ 1413 signal12305 1;
BA_ "GenSigTimeoutMsg_ecu12990" SG_ 1413 signal12315 1413;
BA_ "NMH-WakeupAllowed" SG_ 1413 signal12315 0;
BA_ "NWM-WakeupAllowed" SG_ 1413 signal12315 0;
BA_ "GenSigStartValue" SG_ 1413 signal12315 1;
BA_ "GenSigSendType" SG_ 1413 signal12315 3;
BA_ "GenSigEnvVarType" SG_ 1413 signal12315 0;
BA_ "GenSigAutoGenSnd" SG_ 1413 signal12315 1;
BA_ "GenSigAutoGenDsp" SG_ 1413 signal12315 1;
BA_ "NMH-WakeupAllowed" SG_ 1413 signal12326 0;
BA_ "NWM-WakeupAllowed" SG_ 1413 signal12326 0;
BA_ "GenSigSendType" SG_ 1413 signal12326 7;
BA_ "GenSigEnvVarType" SG_ 1413 signal12326 0;
BA_ "GenSigAutoGenSnd" SG_ 1413 signal12326 1;
BA_ "GenSigAutoGenDsp" SG_ 1413 signal12326 1;
BA_ "GenSigTimeoutMsg_ecu12594" SG_ 1209 signal12342 1209;
BA_ "NMH-WakeupAllowed" SG_ 1209 signal12342 0;
BA_ "NWM-WakeupAllowed" SG_ 1209 signal12342 0;
BA_ "GenSigSendType" SG_ 1209 signal12342 7;
BA_ "GenSigEnvVarType" SG_ 1209 signal12342 0;
BA_ "GenSigAutoGenSnd" SG_ 1209 signal12342 0;
BA_ "GenSigAutoGenDsp" SG_ 1209 signal12342 0;
BA_ "GenSigTimeoutMsg_ecu13186" SG_ 1215 signal12376 1215;
BA_ "NMH-WakeupAllowed" SG_ 1215 signal12376 0;
BA_ "NWM-WakeupAllowed" SG_ 1215 signal12376 0;
BA_ "GenSigSendType" SG_ 1215 signal12376 7;
BA_ "GenSigEnvVarType" SG_ 1215 signal12376 0;
BA_ "GenSigAutoGenSnd" SG_ 1215 signal12376 0;
BA_ "GenSigAutoGenDsp" SG_ 1215 signal12376 0;
BA_ "GenSigTimeoutMsg_ecu13186" SG_ 1303 signal12393 1303;
BA_ "NMH-WakeupAllowed" SG_ 1303 signal12393 0;
BA_ "NWM-WakeupAllowed" SG_ 1303 signal12393 0;
BA_ "GenSigSendType" SG_ 1303 signal12393 7;
BA_ "GenSigEnvVarType" SG_ 1303 signal12393 0;
BA_ "GenSigAutoGenSnd" SG_ 1303 signal12393 0;
BA_ "GenSigAutoGenDsp" SG_ 1303 signal12393 0;
BA_ "signal142820" SG_ 1214 signal12410 1214;
BA_ "NMH-WakeupAllowed" SG_ 1214 signal12410 0;
BA_ "NWM-WakeupAllowed" SG_ 1214 signal12410 0;
BA_ "GenSigSendType" SG_ 1214 signal12410 7;
BA_ "GenSigEnvVarType" SG_ 1214 signal12410 0;
BA_ "GenSigAutoGenSnd" SG_ 1214 signal12410 0;
BA_ "GenSigAutoGenDsp" SG_ 1214 signal12410 0;
BA_ "GenSigTimeoutMsg_ecu12990" SG_ 1231 signal12427 1231;
BA_ "NMH-WakeupAllowed" SG_ 1231 signal12427 0;
BA_ "NWM-WakeupAllowed" SG_ 1231 signal12427 0;
BA_ "GenSigSendType" SG_ 1231 signal12427 7;
BA_ "GenSigEnvVarType" SG_ 1231 signal12427 0;
BA_ "GenSigAutoGenSnd" SG_ 1231 signal12427 0;
BA_ "GenSigAutoGenDsp" SG_ 1231 signal12427 0;
BA_ "GenSigTimeoutMsg_ecu13186" SG_ 768 signal12461 768;
BA_ "NMH-WakeupAllowed" SG_ 768 signal12461 0;
BA_ "NWM-WakeupAllowed" SG_ 768 signal12461 0;
BA_ "GenSigSendType" SG_ 768 signal12461 7;
BA_ "GenSigEnvVarType" SG_ 768 signal12461 0;
BA_ "GenSigAutoGenSnd" SG_ 768 signal12461 0;
BA_ "GenSigAutoGenDsp" SG_ 768 signal12461 0;
BA_ "GenSigTimeoutMsg_ecu13186" SG_ 769 signal12478 769;
BA_ "NMH-WakeupAllowed" SG_ 769 signal12478 0;
BA_ "NWM-WakeupAllowed" SG_ 769 signal12478 0;
BA_ "GenSigSendType" SG_ 769 signal12478 7;
BA_ "GenSigEnvVarType" SG_ 769 signal12478 0;
BA_ "GenSigAutoGenSnd" SG_ 769 signal12478 0;
BA_ "GenSigAutoGenDsp" SG_ 769 signal12478 0;
BA_ "GenSigTimeoutMsg_ecu13186" SG_ 770 signal12495 770;
BA_ "NMH-WakeupAllowed" SG_ 770 signal12495 0;
BA_ "NWM-WakeupAllowed" SG_ 770 signal12495 0;
BA_ "GenSigSendType" SG_ 770 signal12495 7;
BA_ "GenSigEnvVarType" SG_ 770 signal12495 0;
BA_ "GenSigAutoGenSnd" SG_ 770 signal12495 0;
BA_ "GenSigAutoGenDsp" SG_ 770 signal12495 0;
BA_ "GenSigTimeoutMsg_ecu13186" SG_ 771 signal12512 771;
BA_ "NMH-WakeupAllowed" SG_ 771 signal12512 0;
BA_ "NWM-WakeupAllowed" SG_ 771 signal12512 0;
BA_ "GenSigSendType" SG_ 771 signal12512 7;
BA_ "GenSigEnvVarType" SG_ 771 signal12512 0;
BA_ "GenSigAutoGenSnd" SG_ 771 signal12512 0;
BA_ "GenSigAutoGenDsp" SG_ 771 signal12512 0;
BA_ "GenSigTimeoutMsg_ecu13186" SG_ 772 signal12529 772;
BA_ "NMH-WakeupAllowed" SG_ 772 signal12529 0;
BA_ "NWM-WakeupAllowed" SG_ 772 signal12529 0;
BA_ "GenSigSendType" SG_ 772 signal12529 7;
BA_ "GenSigEnvVarType" SG_ 772 signal12529 0;
BA_ "GenSigAutoGenSnd" SG_ 772 signal12529 0;
BA_ "GenSigAutoGenDsp" SG_ 772 signal12529 0;
BA_ "GenSigTimeoutMsg_ecu13186" SG_ 773 signal12546 773;
BA_ "NMH-WakeupAllowed" SG_ 773 signal12546 0;
BA_ "NWM-WakeupAllowed" SG_ 773 signal12546 0;
BA_ "GenSigSendType" SG_ 773 signal12546 7;
BA_ "GenSigEnvVarType" SG_ 773 signal12546 0;
BA_ "GenSigAutoGenSnd" SG_ 773 signal12546 0;
BA_ "GenSigAutoGenDsp" SG_ 773 signal12546 0;
BA_ "GenSigTimeoutMsg_ecu13186" SG_ 774 signal12563 774;
BA_ "NMH-WakeupAllowed" SG_ 774 signal12563 0;
BA_ "NWM-WakeupAllowed" SG_ 774 signal12563 0;
BA_ "GenSigSendType" SG_ 774 signal12563 7;
BA_ "GenSigEnvVarType" SG_ 774 signal12563 0;
BA_ "GenSigAutoGenSnd" SG_ 774 signal12563 0;
BA_ "GenSigAutoGenDsp" SG_ 774 signal12563 0;
BA_ "GenSigTimeoutMsg_ecu13186" SG_ 775 signal12580 775;
BA_ "NMH-WakeupAllowed" SG_ 775 signal12580 0;
BA_ "NWM-WakeupAllowed" SG_ 775 signal12580 0;
BA_ "GenSigSendType" SG_ 775 signal12580 7;
BA_ "GenSigEnvVarType" SG_ 775 signal12580 0;
BA_ "GenSigAutoGenSnd" SG_ 775 signal12580 0;
BA_ "GenSigAutoGenDsp" SG_ 775 signal12580 0;
BA_ "GenSigTimeoutMsg_ecu13186" SG_ 537 signal12597 537;
BA_ "NMH-WakeupAllowed" SG_ 537 signal12597 0;
BA_ "NWM-WakeupAllowed" SG_ 537 signal12597 0;
BA_ "GenSigSendType" SG_ 537 signal12597 7;
BA_ "GenSigEnvVarType" SG_ 537 signal12597 0;
BA_ "GenSigAutoGenSnd" SG_ 537 signal12597 0;
BA_ "GenSigAutoGenDsp" SG_ 537 signal12597 0;
BA_ "GenSigTimeoutMsg_ecu12990" SG_ 543 signal12614 543;
BA_ "NMH-WakeupAllowed" SG_ 543 signal12614 0;
BA_ "NWM-WakeupAllowed" SG_ 543 signal12614 0;
BA_ "GenSigSendType" SG_ 543 signal12614 7;
BA_ "GenSigEnvVarType" SG_ 543 signal12614 0;
BA_ "GenSigAutoGenSnd" SG_ 543 signal12614 0;
BA_ "GenSigAutoGenDsp" SG_ 543 signal12614 0;
BA_ "GenSigTimeoutMsg_ecu13186" SG_ 542 signal12631 542;
BA_ "NMH-WakeupAllowed" SG_ 542 signal12631 0;
BA_ "NWM-WakeupAllowed" SG_ 542 signal12631 0;
BA_ "GenSigSendType" SG_ 542 signal12631 7;
BA_ "GenSigEnvVarType" SG_ 542 signal12631 0;
BA_ "GenSigAutoGenSnd" SG_ 542 signal12631 0;
BA_ "GenSigAutoGenDsp" SG_ 542 signal12631 0;
BA_ "GenSigTimeoutMsg_ecu13186" SG_ 559 signal12643_Data 559;
BA_ "NMH-WakeupAllowed" SG_ 559 signal12643_Data 0;
BA_ "NWM-WakeupAllowed" SG_ 559 signal12643_Data 0;
BA_ "GenSigSendType" SG_ 559 signal12643_Data 7;
BA_ "GenSigEnvVarType" SG_ 559 signal12643_Data 0;
BA_ "GenSigAutoGenSnd" SG_ 559 signal12643_Data 0;
BA_ "GenSigAutoGenDsp" SG_ 559 signal12643_Data 0;
BA_ "GenSigTimeoutMsg_ecu12990" SG_ 512 signal12665 512;
BA_ "signal142820" SG_ 512 signal12665 512;
BA_ "GenSigTimeoutMsg_ecu12594" SG_ 512 signal12665 512;
BA_ "NMH-WakeupAllowed" SG_ 512 signal12665 0;
BA_ "NWM-WakeupAllowed" SG_ 512 signal12665 0;
BA_ "GenSigSendType" SG_ 512 signal12665 7;
BA_ "GenSigEnvVarType" SG_ 512 signal12665 0;
BA_ "GenSigAutoGenSnd" SG_ 512 signal12665 0;
BA_ "GenSigAutoGenDsp" SG_ 512 signal12665 0;
BA_ "GenSigTimeoutMsg_ecu12990" SG_ 1716 signal12684 1716;
BA_ "signal142820" SG_ 1716 signal12684 1716;
BA_ "signal142827" SG_ 1716 signal12684 1716;
BA_ "signal142834" SG_ 1716 signal12684 1716;
BA_ "NMH-WakeupAllowed" SG_ 1716 signal12684 0;
BA_ "NWM-WakeupAllowed" SG_ 1716 signal12684 0;
BA_ "GenSigSendType" SG_ 1716 signal12684 7;
BA_ "GenSigEnvVarType" SG_ 1716 signal12684 0;
BA_ "GenSigAutoGenSnd" SG_ 1716 signal12684 1;
BA_ "GenSigAutoGenDsp" SG_ 1716 signal12684 1;
BA_ "GenSigTimeoutMsg_ecu12990" SG_ 1716 signal12699 1716;
BA_ "signal142834" SG_ 1716 signal12699 1716;
BA_ "NMH-WakeupAllowed" SG_ 1716 signal12699 0;
BA_ "NWM-WakeupAllowed" SG_ 1716 signal12699 0;
BA_ "GenSigSendType" SG_ 1716 signal12699 7;
BA_ "GenSigEnvVarType" SG_ 1716 signal12699 0;
BA_ "GenSigAutoGenSnd" SG_ 1716 signal12699 1;
BA_ "GenSigAutoGenDsp" SG_ 1716 signal12699 1;
BA_ "GenSigTimeoutMsg_ecu12990" SG_ 1716 signal12712 1716;
BA_ "signal142827" SG_ 1716 signal12712 1716;
BA_ "signal142834" SG_ 1716 signal12712 1716;
BA_ "NMH-WakeupAllowed" SG_ 1716 signal12712 0;
BA_ "NWM-WakeupAllowed" SG_ 1716 signal12712 0;
BA_ "GenSigSendType" SG_ 1716 signal12712 7;
BA_ "GenSigEnvVarType" SG_ 1716 signal12712 0;
BA_ "GenSigAutoGenSnd" SG_ 1716 signal12712 1;
BA_ "GenSigAutoGenDsp" SG_ 1716 signal12712 1;
BA_ "GenSigTimeoutMsg_ecu12990" SG_ 1716 signal128641 1716;
BA_ "signal142827" SG_ 1716 signal128641 1716;
BA_ "signal142834" SG_ 1716 signal128641 1716;
BA_ "NMH-WakeupAllowed" SG_ 1716 signal128641 0;
BA_ "NWM-WakeupAllowed" SG_ 1716 signal128641 0;
BA_ "GenSigSendType" SG_ 1716 signal128641 7;
BA_ "GenSigEnvVarType" SG_ 1716 signal128641 0;
BA_ "GenSigAutoGenSnd" SG_ 1716 signal128641 1;
BA_ "GenSigAutoGenDsp" SG_ 1716 signal128641 1;
BA_ "GenSigTimeoutMsg_ecu12990" SG_ 1716 signal12740 1716;
BA_ "signal142834" SG_ 1716 signal12740 1716;
BA_ "NMH-WakeupAllowed" SG_ 1716 signal12740 0;
BA_ "NWM-WakeupAllowed" SG_ 1716 signal12740 0;
BA_ "GenSigSendType" SG_ 1716 signal12740 7;
BA_ "GenSigEnvVarType" SG_ 1716 signal12740 0;
BA_ "GenSigAutoGenSnd" SG_ 1716 signal12740 1;
BA_ "GenSigAutoGenDsp" SG_ 1716 signal12740 1;
BA_ "GenSigTimeoutMsg_ecu12990" SG_ 1716 signal12753 1716;
BA_ "signal142827" SG_ 1716 signal12753 1716;
BA_ "signal142834" SG_ 1716 signal12753 1716;
BA_ "NMH-WakeupAllowed" SG_ 1716 signal12753 0;
BA_ "NWM-WakeupAllowed" SG_ 1716 signal12753 0;
BA_ "GenSigSendType" SG_ 1716 signal12753 7;
BA_ "GenSigEnvVarType" SG_ 1716 signal12753 0;
BA_ "GenSigAutoGenSnd" SG_ 1716 signal12753 1;
BA_ "GenSigAutoGenDsp" SG_ 1716 signal12753 1;
BA_ "GenSigTimeoutMsg_ecu12990" SG_ 1716 signal12767 1716;
BA_ "signal142827" SG_ 1716 signal12767 1716;
BA_ "signal142834" SG_ 1716 signal12767 1716;
BA_ "NMH-WakeupAllowed" SG_ 1716 signal12767 0;
BA_ "NWM-WakeupAllowed" SG_ 1716 signal12767 0;
BA_ "GenSigSendType" SG_ 1716 signal12767 7;
BA_ "GenSigEnvVarType" SG_ 1716 signal12767 0;
BA_ "GenSigAutoGenSnd" SG_ 1716 signal12767 1;
BA_ "GenSigAutoGenDsp" SG_ 1716 signal12767 1;
BA_ "GenSigTimeoutMsg_ecu12990" SG_ 1716 signal12781 1716;
BA_ "signal142834" SG_ 1716 signal12781 1716;
BA_ "NMH-WakeupAllowed" SG_ 1716 signal12781 0;
BA_ "NWM-WakeupAllowed" SG_ 1716 signal12781 0;
BA_ "GenSigSendType" SG_ 1716 signal12781 7;
BA_ "GenSigEnvVarType" SG_ 1716 signal12781 0;
BA_ "GenSigAutoGenSnd" SG_ 1716 signal12781 1;
BA_ "GenSigAutoGenDsp" SG_ 1716 signal12781 1;
BA_ "GenSigTimeoutMsg_ecu12990" SG_ 1716 signal12794 1716;
BA_ "signal142827" SG_ 1716 signal12794 1716;
BA_ "signal142834" SG_ 1716 signal12794 1716;
BA_ "NMH-WakeupAllowed" SG_ 1716 signal12794 0;
BA_ "NWM-WakeupAllowed" SG_ 1716 signal12794 0;
BA_ "GenSigSendType" SG_ 1716 signal12794 7;
BA_ "GenSigEnvVarType" SG_ 1716 signal12794 0;
BA_ "GenSigAutoGenSnd" SG_ 1716 signal12794 1;
BA_ "GenSigAutoGenDsp" SG_ 1716 signal12794 1;
BA_ "GenSigTimeoutMsg_ecu12990" SG_ 1716 signal128643 1716;
BA_ "signal142827" SG_ 1716 signal128643 1716;
BA_ "signal142834" SG_ 1716 signal128643 1716;
BA_ "NMH-WakeupAllowed" SG_ 1716 signal128643 0;
BA_ "NWM-WakeupAllowed" SG_ 1716 signal128643 0;
BA_ "GenSigSendType" SG_ 1716 signal128643 7;
BA_ "GenSigEnvVarType" SG_ 1716 signal128643 0;
BA_ "GenSigAutoGenSnd" SG_ 1716 signal128643 1;
BA_ "GenSigAutoGenDsp" SG_ 1716 signal128643 1;
BA_ "GenSigTimeoutMsg_ecu12990" SG_ 1716 signal12822 1716;
BA_ "signal142834" SG_ 1716 signal12822 1716;
BA_ "NMH-WakeupAllowed" SG_ 1716 signal12822 0;
BA_ "NWM-WakeupAllowed" SG_ 1716 signal12822 0;
BA_ "GenSigSendType" SG_ 1716 signal12822 7;
BA_ "GenSigEnvVarType" SG_ 1716 signal12822 0;
BA_ "GenSigAutoGenSnd" SG_ 1716 signal12822 1;
BA_ "GenSigAutoGenDsp" SG_ 1716 signal12822 1;
BA_ "GenSigTimeoutMsg_ecu12990" SG_ 1716 signal12835 1716;
BA_ "signal142827" SG_ 1716 signal12835 1716;
BA_ "signal142834" SG_ 1716 signal12835 1716;
BA_ "NMH-WakeupAllowed" SG_ 1716 signal12835 0;
BA_ "NWM-WakeupAllowed" SG_ 1716 signal12835 0;
BA_ "GenSigSendType" SG_ 1716 signal12835 7;
BA_ "GenSigEnvVarType" SG_ 1716 signal12835 0;
BA_ "GenSigAutoGenSnd" SG_ 1716 signal12835 1;
BA_ "GenSigAutoGenDsp" SG_ 1716 signal12835 1;
BA_ "GenSigTimeoutMsg_ecu12990" SG_ 1716 signal12849 1716;
BA_ "signal142820" SG_ 1716 signal12849 1716;
BA_ "signal142827" SG_ 1716 signal12849 1716;
BA_ "signal142834" SG_ 1716 signal12849 1716;
BA_ "NMH-WakeupAllowed" SG_ 1716 signal12849 0;
BA_ "NWM-WakeupAllowed" SG_ 1716 signal12849 0;
BA_ "GenSigSendType" SG_ 1716 signal12849 7;
BA_ "GenSigEnvVarType" SG_ 1716 signal12849 0;
BA_ "GenSigAutoGenSnd" SG_ 1716 signal12849 1;
BA_ "GenSigAutoGenDsp" SG_ 1716 signal12849 1;
BA_ "GenSigTimeoutMsg_ecu12990" SG_ 1716 signal12864 1716;
BA_ "signal142827" SG_ 1716 signal12864 1716;
BA_ "signal142834" SG_ 1716 signal12864 1716;
BA_ "NMH-WakeupAllowed" SG_ 1716 signal12864 0;
BA_ "NWM-WakeupAllowed" SG_ 1716 signal12864 0;
BA_ "GenSigSendType" SG_ 1716 signal12864 7;
BA_ "GenSigEnvVarType" SG_ 1716 signal12864 0;
BA_ "GenSigAutoGenSnd" SG_ 1716 signal12864 1;
BA_ "GenSigAutoGenDsp" SG_ 1716 signal12864 1;
BA_ "GenSigTimeoutMsg_ecu12990" SG_ 1716 signal12878 1716;
BA_ "signal142827" SG_ 1716 signal12878 1716;
BA_ "signal142834" SG_ 1716 signal12878 1716;
BA_ "NMH-WakeupAllowed" SG_ 1716 signal12878 0;
BA_ "NWM-WakeupAllowed" SG_ 1716 signal12878 0;
BA_ "GenSigSendType" SG_ 1716 signal12878 7;
BA_ "GenSigEnvVarType" SG_ 1716 signal12878 0;
BA_ "GenSigAutoGenSnd" SG_ 1716 signal12878 1;
BA_ "GenSigAutoGenDsp" SG_ 1716 signal12878 1;
BA_ "GenSigTimeoutMsg_ecu12990" SG_ 1716 signal128645 1716;
BA_ "signal142820" SG_ 1716 signal128645 1716;
BA_ "signal142827" SG_ 1716 signal128645 1716;
BA_ "signal142834" SG_ 1716 signal128645 1716;
BA_ "NMH-WakeupAllowed" SG_ 1716 signal128645 0;
BA_ "NWM-WakeupAllowed" SG_ 1716 signal128645 0;
BA_ "GenSigSendType" SG_ 1716 signal128645 7;
BA_ "GenSigEnvVarType" SG_ 1716 signal128645 0;
BA_ "GenSigAutoGenSnd" SG_ 1716 signal128645 1;
BA_ "GenSigAutoGenDsp" SG_ 1716 signal128645 1;
BA_ "GenSigTimeoutMsg_ecu12990" SG_ 1716 signal12907 1716;
BA_ "signal142827" SG_ 1716 signal12907 1716;
BA_ "signal142834" SG_ 1716 signal12907 1716;
BA_ "NMH-WakeupAllowed" SG_ 1716 signal12907 0;
BA_ "NWM-WakeupAllowed" SG_ 1716 signal12907 0;
BA_ "GenSigSendType" SG_ 1716 signal12907 7;
BA_ "GenSigEnvVarType" SG_ 1716 signal12907 0;
BA_ "GenSigAutoGenSnd" SG_ 1716 signal12907 1;
BA_ "GenSigAutoGenDsp" SG_ 1716 signal12907 1;
BA_ "GenSigTimeoutMsg_ecu12990" SG_ 1716 signal12921 1716;
BA_ "signal142827" SG_ 1716 signal12921 1716;
BA_ "signal142834" SG_ 1716 signal12921 1716;
BA_ "NMH-WakeupAllowed" SG_ 1716 signal12921 0;
BA_ "NWM-WakeupAllowed" SG_ 1716 signal12921 0;
BA_ "GenSigSendType" SG_ 1716 signal12921 7;
BA_ "GenSigEnvVarType" SG_ 1716 signal12921 0;
BA_ "GenSigAutoGenSnd" SG_ 1716 signal12921 1;
BA_ "GenSigAutoGenDsp" SG_ 1716 signal12921 1;
BA_ "GenSigTimeoutMsg_ecu12990" SG_ 1716 signal128646 1716;
BA_ "signal142820" SG_ 1716 signal128646 1716;
BA_ "signal142827" SG_ 1716 signal128646 1716;
BA_ "signal142834" SG_ 1716 signal128646 1716;
BA_ "NMH-WakeupAllowed" SG_ 1716 signal128646 0;
BA_ "NWM-WakeupAllowed" SG_ 1716 signal128646 0;
BA_ "GenSigSendType" SG_ 1716 signal128646 7;
BA_ "GenSigEnvVarType" SG_ 1716 signal128646 0;
BA_ "GenSigAutoGenSnd" SG_ 1716 signal128646 1;
BA_ "GenSigAutoGenDsp" SG_ 1716 signal128646 1;
BA_ "GenSigTimeoutMsg_ecu12990" SG_ 1716 signal12950 1716;
BA_ "signal142827" SG_ 1716 signal12950 1716;
BA_ "signal142834" SG_ 1716 signal12950 1716;
BA_ "NMH-WakeupAllowed" SG_ 1716 signal12950 0;
BA_ "NWM-WakeupAllowed" SG_ 1716 signal12950 0;
BA_ "GenSigSendType" SG_ 1716 signal12950 7;
BA_ "GenSigEnvVarType" SG_ 1716 signal12950 0;
BA_ "GenSigAutoGenSnd" SG_ 1716 signal12950 1;
BA_ "GenSigAutoGenDsp" SG_ 1716 signal12950 1;
BA_ "GenSigTimeoutMsg_ecu12990" SG_ 1716 signal128640 1716;
BA_ "signal142827" SG_ 1716 signal128640 1716;
BA_ "signal142834" SG_ 1716 signal128640 1716;
BA_ "NMH-WakeupAllowed" SG_ 1716 signal128640 0;
BA_ "NWM-WakeupAllowed" SG_ 1716 signal128640 0;
BA_ "GenSigSendType" SG_ 1716 signal128640 7;
BA_ "GenSigEnvVarType" SG_ 1716 signal128640 0;
BA_ "GenSigAutoGenSnd" SG_ 1716 signal128640 1;
BA_ "GenSigAutoGenDsp" SG_ 1716 signal128640 1;
BA_ "GenSigTimeoutMsg_ecu12990" SG_ 1716 signal128647 1716;
BA_ "signal142820" SG_ 1716 signal128647 1716;
BA_ "signal142827" SG_ 1716 signal128647 1716;
BA_ "signal142834" SG_ 1716 signal128647 1716;
BA_ "NMH-WakeupAllowed" SG_ 1716 signal128647 0;
BA_ "NWM-WakeupAllowed" SG_ 1716 signal128647 0;
BA_ "GenSigSendType" SG_ 1716 signal128647 7;
BA_ "GenSigEnvVarType" SG_ 1716 signal128647 0;
BA_ "GenSigAutoGenSnd" SG_ 1716 signal128647 1;
BA_ "GenSigAutoGenDsp" SG_ 1716 signal128647 1;
BA_ "GenSigTimeoutMsg_ecu13186" SG_ 912 signal12999 912;
BA_ "NMH-WakeupAllowed" SG_ 912 signal12999 0;
BA_ "NWM-WakeupAllowed" SG_ 912 signal12999 0;
BA_ "GenSigSendType" SG_ 912 signal12999 7;
BA_ "GenSigEnvVarType" SG_ 912 signal12999 0;
BA_ "GenSigAutoGenSnd" SG_ 912 signal12999 1;
BA_ "GenSigAutoGenDsp" SG_ 912 signal12999 1;
BA_ "GenSigTimeoutMsg_ecu13186" SG_ 912 signal13011 912;
BA_ "NMH-WakeupAllowed" SG_ 912 signal13011 0;
BA_ "NWM-WakeupAllowed" SG_ 912 signal13011 0;
BA_ "GenSigSendType" SG_ 912 signal13011 7;
BA_ "GenSigEnvVarType" SG_ 912 signal13011 0;
BA_ "GenSigAutoGenSnd" SG_ 912 signal13011 1;
BA_ "GenSigAutoGenDsp" SG_ 912 signal13011 1;
BA_ "GenSigTimeoutMsg_ecu13186" SG_ 912 signal13023 912;
BA_ "NMH-WakeupAllowed" SG_ 912 signal13023 0;
BA_ "NWM-WakeupAllowed" SG_ 912 signal13023 0;
BA_ "GenSigSendType" SG_ 912 signal13023 7;
BA_ "GenSigEnvVarType" SG_ 912 signal13023 0;
BA_ "GenSigAutoGenSnd" SG_ 912 signal13023 1;
BA_ "GenSigAutoGenDsp" SG_ 912 signal13023 1;
BA_ "GenSigTimeoutMsg_ecu13186" SG_ 912 signal13035 912;
BA_ "NMH-WakeupAllowed" SG_ 912 signal13035 0;
BA_ "NWM-WakeupAllowed" SG_ 912 signal13035 0;
BA_ "GenSigSendType" SG_ 912 signal13035 7;
BA_ "GenSigEnvVarType" SG_ 912 signal13035 0;
BA_ "GenSigAutoGenSnd" SG_ 912 signal13035 1;
BA_ "GenSigAutoGenDsp" SG_ 912 signal13035 1;
BA_ "GenSigTimeoutMsg_ecu13186" SG_ 912 signal13047 912;
BA_ "NMH-WakeupAllowed" SG_ 912 signal13047 0;
BA_ "NWM-WakeupAllowed" SG_ 912 signal13047 0;
BA_ "GenSigStartValue" SG_ 912 signal13047 1;
BA_ "GenSigSendType" SG_ 912 signal13047 7;
BA_ "GenSigEnvVarType" SG_ 912 signal13047 0;
BA_ "GenSigAutoGenSnd" SG_ 912 signal13047 1;
BA_ "GenSigAutoGenDsp" SG_ 912 signal13047 1;
BA_ "GenSigTimeoutMsg_ecu13186" SG_ 912 signal13059 912;
BA_ "NMH-WakeupAllowed" SG_ 912 signal13059 0;
BA_ "NWM-WakeupAllowed" SG_ 912 signal13059 0;
BA_ "GenSigSendType" SG_ 912 signal13059 7;
BA_ "GenSigEnvVarType" SG_ 912 signal13059 0;
BA_ "GenSigAutoGenSnd" SG_ 912 signal13059 1;
BA_ "GenSigAutoGenDsp" SG_ 912 signal13059 1;
BA_ "GenSigTimeoutMsg_ecu13186" SG_ 912 signal13071 912;
BA_ "NMH-WakeupAllowed" SG_ 912 signal13071 0;
BA_ "NWM-WakeupAllowed" SG_ 912 signal13071 0;
BA_ "GenSigSendType" SG_ 912 signal13071 7;
BA_ "GenSigEnvVarType" SG_ 912 signal13071 0;
BA_ "GenSigAutoGenSnd" SG_ 912 signal13071 1;
BA_ "GenSigAutoGenDsp" SG_ 912 signal13071 1;
BA_ "GenSigTimeoutMsg_ecu13186" SG_ 912 signal13082 912;
BA_ "NMH-WakeupAllowed" SG_ 912 signal13082 0;
BA_ "NWM-WakeupAllowed" SG_ 912 signal13082 0;
BA_ "GenSigSendType" SG_ 912 signal13082 7;
BA_ "GenSigEnvVarType" SG_ 912 signal13082 0;
BA_ "GenSigAutoGenSnd" SG_ 912 signal13082 1;
BA_ "GenSigAutoGenDsp" SG_ 912 signal13082 1;
BA_ "GenSigTimeoutMsg_ecu13186" SG_ 912 signal13094 912;
BA_ "NMH-WakeupAllowed" SG_ 912 signal13094 0;
BA_ "NWM-WakeupAllowed" SG_ 912 signal13094 0;
BA_ "GenSigSendType" SG_ 912 signal13094 7;
BA_ "GenSigEnvVarType" SG_ 912 signal13094 0;
BA_ "GenSigAutoGenSnd" SG_ 912 signal13094 1;
BA_ "GenSigAutoGenDsp" SG_ 912 signal13094 1;
BA_ "GenSigTimeoutMsg_ecu13186" SG_ 912 signal13106 912;
BA_ "NMH-WakeupAllowed" SG_ 912 signal13106 0;
BA_ "NWM-WakeupAllowed" SG_ 912 signal13106 0;
BA_ "GenSigSendType" SG_ 912 signal13106 7;
BA_ "GenSigEVName" SG_ 912 signal13106 "@signame";
BA_ "GenSigAutoGenSnd" SG_ 912 signal13106 1;
BA_ "GenSigAutoGenDsp" SG_ 912 signal13106 1;
BA_ "GenSigTimeoutMsg_ecu13186" SG_ 1602 signal13123 1602;
BA_ "NMH-WakeupAllowed" SG_ 1602 signal13123 0;
BA_ "NWM-WakeupAllowed" SG_ 1602 signal13123 0;
BA_ "GenSigSendType" SG_ 1602 signal13123 7;
BA_ "GenSigEnvVarType" SG_ 1602 signal13123 1;
BA_ "GenSigAutoGenSnd" SG_ 1602 signal13123 1;
BA_ "GenSigAutoGenDsp" SG_ 1602 signal13123 1;
BA_ "GenSigTimeoutMsg_ecu13186" SG_ 1602 signal13134 1602;
BA_ "NMH-WakeupAllowed" SG_ 1602 signal13134 0;
BA_ "NWM-WakeupAllowed" SG_ 1602 signal13134 0;
BA_ "GenSigSendType" SG_ 1602 signal13134 7;
BA_ "GenSigEnvVarType" SG_ 1602 signal13134 1;
BA_ "GenSigAutoGenSnd" SG_ 1602 signal13134 1;
BA_ "GenSigAutoGenDsp" SG_ 1602 signal13134 1;
BA_ "GenSigTimeoutMsg_ecu13186" SG_ 1602 signal13145 1602;
BA_ "NMH-WakeupAllowed" SG_ 1602 signal13145 0;
BA_ "NWM-WakeupAllowed" SG_ 1602 signal13145 0;
BA_ "GenSigStartValue" SG_ 1602 signal13145 12;
BA_ "GenSigSendType" SG_ 1602 signal13145 7;
BA_ "GenSigEnvVarType" SG_ 1602 signal13145 0;
BA_ "GenSigAutoGenSnd" SG_ 1602 signal13145 1;
BA_ "GenSigAutoGenDsp" SG_ 1602 signal13145 1;
BA_ "GenSigTimeoutMsg_ecu13186" SG_ 1602 signal13156 1602;
BA_ "NMH-WakeupAllowed" SG_ 1602 signal13156 0;
BA_ "NWM-WakeupAllowed" SG_ 1602 signal13156 0;
BA_ "GenSigStartValue" SG_ 1602 signal13156 24;
BA_ "GenSigSendType" SG_ 1602 signal13156 7;
BA_ "GenSigEnvVarType" SG_ 1602 signal13156 0;
BA_ "GenSigAutoGenSnd" SG_ 1602 signal13156 1;
BA_ "GenSigAutoGenDsp" SG_ 1602 signal13156 1;
BA_ "GenSigTimeoutMsg_ecu13186" SG_ 1602 signal13167 1602;
BA_ "NMH-WakeupAllowed" SG_ 1602 signal13167 0;
BA_ "NWM-WakeupAllowed" SG_ 1602 signal13167 0;
BA_ "GenSigStartValue" SG_ 1602 signal13167 17;
BA_ "GenSigSendType" SG_ 1602 signal13167 7;
BA_ "GenSigEnvVarType" SG_ 1602 signal13167 0;
BA_ "GenSigAutoGenSnd" SG_ 1602 signal13167 1;
BA_ "GenSigAutoGenDsp" SG_ 1602 signal13167 1;
BA_ "GenSigTimeoutMsg_ecu13186" SG_ 1602 signal13178 1602;
BA_ "NMH-WakeupAllowed" SG_ 1602 signal13178 0;
BA_ "NWM-WakeupAllowed" SG_ 1602 signal13178 0;
BA_ "GenSigStartValue" SG_ 1602 signal13178 31;
BA_ "GenSigSendType" SG_ 1602 signal13178 7;
BA_ "GenSigEnvVarType" SG_ 1602 signal13178 0;
BA_ "GenSigAutoGenSnd" SG_ 1602 signal13178 1;
BA_ "GenSigAutoGenDsp" SG_ 1602 signal13178 1;
